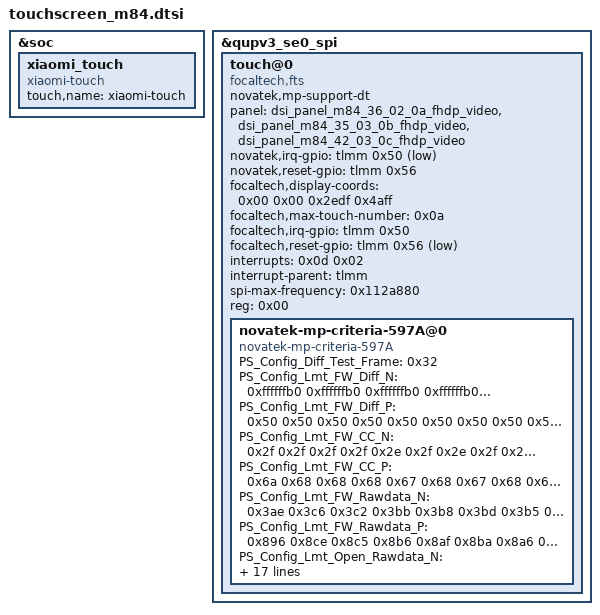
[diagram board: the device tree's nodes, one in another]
&soc {
    xiaomi_touch {
        touch,name = "xiaomi-touch";
        compatible = "xiaomi-touch";
        status = "okay";
    };
};

&qupv3_se0_spi {
    touch@0 {
        novatek,mp-support-dt;
        panel = <&dsi_panel_m84_36_02_0a_fhdp_video &dsi_panel_m84_35_03_0b_fhdp_video &dsi_panel_m84_42_03_0c_fhdp_video>;
        novatek,irq-gpio = <&tlmm 0x50 0x2001>;
        novatek,reset-gpio = <&tlmm 0x56 0x00>;
        focaltech,display-coords = <0x00 0x00 0x2edf 0x4aff>;
        focaltech,max-touch-number = <0x0a>;
        focaltech,irq-gpio = <&tlmm 0x50 0x02>;
        focaltech,reset-gpio = <&tlmm 0x56 0x01>;
        interrupts = <0x0d 0x02>;
        interrupt-parent = <&tlmm>;
        spi-max-frequency = <0x112a880>;
        status = "ok";
        reg = <0x00>;
        compatible = "focaltech,fts", "novatek,NVT-ts-spi";

        novatek-mp-criteria-597A@0 {
            PS_Config_Diff_Test_Frame = <0x32>;
            PS_Config_Lmt_FW_Diff_N = <0xffffffb0 0xffffffb0 0xffffffb0 0xffffffb0 0xffffffb0 0xffffffb0 0xffffffb0 0xffffffb0 0xffffffb0 0xffffffb0 0xffffffb0 0xffffffb0 0xffffffb0 0xffffffb0 0xffffffb0 0xffffffb0 0xffffffb0 0xffffffb0 0xffffffb0 0xffffffb0 0xffffffb0 0xffffffb0 0xffffffb0 0xffffffb0 0xffffffb0 0xffffffb0 0xffffffb0 0xffffffb0 0xffffffb0 0xffffffb0 0xffffffb0 0xffffffb0 0xffffffb0 0xffffffb0 0xffffffb0 0xffffffb0 0xffffffb0 0xffffffb0 0xffffffb0 0xffffffb0 0xffffffb0 0xffffffb0 0xffffffb0 0xffffffb0 0xffffffb0 0xffffffb0 0xffffffb0 0xffffffb0 0xffffffb0 0xffffffb0 0xffffffb0 0xffffffb0 0xffffffb0 0xffffffb0 0xffffffb0 0xffffffb0 0xffffffb0 0xffffffb0 0xffffffb0 0xffffffb0 0xffffffb0 0xffffffb0 0xffffffb0 0xffffffb0 0xffffffb0 0xffffffb0 0xffffffb0 0xffffffb0 0xffffffb0 0xffffffb0 0xffffffb0 0xffffffb0 0xffffffb0 0xffffffb0 0xffffffb0 0xffffffb0 0xffffffb0 0xffffffb0 0xffffffb0 0xffffffb0 0xffffffb0 0xffffffb0 0xffffffb0 0xffffffb0 0xffffffb0 0xffffffb0 0xffffffb0 0xffffffb0 0xffffffb0 0xffffffb0 0xffffffb0 0xffffffb0 0xffffffb0 0xffffffb0 0xffffffb0 0xffffffb0 0xffffffb0 0xffffffb0 0xffffffb0 0xffffffb0 0xffffffb0 0xffffffb0 0xffffffb0 0xffffffb0 0xffffffb0 0xffffffb0 0xffffffb0 0xffffffb0 0xffffffb0 0xffffffb0 0xffffffb0 0xffffffb0 0xffffffb0 0xffffffb0 0xffffffb0 0xffffffb0 0xffffffb0 0xffffffb0 0xffffffb0 0xffffffb0 0xffffffb0 0xffffffb0 0xffffffb0 0xffffffb0 0xffffffb0 0xffffffb0 0xffffffb0 0xffffffb0 0xffffffb0 0xffffffb0 0xffffffb0 0xffffffb0 0xffffffb0 0xffffffb0 0xffffffb0 0xffffffb0 0xffffffb0 0xffffffb0 0xffffffb0 0xffffffb0 0xffffffb0 0xffffffb0 0xffffffb0 0xffffffb0 0xffffffb0 0xffffffb0 0xffffffb0 0xffffffb0 0xffffffb0 0xffffffb0 0xffffffb0 0xffffffb0 0xffffffb0 0xffffffb0 0xffffffb0 0xffffffb0 0xffffffb0 0xffffffb0 0xffffffb0 0xffffffb0 0xffffffb0 0xffffffb0 0xffffffb0 0xffffffb0 0xffffffb0 0xffffffb0 0xffffffb0 0xffffffb0 0xffffffb0 0xffffffb0 0xffffffb0 0xffffffb0 0xffffffb0 0xffffffb0 0xffffffb0 0xffffffb0 0xffffffb0 0xffffffb0 0xffffffb0 0xffffffb0 0xffffffb0 0xffffffb0 0xffffffb0 0xffffffb0 0xffffffb0 0xffffffb0 0xffffffb0 0xffffffb0 0xffffffb0 0xffffffb0 0xffffffb0 0xffffffb0 0xffffffb0 0xffffffb0 0xffffffb0 0xffffffb0 0xffffffb0 0xffffffb0 0xffffffb0 0xffffffb0 0xffffffb0 0xffffffb0 0xffffffb0 0xffffffb0 0xffffffb0 0xffffffb0 0xffffffb0 0xffffffb0 0xffffffb0 0xffffffb0 0xffffffb0 0xffffffb0 0xffffffb0 0xffffffb0 0xffffffb0 0xffffffb0 0xffffffb0 0xffffffb0 0xffffffb0 0xffffffb0 0xffffffb0 0xffffffb0 0xffffffb0 0xffffffb0 0xffffffb0 0xffffffb0 0xffffffb0 0xffffffb0 0xffffffb0 0xffffffb0 0xffffffb0 0xffffffb0 0xffffffb0 0xffffffb0 0xffffffb0 0xffffffb0 0xffffffb0 0xffffffb0 0xffffffb0 0xffffffb0 0xffffffb0 0xffffffb0 0xffffffb0 0xffffffb0 0xffffffb0 0xffffffb0 0xffffffb0 0xffffffb0 0xffffffb0 0xffffffb0 0xffffffb0 0xffffffb0 0xffffffb0 0xffffffb0 0xffffffb0 0xffffffb0 0xffffffb0 0xffffffb0 0xffffffb0 0xffffffb0 0xffffffb0 0xffffffb0 0xffffffb0 0xffffffb0 0xffffffb0 0xffffffb0 0xffffffb0 0xffffffb0 0xffffffb0 0xffffffb0 0xffffffb0 0xffffffb0 0xffffffb0 0xffffffb0 0xffffffb0 0xffffffb0 0xffffffb0 0xffffffb0 0xffffffb0 0xffffffb0 0xffffffb0 0xffffffb0 0xffffffb0 0xffffffb0 0xffffffb0 0xffffffb0 0xffffffb0 0xffffffb0 0xffffffb0 0xffffffb0 0xffffffb0 0xffffffb0 0xffffffb0 0xffffffb0 0xffffffb0 0xffffffb0 0xffffffb0 0xffffffb0 0xffffffb0 0xffffffb0 0xffffffb0 0xffffffb0 0xffffffb0 0xffffffb0 0xffffffb0 0xffffffb0 0xffffffb0 0xffffffb0 0xffffffb0 0xffffffb0 0xffffffb0 0xffffffb0 0xffffffb0 0xffffffb0 0xffffffb0 0xffffffb0 0xffffffb0 0xffffffb0 0xffffffb0 0xffffffb0 0xffffffb0 0xffffffb0 0xffffffb0 0xffffffb0 0xffffffb0 0xffffffb0 0xffffffb0 0xffffffb0 0xffffffb0 0xffffffb0 0xffffffb0 0xffffffb0 0xffffffb0 0xffffffb0 0xffffffb0 0xffffffb0 0xffffffb0 0xffffffb0 0xffffffb0 0xffffffb0 0xffffffb0 0xffffffb0 0xffffffb0 0xffffffb0 0xffffffb0 0xffffffb0 0xffffffb0 0xffffffb0 0xffffffb0 0xffffffb0 0xffffffb0 0xffffffb0 0xffffffb0 0xffffffb0 0xffffffb0 0xffffffb0 0xffffffb0 0xffffffb0 0xffffffb0 0xffffffb0 0xffffffb0 0xffffffb0 0xffffffb0 0xffffffb0 0xffffffb0 0xffffffb0 0xffffffb0 0xffffffb0 0xffffffb0 0xffffffb0 0xffffffb0 0xffffffb0 0xffffffb0 0xffffffb0 0xffffffb0 0xffffffb0 0xffffffb0 0xffffffb0 0xffffffb0 0xffffffb0 0xffffffb0 0xffffffb0 0xffffffb0 0xffffffb0 0xffffffb0 0xffffffb0 0xffffffb0 0xffffffb0 0xffffffb0 0xffffffb0 0xffffffb0 0xffffffb0 0xffffffb0 0xffffffb0 0xffffffb0 0xffffffb0 0xffffffb0 0xffffffb0 0xffffffb0 0xffffffb0 0xffffffb0 0xffffffb0 0xffffffb0 0xffffffb0 0xffffffb0 0xffffffb0 0xffffffb0 0xffffffb0 0xffffffb0 0xffffffb0 0xffffffb0 0xffffffb0 0xffffffb0 0xffffffb0 0xffffffb0 0xffffffb0 0xffffffb0 0xffffffb0 0xffffffb0 0xffffffb0 0xffffffb0 0xffffffb0 0xffffffb0 0xffffffb0 0xffffffb0 0xffffffb0 0xffffffb0 0xffffffb0 0xffffffb0 0xffffffb0 0xffffffb0 0xffffffb0 0xffffffb0 0xffffffb0 0xffffffb0 0xffffffb0 0xffffffb0 0xffffffb0 0xffffffb0 0xffffffb0 0xffffffb0 0xffffffb0 0xffffffb0 0xffffffb0 0xffffffb0 0xffffffb0 0xffffffb0 0xffffffb0 0xffffffb0 0xffffffb0 0xffffffb0 0xffffffb0 0xffffffb0 0xffffffb0 0xffffffb0 0xffffffb0 0xffffffb0 0xffffffb0 0xffffffb0 0xffffffb0 0xffffffb0 0xffffffb0 0xffffffb0 0xffffffb0 0xffffffb0 0xffffffb0 0xffffffb0 0xffffffb0 0xffffffb0 0xffffffb0 0xffffffb0 0xffffffb0 0xffffffb0 0xffffffb0 0xffffffb0 0xffffffb0 0xffffffb0 0xffffffb0 0xffffffb0 0xffffffb0 0xffffffb0 0xffffffb0 0xffffffb0 0xffffffb0 0xffffffb0 0xffffffb0 0xffffffb0 0xffffffb0 0xffffffb0 0xffffffb0 0xffffffb0 0xffffffb0 0xffffffb0 0xffffffb0 0xffffffb0 0xffffffb0 0xffffffb0 0xffffffb0 0xffffffb0 0xffffffb0 0xffffffb0 0xffffffb0 0xffffffb0 0xffffffb0 0xffffffb0 0xffffffb0 0xffffffb0 0xffffffb0 0xffffffb0 0xffffffb0 0xffffffb0 0xffffffb0 0xffffffb0 0xffffffb0 0xffffffb0 0xffffffb0 0xffffffb0 0xffffffb0 0xffffffb0 0xffffffb0 0xffffffb0 0xffffffb0 0xffffffb0 0xffffffb0 0xffffffb0 0xffffffb0 0xffffffb0 0xffffffb0 0xffffffb0 0xffffffb0 0xffffffb0 0xffffffb0 0xffffffb0 0xffffffb0 0xffffffb0 0xffffffb0 0xffffffb0 0xffffffb0 0xffffffb0 0xffffffb0 0xffffffb0 0xffffffb0 0xffffffb0 0xffffffb0 0xffffffb0 0xffffffb0 0xffffffb0 0xffffffb0 0xffffffb0 0xffffffb0 0xffffffb0 0xffffffb0 0xffffffb0 0xffffffb0 0xffffffb0 0xffffffb0 0xffffffb0 0xffffffb0 0xffffffb0 0xffffffb0 0xffffffb0 0xffffffb0 0xffffffb0 0xffffffb0 0xffffffb0 0xffffffb0 0xffffffb0 0xffffffb0 0xffffffb0 0xffffffb0 0xffffffb0 0xffffffb0 0xffffffb0 0xffffffb0 0xffffffb0 0xffffffb0 0xffffffb0 0xffffffb0 0xffffffb0 0xffffffb0 0xffffffb0 0xffffffb0 0xffffffb0 0xffffffb0 0xffffffb0 0xffffffb0 0xffffffb0 0xffffffb0 0xffffffb0 0xffffffb0 0xffffffb0 0xffffffb0 0xffffffb0 0xffffffb0 0xffffffb0 0xffffffb0 0xffffffb0 0xffffffb0 0xffffffb0 0xffffffb0 0xffffffb0 0xffffffb0 0xffffffb0 0xffffffb0 0xffffffb0 0xffffffb0 0xffffffb0 0xffffffb0 0xffffffb0 0xffffffb0 0xffffffb0 0xffffffb0 0xffffffb0 0xffffffb0 0xffffffb0 0xffffffb0 0xffffffb0 0xffffffb0 0xffffffb0 0xffffffb0 0xffffffb0 0xffffffb0 0xffffffb0 0xffffffb0 0xffffffb0 0xffffffb0 0xffffffb0 0xffffffb0 0xffffffb0 0xffffffb0 0xffffffb0 0xffffffb0 0xffffffb0 0xffffffb0 0xffffffb0 0xffffffb0 0xffffffb0 0xffffffb0 0xffffffb0 0xffffffb0 0xffffffb0 0xffffffb0 0xffffffb0 0xffffffb0 0xffffffb0 0xffffffb0 0xffffffb0 0xffffffb0 0xffffffb0 0xffffffb0 0xffffffb0 0xffffffb0 0xffffffb0 0xffffffb0 0xffffffb0 0xffffffb0 0xffffffb0 0xffffffb0 0xffffffb0 0xffffffb0 0xffffffb0 0xffffffb0 0xffffffb0 0xffffffb0 0xffffffb0 0xffffffb0 0xffffffb0 0xffffffb0 0xffffffb0 0xffffffb0 0xffffffb0 0xffffffb0 0xffffffb0 0xffffffb0 0xffffffb0 0xffffffb0 0xffffffb0 0xffffffb0 0xffffffb0 0xffffffb0 0xffffffb0 0xffffffb0 0xffffffb0 0xffffffb0 0xffffffb0 0xffffffb0 0xffffffb0 0xffffffb0 0xffffffb0 0xffffffb0 0xffffffb0 0xffffffb0 0xffffffb0 0xffffffb0 0xffffffb0 0xffffffb0 0xffffffb0 0xffffffb0 0xffffffb0 0xffffffb0 0xffffffb0 0xffffffb0 0xffffffb0 0xffffffb0 0xffffffb0 0xffffffb0 0xffffffb0 0xffffffb0 0xffffffb0 0xffffffb0 0xffffffb0 0xffffffb0 0xffffffb0 0xffffffb0 0xffffffb0 0xffffffb0 0xffffffb0 0xffffffb0 0xffffffb0 0xffffffb0 0xffffffb0 0xffffffb0 0xffffffb0 0xffffffb0 0xffffffb0 0xffffffb0 0xffffffb0 0xffffffb0 0xffffffb0 0xffffffb0 0xffffffb0 0xffffffb0 0xffffffb0 0xffffffb0 0xffffffb0 0xffffffb0 0xffffffb0 0xffffffb0 0xffffffb0 0xffffffb0 0xffffffb0 0xffffffb0 0xffffffb0 0xffffffb0 0xffffffb0 0xffffffb0 0xffffffb0 0xffffffb0 0xffffffb0 0xffffffb0 0xffffffb0 0xffffffb0 0xffffffb0 0xffffffb0 0xffffffb0 0xffffffb0 0xffffffb0 0xffffffb0 0xffffffb0 0xffffffb0 0xffffffb0 0xffffffb0 0xffffffb0 0xffffffb0 0xffffffb0 0xffffffb0 0xffffffb0 0xffffffb0 0xffffffb0 0xffffffb0 0xffffffb0 0xffffffb0 0xffffffb0 0xffffffb0 0xffffffb0 0xffffffb0 0xffffffb0 0xffffffb0 0xffffffb0 0xffffffb0 0xffffffb0 0xffffffb0 0xffffffb0 0xffffffb0 0xffffffb0 0xffffffb0 0xffffffb0 0xffffffb0 0xffffffb0 0xffffffb0 0xffffffb0 0xffffffb0 0xffffffb0 0xffffffb0 0xffffffb0 0xffffffb0 0xffffffb0 0xffffffb0 0xffffffb0 0xffffffb0 0xffffffb0 0xffffffb0 0xffffffb0 0xffffffb0 0xffffffb0 0xffffffb0 0xffffffb0 0xffffffb0 0xffffffb0 0xffffffb0 0xffffffb0 0xffffffb0 0xffffffb0 0xffffffb0 0xffffffb0 0xffffffb0 0xffffffb0 0xffffffb0 0xffffffb0 0xffffffb0 0xffffffb0 0xffffffb0 0xffffffb0 0xffffffb0 0xffffffb0 0xffffffb0 0xffffffb0 0xffffffb0 0xffffffb0 0xffffffb0 0xffffffb0 0xffffffb0 0xffffffb0 0xffffffb0 0xffffffb0 0xffffffb0 0xffffffb0 0xffffffb0 0xffffffb0 0xffffffb0 0xffffffb0 0xffffffb0 0xffffffb0 0xffffffb0 0xffffffb0 0xffffffb0 0xffffffb0 0xffffffb0 0xffffffb0 0xffffffb0 0xffffffb0 0xffffffb0 0xffffffb0 0xffffffb0 0xffffffb0 0xffffffb0 0xffffffb0 0xffffffb0 0xffffffb0 0xffffffb0 0xffffffb0 0xffffffb0 0xffffffb0 0xffffffb0 0xffffffb0 0xffffffb0 0xffffffb0 0xffffffb0 0xffffffb0 0xffffffb0 0xffffffb0 0xffffffb0 0xffffffb0 0xffffffb0 0xffffffb0 0xffffffb0 0xffffffb0 0xffffffb0 0xffffffb0 0xffffffb0 0xffffffb0 0xffffffb0 0xffffffb0 0xffffffb0 0xffffffb0 0xffffffb0 0xffffffb0 0xffffffb0 0xffffffb0 0xffffffb0 0xffffffb0 0xffffffb0 0xffffffb0 0xffffffb0 0xffffffb0 0xffffffb0 0xffffffb0 0xffffffb0 0xffffffb0 0xffffffb0 0xffffffb0 0xffffffb0 0xffffffb0 0xffffffb0 0xffffffb0 0xffffffb0 0xffffffb0 0xffffffb0 0xffffffb0 0xffffffb0 0xffffffb0 0xffffffb0 0xffffffb0 0xffffffb0 0xffffffb0 0xffffffb0 0xffffffb0 0xffffffb0 0xffffffb0 0xffffffb0 0xffffffb0 0xffffffb0 0xffffffb0 0xffffffb0 0xffffffb0 0xffffffb0 0xffffffb0 0xffffffb0 0xffffffb0 0xffffffb0 0xffffffb0 0xffffffb0 0xffffffb0 0xffffffb0 0xffffffb0 0xffffffb0 0xffffffb0 0xffffffb0 0xffffffb0 0xffffffb0 0xffffffb0 0xffffffb0 0xffffffb0 0xffffffb0 0xffffffb0 0xffffffb0 0xffffffb0 0xffffffb0 0xffffffb0 0xffffffb0 0xffffffb0 0xffffffb0 0xffffffb0 0xffffffb0 0xffffffb0 0xffffffb0 0xffffffb0 0xffffffb0 0xffffffb0 0xffffffb0 0xffffffb0 0xffffffb0 0xffffffb0 0xffffffb0 0xffffffb0 0xffffffb0 0xffffffb0 0xffffffb0 0xffffffb0 0xffffffb0 0xffffffb0 0xffffffb0 0xffffffb0 0xffffffb0 0xffffffb0 0xffffffb0 0xffffffb0 0xffffffb0 0xffffffb0 0xffffffb0 0xffffffb0 0xffffffb0 0xffffffb0 0xffffffb0 0xffffffb0 0xffffffb0 0xffffffb0 0xffffffb0 0xffffffb0 0xffffffb0 0xffffffb0 0xffffffb0 0xffffffb0 0xffffffb0 0xffffffb0 0xffffffb0 0xffffffb0 0xffffffb0 0xffffffb0 0xffffffb0 0xffffffb0 0xffffffb0 0xffffffb0 0xffffffb0 0xffffffb0 0xffffffb0 0xffffffb0 0xffffffb0 0xffffffb0 0xffffffb0 0xffffffb0 0xffffffb0 0xffffffb0 0xffffffb0 0xffffffb0 0xffffffb0 0xffffffb0 0xffffffb0 0xffffffb0 0xffffffb0 0xffffffb0 0xffffffb0 0xffffffb0 0xffffffb0 0xffffffb0 0xffffffb0 0xffffffb0 0xffffffb0 0xffffffb0 0xffffffb0 0xffffffb0 0xffffffb0 0xffffffb0 0xffffffb0 0xffffffb0 0xffffffb0 0xffffffb0 0xffffffb0 0xffffffb0 0xffffffb0 0xffffffb0 0xffffffb0 0xffffffb0 0xffffffb0 0xffffffb0 0xffffffb0 0xffffffb0 0xffffffb0 0xffffffb0 0xffffffb0 0xffffffb0 0xffffffb0 0xffffffb0 0xffffffb0 0xffffffb0 0xffffffb0 0xffffffb0 0xffffffb0 0xffffffb0 0xffffffb0 0xffffffb0 0xffffffb0 0xffffffb0 0xffffffb0 0xffffffb0 0xffffffb0 0xffffffb0 0xffffffb0 0xffffffb0 0xffffffb0 0xffffffb0 0xffffffb0 0xffffffb0 0xffffffb0 0xffffffb0 0xffffffb0 0xffffffb0 0xffffffb0 0xffffffb0 0xffffffb0 0xffffffb0 0xffffffb0 0xffffffb0 0xffffffb0 0xffffffb0 0xffffffb0 0xffffffb0 0xffffffb0 0xffffffb0 0xffffffb0 0xffffffb0 0xffffffb0 0xffffffb0 0xffffffb0 0xffffffb0 0xffffffb0 0xffffffb0 0xffffffb0 0xffffffb0 0xffffffb0 0xffffffb0 0xffffffb0 0xffffffb0 0xffffffb0 0xffffffb0 0xffffffb0 0xffffffb0 0xffffffb0 0xffffffb0 0xffffffb0 0xffffffb0 0xffffffb0 0xffffffb0 0xffffffb0 0xffffffb0 0xffffffb0 0xffffffb0 0xffffffb0 0xffffffb0 0xffffffb0 0xffffffb0 0xffffffb0 0xffffffb0 0xffffffb0 0xffffffb0 0xffffffb0 0xffffffb0 0xffffffb0 0xffffffb0 0xffffffb0 0xffffffb0 0xffffffb0 0xffffffb0 0xffffffb0 0xffffffb0 0xffffffb0 0xffffffb0 0xffffffb0 0xffffffb0 0xffffffb0 0xffffffb0 0xffffffb0 0xffffffb0 0xffffffb0 0xffffffb0 0xffffffb0 0xffffffb0 0xffffffb0 0xffffffb0 0xffffffb0 0xffffffb0 0xffffffb0 0xffffffb0 0xffffffb0 0xffffffb0 0xffffffb0 0xffffffb0 0xffffffb0 0xffffffb0 0xffffffb0 0xffffffb0 0xffffffb0 0xffffffb0 0xffffffb0 0xffffffb0 0xffffffb0 0xffffffb0 0xffffffb0 0xffffffb0 0xffffffb0 0xffffffb0 0xffffffb0 0xffffffb0 0xffffffb0 0xffffffb0 0xffffffb0 0xffffffb0 0xffffffb0 0xffffffb0 0xffffffb0 0xffffffb0 0xffffffb0 0xffffffb0 0xffffffb0 0xffffffb0 0xffffffb0 0xffffffb0 0xffffffb0 0xffffffb0 0xffffffb0 0xffffffb0 0xffffffb0 0xffffffb0 0xffffffb0 0xffffffb0 0xffffffb0 0xffffffb0 0xffffffb0 0xffffffb0 0xffffffb0 0xffffffb0 0xffffffb0 0xffffffb0 0xffffffb0 0xffffffb0 0xffffffb0 0xffffffb0 0xffffffb0 0xffffffb0 0xffffffb0 0xffffffb0 0xffffffb0 0xffffffb0 0xffffffb0 0xffffffb0 0xffffffb0 0xffffffb0 0xffffffb0 0xffffffb0 0xffffffb0 0xffffffb0 0xffffffb0 0xffffffb0 0xffffffb0 0xffffffb0 0xffffffb0 0xffffffb0 0xffffffb0 0xffffffb0 0xffffffb0 0xffffffb0 0xffffffb0 0xffffffb0 0xffffffb0 0xffffffb0 0xffffffb0 0xffffffb0 0xffffffb0 0xffffffb0 0xffffffb0 0xffffffb0 0xffffffb0 0xffffffb0 0xffffffb0 0xffffffb0 0xffffffb0 0xffffffb0 0xffffffb0 0xffffffb0 0xffffffb0 0xffffffb0 0xffffffb0 0xffffffb0 0xffffffb0 0xffffffb0 0xffffffb0 0xffffffb0 0xffffffb0 0xffffffb0 0xffffffb0 0xffffffb0 0xffffffb0 0xffffffb0 0xffffffb0 0xffffffb0 0xffffffb0 0xffffffb0 0xffffffb0 0xffffffb0 0xffffffb0 0xffffffb0 0xffffffb0 0xffffffb0 0xffffffb0 0xffffffb0 0xffffffb0 0xffffffb0 0xffffffb0 0xffffffb0 0xffffffb0 0xffffffb0 0xffffffb0 0xffffffb0 0xffffffb0 0xffffffb0 0xffffffb0 0xffffffb0 0xffffffb0 0xffffffb0 0xffffffb0 0xffffffb0 0xffffffb0 0xffffffb0 0xffffffb0 0xffffffb0 0xffffffb0 0xffffffb0 0xffffffb0 0xffffffb0 0xffffffb0 0xffffffb0 0xffffffb0 0xffffffb0 0xffffffb0 0xffffffb0 0xffffffb0 0xffffffb0 0xffffffb0 0xffffffb0 0xffffffb0 0xffffffb0 0xffffffb0 0xffffffb0 0xffffffb0 0xffffffb0 0xffffffb0 0xffffffb0 0xffffffb0 0xffffffb0 0xffffffb0 0xffffffb0 0xffffffb0 0xffffffb0 0xffffffb0 0xffffffb0 0xffffffb0 0xffffffb0 0xffffffb0 0xffffffb0 0xffffffb0 0xffffffb0 0xffffffb0 0xffffffb0 0xffffffb0 0xffffffb0 0xffffffb0 0xffffffb0 0xffffffb0 0xffffffb0 0xffffffb0 0xffffffb0 0xffffffb0 0xffffffb0 0xffffffb0 0xffffffb0 0xffffffb0 0xffffffb0 0xffffffb0 0xffffffb0 0xffffffb0 0xffffffb0 0xffffffb0 0xffffffb0 0xffffffb0 0xffffffb0 0xffffffb0 0xffffffb0 0xffffffb0 0xffffffb0 0xffffffb0 0xffffffb0 0xffffffb0 0xffffffb0 0xffffffb0 0xffffffb0 0xffffffb0 0xffffffb0 0xffffffb0 0xffffffb0 0xffffffb0 0xffffffb0 0xffffffb0 0xffffffb0 0xffffffb0 0xffffffb0 0xffffffb0 0xffffffb0 0xffffffb0 0xffffffb0 0xffffffb0 0xffffffb0 0xffffffb0 0xffffffb0 0xffffffb0 0xffffffb0 0xffffffb0 0xffffffb0 0xffffffb0 0xffffffb0 0xffffffb0 0xffffffb0 0xffffffb0 0xffffffb0 0xffffffb0 0xffffffb0 0xffffffb0 0xffffffb0 0xffffffb0 0xffffffb0 0xffffffb0 0xffffffb0 0xffffffb0 0xffffffb0 0xffffffb0 0xffffffb0 0xffffffb0 0xffffffb0 0xffffffb0 0xffffffb0 0xffffffb0 0xffffffb0 0xffffffb0 0xffffffb0 0xffffffb0 0xffffffb0 0xffffffb0 0xffffffb0 0xffffffb0 0xffffffb0 0xffffffb0 0xffffffb0 0xffffffb0 0xffffffb0 0xffffffb0 0xffffffb0 0xffffffb0 0xffffffb0 0xffffffb0 0xffffffb0 0xffffffb0 0xffffffb0 0xffffffb0 0xffffffb0 0xffffffb0 0xffffffb0 0xffffffb0 0xffffffb0 0xffffffb0 0xffffffb0 0xffffffb0 0xffffffb0 0xffffffb0 0xffffffb0 0xffffffb0 0xffffffb0 0xffffffb0 0xffffffb0 0xffffffb0 0xffffffb0 0xffffffb0 0xffffffb0 0xffffffb0 0xffffffb0 0xffffffb0 0xffffffb0 0xffffffb0 0xffffffb0 0xffffffb0 0xffffffb0 0xffffffb0 0xffffffb0 0xffffffb0 0xffffffb0 0xffffffb0 0xffffffb0 0xffffffb0 0xffffffb0 0xffffffb0 0xffffffb0 0xffffffb0 0xffffffb0 0xffffffb0 0xffffffb0 0xffffffb0 0xffffffb0 0xffffffb0 0xffffffb0 0xffffffb0 0xffffffb0 0xffffffb0 0xffffffb0 0xffffffb0 0xffffffb0 0xffffffb0 0xffffffb0 0xffffffb0 0xffffffb0 0xffffffb0 0xffffffb0 0xffffffb0 0xffffffb0 0xffffffb0 0xffffffb0 0xffffffb0 0xffffffb0 0xffffffb0 0xffffffb0 0xffffffb0 0xffffffb0 0xffffffb0 0xffffffb0 0xffffffb0 0xffffffb0 0xffffffb0 0xffffffb0 0xffffffb0 0xffffffb0 0xffffffb0 0xffffffb0 0xffffffb0 0xffffffb0 0xffffffb0 0xffffffb0 0xffffffb0 0xffffffb0 0xffffffb0 0xffffffb0 0xffffffb0 0xffffffb0 0xffffffb0 0xffffffb0 0xffffffb0 0xffffffb0 0xffffffb0 0xffffffb0 0xffffffb0 0xffffffb0 0xffffffb0 0xffffffb0 0xffffffb0 0xffffffb0 0xffffffb0 0xffffffb0 0xffffffb0 0xffffffb0 0xffffffb0 0xffffffb0 0xffffffb0 0xffffffb0 0xffffffb0 0xffffffb0 0xffffffb0 0xffffffb0 0xffffffb0 0xffffffb0 0xffffffb0 0xffffffb0 0xffffffb0 0xffffffb0 0xffffffb0 0xffffffb0 0xffffffb0 0xffffffb0 0xffffffb0 0xffffffb0 0xffffffb0 0xffffffb0 0xffffffb0 0xffffffb0 0xffffffb0 0xffffffb0 0xffffffb0 0xffffffb0 0xffffffb0 0xffffffb0 0xffffffb0 0xffffffb0 0xffffffb0 0xffffffb0 0xffffffb0 0xffffffb0 0xffffffb0 0xffffffb0 0xffffffb0 0xffffffb0 0xffffffb0 0xffffffb0 0xffffffb0 0xffffffb0 0xffffffb0 0xffffffb0 0xffffffb0 0xffffffb0 0xffffffb0 0xffffffb0 0xffffffb0 0xffffffb0 0xffffffb0 0xffffffb0 0xffffffb0 0xffffffb0 0xffffffb0 0xffffffb0 0xffffffb0 0xffffffb0 0xffffffb0 0xffffffb0 0xffffffb0 0xffffffb0 0xffffffb0 0xffffffb5 0xffffffb5 0xffffffb5>;
            PS_Config_Lmt_FW_Diff_P = <0x50 0x50 0x50 0x50 0x50 0x50 0x50 0x50 0x50 0x50 0x50 0x50 0x50 0x50 0x50 0x50 0x50 0x50 0x50 0x50 0x50 0x50 0x50 0x50 0x50 0x50 0x50 0x50 0x50 0x50 0x50 0x50 0x50 0x50 0x50 0x50 0x50 0x50 0x50 0x50 0x50 0x50 0x50 0x50 0x50 0x50 0x50 0x50 0x50 0x50 0x50 0x50 0x50 0x50 0x50 0x50 0x50 0x50 0x50 0x50 0x50 0x50 0x50 0x50 0x50 0x50 0x50 0x50 0x50 0x50 0x50 0x50 0x50 0x50 0x50 0x50 0x50 0x50 0x50 0x50 0x50 0x50 0x50 0x50 0x50 0x50 0x50 0x50 0x50 0x50 0x50 0x50 0x50 0x50 0x50 0x50 0x50 0x50 0x50 0x50 0x50 0x50 0x50 0x50 0x50 0x50 0x50 0x50 0x50 0x50 0x50 0x50 0x50 0x50 0x50 0x50 0x50 0x50 0x50 0x50 0x50 0x50 0x50 0x50 0x50 0x50 0x50 0x50 0x50 0x50 0x50 0x50 0x50 0x50 0x50 0x50 0x50 0x50 0x50 0x50 0x50 0x50 0x50 0x50 0x50 0x50 0x50 0x50 0x50 0x50 0x50 0x50 0x50 0x50 0x50 0x50 0x50 0x50 0x50 0x50 0x50 0x50 0x50 0x50 0x50 0x50 0x50 0x50 0x50 0x50 0x50 0x50 0x50 0x50 0x50 0x50 0x50 0x50 0x50 0x50 0x50 0x50 0x50 0x50 0x50 0x50 0x50 0x50 0x50 0x50 0x50 0x50 0x50 0x50 0x50 0x50 0x50 0x50 0x50 0x50 0x50 0x50 0x50 0x50 0x50 0x50 0x50 0x50 0x50 0x50 0x50 0x50 0x50 0x50 0x50 0x50 0x50 0x50 0x50 0x50 0x50 0x50 0x50 0x50 0x50 0x50 0x50 0x50 0x50 0x50 0x50 0x50 0x50 0x50 0x50 0x50 0x50 0x50 0x50 0x50 0x50 0x50 0x50 0x50 0x50 0x50 0x50 0x50 0x50 0x50 0x50 0x50 0x50 0x50 0x50 0x50 0x50 0x50 0x50 0x50 0x50 0x50 0x50 0x50 0x50 0x50 0x50 0x50 0x50 0x50 0x50 0x50 0x50 0x50 0x50 0x50 0x50 0x50 0x50 0x50 0x50 0x50 0x50 0x50 0x50 0x50 0x50 0x50 0x50 0x50 0x50 0x50 0x50 0x50 0x50 0x50 0x50 0x50 0x50 0x50 0x50 0x50 0x50 0x50 0x50 0x50 0x50 0x50 0x50 0x50 0x50 0x50 0x50 0x50 0x50 0x50 0x50 0x50 0x50 0x50 0x50 0x50 0x50 0x50 0x50 0x50 0x50 0x50 0x50 0x50 0x50 0x50 0x50 0x50 0x50 0x50 0x50 0x50 0x50 0x50 0x50 0x50 0x50 0x50 0x50 0x50 0x50 0x50 0x50 0x50 0x50 0x50 0x50 0x50 0x50 0x50 0x50 0x50 0x50 0x50 0x50 0x50 0x50 0x50 0x50 0x50 0x50 0x50 0x50 0x50 0x50 0x50 0x50 0x50 0x50 0x50 0x50 0x50 0x50 0x50 0x50 0x50 0x50 0x50 0x50 0x50 0x50 0x50 0x50 0x50 0x50 0x50 0x50 0x50 0x50 0x50 0x50 0x50 0x50 0x50 0x50 0x50 0x50 0x50 0x50 0x50 0x50 0x50 0x50 0x50 0x50 0x50 0x50 0x50 0x50 0x50 0x50 0x50 0x50 0x50 0x50 0x50 0x50 0x50 0x50 0x50 0x50 0x50 0x50 0x50 0x50 0x50 0x50 0x50 0x50 0x50 0x50 0x50 0x50 0x50 0x50 0x50 0x50 0x50 0x50 0x50 0x50 0x50 0x50 0x50 0x50 0x50 0x50 0x50 0x50 0x50 0x50 0x50 0x50 0x50 0x50 0x50 0x50 0x50 0x50 0x50 0x50 0x50 0x50 0x50 0x50 0x50 0x50 0x50 0x50 0x50 0x50 0x50 0x50 0x50 0x50 0x50 0x50 0x50 0x50 0x50 0x50 0x50 0x50 0x50 0x50 0x50 0x50 0x50 0x50 0x50 0x50 0x50 0x50 0x50 0x50 0x50 0x50 0x50 0x50 0x50 0x50 0x50 0x50 0x50 0x50 0x50 0x50 0x50 0x50 0x50 0x50 0x50 0x50 0x50 0x50 0x50 0x50 0x50 0x50 0x50 0x50 0x50 0x50 0x50 0x50 0x50 0x50 0x50 0x50 0x50 0x50 0x50 0x50 0x50 0x50 0x50 0x50 0x50 0x50 0x50 0x50 0x50 0x50 0x50 0x50 0x50 0x50 0x50 0x50 0x50 0x50 0x50 0x50 0x50 0x50 0x50 0x50 0x50 0x50 0x50 0x50 0x50 0x50 0x50 0x50 0x50 0x50 0x50 0x50 0x50 0x50 0x50 0x50 0x50 0x50 0x50 0x50 0x50 0x50 0x50 0x50 0x50 0x50 0x50 0x50 0x50 0x50 0x50 0x50 0x50 0x50 0x50 0x50 0x50 0x50 0x50 0x50 0x50 0x50 0x50 0x50 0x50 0x50 0x50 0x50 0x50 0x50 0x50 0x50 0x50 0x50 0x50 0x50 0x50 0x50 0x50 0x50 0x50 0x50 0x50 0x50 0x50 0x50 0x50 0x50 0x50 0x50 0x50 0x50 0x50 0x50 0x50 0x50 0x50 0x50 0x50 0x50 0x50 0x50 0x50 0x50 0x50 0x50 0x50 0x50 0x50 0x50 0x50 0x50 0x50 0x50 0x50 0x50 0x50 0x50 0x50 0x50 0x50 0x50 0x50 0x50 0x50 0x50 0x50 0x50 0x50 0x50 0x50 0x50 0x50 0x50 0x50 0x50 0x50 0x50 0x50 0x50 0x50 0x50 0x50 0x50 0x50 0x50 0x50 0x50 0x50 0x50 0x50 0x50 0x50 0x50 0x50 0x50 0x50 0x50 0x50 0x50 0x50 0x50 0x50 0x50 0x50 0x50 0x50 0x50 0x50 0x50 0x50 0x50 0x50 0x50 0x50 0x50 0x50 0x50 0x50 0x50 0x50 0x50 0x50 0x50 0x50 0x50 0x50 0x50 0x50 0x50 0x50 0x50 0x50 0x50 0x50 0x50 0x50 0x50 0x50 0x50 0x50 0x50 0x50 0x50 0x50 0x50 0x50 0x50 0x50 0x50 0x50 0x50 0x50 0x50 0x50 0x50 0x50 0x50 0x50 0x50 0x50 0x50 0x50 0x50 0x50 0x50 0x50 0x50 0x50 0x50 0x50 0x50 0x50 0x50 0x50 0x50 0x50 0x50 0x50 0x50 0x50 0x50 0x50 0x50 0x50 0x50 0x50 0x50 0x50 0x50 0x50 0x50 0x50 0x50 0x50 0x50 0x50 0x50 0x50 0x50 0x50 0x50 0x50 0x50 0x50 0x50 0x50 0x50 0x50 0x50 0x50 0x50 0x50 0x50 0x50 0x50 0x50 0x50 0x50 0x50 0x50 0x50 0x50 0x50 0x50 0x50 0x50 0x50 0x50 0x50 0x50 0x50 0x50 0x50 0x50 0x50 0x50 0x50 0x50 0x50 0x50 0x50 0x50 0x50 0x50 0x50 0x50 0x50 0x50 0x50 0x50 0x50 0x50 0x50 0x50 0x50 0x50 0x50 0x50 0x50 0x50 0x50 0x50 0x50 0x50 0x50 0x50 0x50 0x50 0x50 0x50 0x50 0x50 0x50 0x50 0x50 0x50 0x50 0x50 0x50 0x50 0x50 0x50 0x50 0x50 0x50 0x50 0x50 0x50 0x50 0x50 0x50 0x50 0x50 0x50 0x50 0x50 0x50 0x50 0x50 0x50 0x50 0x50 0x50 0x50 0x50 0x50 0x50 0x50 0x50 0x50 0x50 0x50 0x50 0x50 0x50 0x50 0x50 0x50 0x50 0x50 0x50 0x50 0x50 0x50 0x50 0x50 0x50 0x50 0x50 0x50 0x50 0x50 0x50 0x50 0x50 0x50 0x50 0x50 0x50 0x50 0x50 0x50 0x50 0x50 0x50 0x50 0x50 0x50 0x50 0x50 0x50 0x50 0x50 0x50 0x50 0x50 0x50 0x50 0x50 0x50 0x50 0x50 0x50 0x50 0x50 0x50 0x50 0x50 0x50 0x50 0x50 0x50 0x50 0x50 0x50 0x50 0x50 0x50 0x50 0x50 0x50 0x50 0x50 0x50 0x50 0x50 0x50 0x50 0x50 0x50 0x50 0x50 0x50 0x50 0x50 0x50 0x50 0x50 0x50 0x50 0x50 0x50 0x50 0x50 0x50 0x50 0x50 0x50 0x50 0x50 0x50 0x50 0x50 0x50 0x50 0x50 0x50 0x50 0x50 0x50 0x50 0x50 0x50 0x50 0x50 0x50 0x50 0x50 0x50 0x50 0x50 0x50 0x50 0x50 0x50 0x50 0x50 0x50 0x50 0x50 0x50 0x50 0x50 0x50 0x50 0x50 0x50 0x50 0x50 0x50 0x50 0x50 0x50 0x50 0x50 0x50 0x50 0x50 0x50 0x50 0x50 0x50 0x50 0x50 0x50 0x50 0x50 0x50 0x50 0x50 0x50 0x50 0x50 0x50 0x50 0x50 0x50 0x50 0x50 0x50 0x50 0x50 0x50 0x50 0x50 0x50 0x50 0x50 0x50 0x50 0x50 0x50 0x50 0x50 0x50 0x50 0x50 0x50 0x50 0x50 0x50 0x50 0x50 0x50 0x50 0x50 0x50 0x50 0x50 0x50 0x50 0x50 0x50 0x50 0x50 0x50 0x50 0x50 0x50 0x50 0x50 0x50 0x50 0x50 0x50 0x50 0x50 0x50 0x50 0x50 0x50 0x50 0x50 0x50 0x50 0x50 0x50 0x50 0x50 0x50 0x50 0x50 0x50 0x50 0x50 0x50 0x50 0x50 0x50 0x50 0x50 0x50 0x50 0x50 0x50 0x50 0x50 0x50 0x50 0x50 0x50 0x50 0x50 0x50 0x50 0x50 0x50 0x50 0x50 0x50 0x50 0x50 0x50 0x50 0x50 0x50 0x50 0x50 0x50 0x50 0x50 0x50 0x50 0x50 0x50 0x50 0x50 0x50 0x50 0x50 0x50 0x50 0x50 0x50 0x50 0x50 0x50 0x50 0x50 0x50 0x50 0x50 0x50 0x50 0x50 0x50 0x50 0x50 0x50 0x50 0x50 0x50 0x50 0x50 0x50 0x50 0x50 0x50 0x50 0x50 0x50 0x50 0x50 0x50 0x50 0x50 0x50 0x50 0x50 0x50 0x50 0x50 0x50 0x50 0x50 0x50 0x50 0x50 0x50 0x50 0x50 0x50 0x50 0x50 0x50 0x50 0x50 0x50 0x50 0x50 0x50 0x50 0x50 0x50 0x50 0x50 0x50 0x50 0x50 0x50 0x50 0x50 0x50 0x50 0x50 0x50 0x50 0x50 0x50 0x50 0x50 0x50 0x50 0x50 0x50 0x50 0x50 0x50 0x50 0x50 0x50 0x50 0x50 0x50 0x50 0x50 0x50 0x50 0x50 0x50 0x50 0x50 0x50 0x50 0x50 0x50 0x50 0x50 0x50 0x50 0x50 0x50 0x50 0x50 0x50 0x50 0x50 0x50 0x50 0x50 0x50 0x50 0x50 0x50 0x50 0x50 0x50 0x50 0x50 0x50 0x50 0x50 0x50 0x50 0x50 0x50 0x50 0x50 0x50 0x50 0x50 0x50 0x50 0x50 0x50 0x50 0x50 0x50 0x50 0x50 0x50 0x50 0x50 0x50 0x50 0x50 0x50 0x50 0x50 0x50 0x50 0x50 0x50 0x50 0x50 0x50 0x50 0x50 0x50 0x50 0x50 0x50 0x50 0x50 0x50 0x50 0x50 0x50 0x50 0x50 0x50 0x50 0x50 0x50 0x50 0x50 0x50 0x50 0x50 0x50 0x50 0x50 0x50 0x50 0x50 0x50 0x50 0x50 0x50 0x50 0x50 0x50 0x50 0x50 0x50 0x50 0x50 0x50 0x50 0x50 0x50 0x50 0x50 0x50 0x50 0x50 0x50 0x50 0x50 0x50 0x50 0x50 0x50 0x50 0x50 0x50 0x50 0x50 0x50 0x50 0x50 0x50 0x50 0x50 0x50 0x50 0x50 0x50 0x50 0x50 0x50 0x50 0x50 0x50 0x50 0x50 0x50 0x50 0x50 0x50 0x50 0x50 0x50 0x50 0x50 0x50 0x50 0x50 0x50 0x50 0x50 0x50 0x50 0x50 0x50 0x50 0x50 0x50 0x50 0x50 0x50 0x50 0x50 0x50 0x50 0x50 0x50 0x50 0x50 0x50 0x50 0x50 0x50 0x50 0x50 0x50 0x50 0x50 0x50 0x50 0x50 0x50 0x50 0x50 0x50 0x50 0x50 0x50 0x50 0x50 0x50 0x50 0x50 0x50 0x50 0x50 0x50 0x50 0x50 0x50 0x50 0x50 0x50 0x50 0x50 0x50 0x50 0x50 0x50 0x50 0x50 0x50 0x50 0x50 0x50 0x50 0x50 0x50 0x50 0x50 0x50 0x50 0x50 0x50 0x50 0x50 0x50 0x50 0x50 0x50 0x50 0x50 0x50 0x50 0x50 0x50 0x50 0x50 0x50 0x50 0x50 0x50 0x50 0x50 0x50 0x50 0x50 0x50 0x50 0x50 0x50 0x50 0x50 0x50 0x50 0x50 0x50 0x50 0x50 0x50 0x50 0x50 0x50 0x50 0x50 0x50 0x50 0x50 0x50 0x50 0x50 0x50 0x50 0x50 0x50 0x50 0x50 0x50 0x50 0x50 0x50 0x50 0x50 0x50 0x50 0x50 0x50 0x50 0x50 0x50 0x50 0x50 0x50 0x50 0x50 0x50 0x4b 0x4b 0x4b>;
            PS_Config_Lmt_FW_CC_N = <0x2f 0x2f 0x2f 0x2f 0x2e 0x2f 0x2e 0x2f 0x2e 0x2f 0x2f 0x2f 0x2e 0x2f 0x2f 0x2f 0x2f 0x2f 0x2f 0x2f 0x2f 0x2f 0x2f 0x2f 0x2f 0x2f 0x2f 0x2f 0x2f 0x2f 0x2f 0x30 0x2f 0x2d 0x2d 0x2e 0x2d 0x2d 0x2d 0x2d 0x2d 0x2e 0x2e 0x2e 0x2d 0x2e 0x2e 0x2e 0x2f 0x2f 0x2e 0x2f 0x2f 0x2f 0x2e 0x2f 0x2e 0x2e 0x2d 0x2e 0x2e 0x2e 0x2e 0x2f 0x2f 0x2f 0x2f 0x2f 0x2e 0x2f 0x2e 0x2f 0x2e 0x2f 0x2f 0x2f 0x2e 0x2f 0x2f 0x2f 0x2f 0x2f 0x2f 0x2f 0x2f 0x2f 0x2f 0x2f 0x2f 0x2f 0x2f 0x2f 0x2f 0x2f 0x2f 0x2f 0x2f 0x2e 0x2d 0x2e 0x2d 0x2e 0x2d 0x2e 0x2e 0x2e 0x2e 0x2f 0x2e 0x2f 0x2f 0x2f 0x2f 0x2f 0x2f 0x2f 0x2f 0x2f 0x2f 0x2f 0x2f 0x2e 0x2e 0x2e 0x2f 0x2e 0x2e 0x2f 0x2f 0x2e 0x2d 0x2e 0x2d 0x2d 0x2d 0x2e 0x2e 0x2e 0x2e 0x2e 0x2e 0x2e 0x2e 0x2e 0x2e 0x2f 0x2e 0x2e 0x2e 0x2f 0x2e 0x2e 0x2e 0x2e 0x2e 0x2e 0x2e 0x2e 0x2e 0x2f 0x2e 0x2d 0x2d 0x2d 0x2d 0x2d 0x2d 0x2d 0x2d 0x2d 0x2d 0x2d 0x2d 0x2d 0x2d 0x2e 0x2e 0x2e 0x2e 0x2e 0x2e 0x2e 0x2e 0x2d 0x2d 0x2d 0x2d 0x2d 0x2d 0x2d 0x2d 0x2d 0x2f 0x2f 0x2f 0x2f 0x2f 0x2e 0x2e 0x2e 0x2e 0x2e 0x2e 0x2f 0x2f 0x2e 0x2e 0x2e 0x2f 0x2f 0x2f 0x2f 0x2f 0x2f 0x2f 0x2f 0x2f 0x2f 0x2f 0x2f 0x2f 0x2f 0x2f 0x30 0x2f 0x2d 0x2d 0x2e 0x2e 0x2e 0x2d 0x2d 0x2e 0x2e 0x2e 0x2e 0x2e 0x2e 0x2e 0x2e 0x2f 0x2f 0x2f 0x2f 0x2f 0x2f 0x2e 0x2f 0x2e 0x2f 0x2e 0x2f 0x2e 0x2f 0x2e 0x2f 0x2f 0x2f 0x2f 0x2f 0x2e 0x2e 0x2e 0x2f 0x2e 0x2f 0x2f 0x2f 0x2f 0x2f 0x2f 0x2f 0x2f 0x2f 0x2f 0x2f 0x2f 0x2f 0x2f 0x2f 0x2f 0x2f 0x2f 0x2f 0x2f 0x2f 0x2f 0x2f 0x2f 0x2e 0x2d 0x2e 0x2d 0x2e 0x2d 0x2e 0x2e 0x2e 0x2e 0x2f 0x2f 0x2f 0x2f 0x2f 0x2f 0x2f 0x2f 0x2f 0x2f 0x2f 0x2f 0x2f 0x2f 0x2f 0x2e 0x2e 0x2e 0x2f 0x2e 0x2f 0x2f 0x2e 0x2d 0x2d 0x2e 0x2e 0x2d 0x2d 0x2e 0x2e 0x2e 0x2d 0x2e 0x2e 0x2e 0x2d 0x2e 0x2e 0x2e 0x2f 0x2e 0x2e 0x2e 0x2e 0x2e 0x2e 0x2e 0x2f 0x2e 0x2e 0x2e 0x2f 0x2e 0x2d 0x2d 0x2d 0x2d 0x2d 0x2d 0x2d 0x2d 0x2d 0x2d 0x2d 0x2d 0x2e 0x2d 0x2d 0x2e 0x2e 0x2e 0x2f 0x2e 0x2e 0x2e 0x2e 0x2d 0x2d 0x2d 0x2e 0x2d 0x2d 0x2d 0x2e 0x2f 0x2f 0x2e 0x2e 0x2e 0x2e 0x2d 0x2e 0x2e 0x2e 0x2e 0x2e 0x2e 0x2e 0x2e 0x2e 0x2f 0x2f 0x2f 0x2f 0x2f 0x2f 0x2f 0x2e 0x2f 0x2f 0x2f 0x2f 0x2f 0x2f 0x2f 0x2f 0x2f 0x2d 0x2d 0x2d 0x2d 0x2d 0x2d 0x2d 0x2d 0x2e 0x2d 0x2e 0x2e 0x2e 0x2e 0x2e 0x2f 0x2f 0x2e 0x2f 0x2f 0x2f 0x2e 0x2e 0x2e 0x2e 0x2e 0x2e 0x2e 0x2e 0x2e 0x2e 0x2f 0x2f 0x2f 0x2f 0x2e 0x2f 0x2e 0x2f 0x2e 0x2f 0x2f 0x2f 0x2e 0x2e 0x2f 0x2f 0x2f 0x2f 0x2f 0x2f 0x2f 0x2f 0x2f 0x2f 0x2f 0x2f 0x2f 0x2f 0x2f 0x2f 0x2f 0x2f 0x2e 0x2e 0x2d 0x2e 0x2d 0x2d 0x2d 0x2e 0x2e 0x2e 0x2e 0x2f 0x2e 0x2e 0x2f 0x2f 0x2f 0x2f 0x2f 0x2f 0x2f 0x2f 0x2f 0x2f 0x2e 0x2e 0x2e 0x2e 0x2e 0x2f 0x2e 0x2f 0x2e 0x2e 0x2d 0x2e 0x2d 0x2d 0x2d 0x2e 0x2d 0x2d 0x2e 0x2e 0x2d 0x2d 0x2e 0x2d 0x2d 0x2e 0x2e 0x2f 0x2e 0x2e 0x2e 0x2e 0x2e 0x2e 0x2e 0x2e 0x2e 0x2e 0x2e 0x2f 0x2e 0x2d 0x2d 0x2d 0x2d 0x2d 0x2d 0x2d 0x2d 0x2d 0x2d 0x2d 0x2d 0x2d 0x2d 0x2d 0x2d 0x2e 0x2e 0x2e 0x2d 0x2e 0x2d 0x2e 0x2d 0x2d 0x2d 0x2d 0x2d 0x2d 0x2d 0x2e 0x2e 0x2e 0x2e 0x2e 0x2d 0x2e 0x2d 0x2e 0x2e 0x2e 0x2e 0x2e 0x2e 0x2e 0x2e 0x2e 0x2f 0x2e 0x2f 0x2e 0x2f 0x2e 0x2f 0x2e 0x2f 0x2e 0x2f 0x2e 0x2f 0x2e 0x2f 0x2f 0x2e 0x2d 0x2d 0x2d 0x2d 0x2d 0x2d 0x2d 0x2d 0x2d 0x2d 0x2e 0x2d 0x2d 0x2d 0x2e 0x2f 0x2e 0x2f 0x2e 0x2e 0x2e 0x2e 0x2d 0x2e 0x2d 0x2e 0x2d 0x2e 0x2d 0x2e 0x2e 0x2f 0x2f 0x2f 0x2f 0x2e 0x2f 0x2e 0x2e 0x2e 0x2f 0x2e 0x2e 0x2e 0x2f 0x2e 0x2e 0x2e 0x2f 0x2f 0x2e 0x2e 0x2f 0x2f 0x2e 0x2e 0x2e 0x2f 0x2f 0x2f 0x2f 0x2f 0x2f 0x2f 0x2e 0x2d 0x2d 0x2d 0x2e 0x2d 0x2d 0x2d 0x2e 0x2e 0x2e 0x2e 0x2e 0x2e 0x2e 0x2e 0x2e 0x2f 0x2e 0x2e 0x2e 0x2e 0x2d 0x2e 0x2d 0x2e 0x2e 0x2e 0x2e 0x2f 0x2f 0x2f 0x2f 0x2f 0x2f 0x2f 0x2f 0x2f 0x2f 0x2e 0x2f 0x2f 0x2f 0x2e 0x2f 0x2f 0x2e 0x2f 0x2f 0x2f 0x2f 0x2f 0x2f 0x2f 0x2f 0x2f 0x2f 0x2f 0x2f 0x2f 0x2f 0x2f 0x2f 0x2e 0x2e 0x2e 0x2e 0x2d 0x2e 0x2e 0x2e 0x2e 0x2e 0x2f 0x2e 0x2e 0x2f 0x2f 0x2e 0x2f 0x2f 0x2e 0x2f 0x2f 0x2f 0x2e 0x2f 0x2e 0x2e 0x2e 0x2e 0x2e 0x2e 0x2e 0x2f 0x2e 0x2d 0x2e 0x2e 0x2d 0x2d 0x2e 0x2e 0x2d 0x2d 0x2e 0x2e 0x2d 0x2d 0x2e 0x2d 0x2e 0x2e 0x2e 0x2e 0x2e 0x2e 0x2e 0x2e 0x2e 0x2d 0x2e 0x2e 0x2e 0x2e 0x2f 0x2f 0x2e 0x2d 0x2d 0x2d 0x2d 0x2d 0x2d 0x2d 0x2d 0x2d 0x2d 0x2d 0x2d 0x2d 0x2d 0x2d 0x2d 0x2d 0x2e 0x2d 0x2d 0x2d 0x2e 0x2d 0x2d 0x2d 0x2d 0x2d 0x2d 0x2d 0x2d 0x2e 0x2f 0x2e 0x2e 0x2e 0x2e 0x2e 0x2e 0x2e 0x2e 0x2e 0x2e 0x2e 0x2e 0x2e 0x2e 0x2e 0x2e 0x2f 0x2e 0x2e 0x2e 0x2f 0x2f 0x2e 0x2e 0x2e 0x2e 0x2e 0x2e 0x2f 0x2f 0x2f 0x2e 0x2d 0x2d 0x2d 0x2d 0x2d 0x2d 0x2d 0x2d 0x2d 0x2e 0x2e 0x2e 0x2d 0x2e 0x2e 0x2e 0x2e 0x2e 0x2e 0x2e 0x2e 0x2e 0x2d 0x2d 0x2d 0x2d 0x2d 0x2d 0x2d 0x2e 0x2f 0x2f 0x2f 0x2f 0x2f 0x2f 0x2e 0x2e 0x2e 0x2e 0x2e 0x2e 0x2e 0x2e 0x2e 0x2e 0x2e 0x2f 0x2e 0x2e 0x2e 0x2f 0x2e 0x2e 0x2e 0x2f 0x2e 0x2e 0x2f 0x2f 0x2f 0x2f 0x2f 0x2f 0x2d 0x2e 0x2e 0x2d 0x2d 0x2d 0x2d 0x2e 0x2d 0x2e 0x2e 0x2e 0x2d 0x2e 0x2e 0x2e 0x2e 0x2e 0x2e 0x2e 0x2e 0x2d 0x2d 0x2e 0x2d 0x2d 0x2d 0x2e 0x2e 0x2e 0x2f 0x2f 0x2f 0x2f 0x2f 0x2e 0x2f 0x2e 0x2e 0x2f 0x2e 0x2f 0x2e 0x2e 0x2e 0x2e 0x2e 0x2e 0x2e 0x2f 0x2f 0x2f 0x2e 0x2f 0x2f 0x2e 0x2e 0x2f 0x2f 0x2f 0x2f 0x2f 0x2f 0x2f 0x2e 0x2d 0x2d 0x2d 0x2e 0x2d 0x2e 0x2e 0x2e 0x2e 0x2e 0x2e 0x2e 0x2e 0x2e 0x2e 0x2e 0x2f 0x2e 0x2e 0x2e 0x2f 0x2e 0x2e 0x2d 0x2e 0x2e 0x2e 0x2e 0x2e 0x2f 0x2e 0x2d 0x2d 0x2e 0x2d 0x2d 0x2d 0x2d 0x2d 0x2d 0x2d 0x2e 0x2d 0x2d 0x2d 0x2d 0x2d 0x2d 0x2e 0x2d 0x2d 0x2d 0x2e 0x2d 0x2d 0x2d 0x2e 0x2e 0x2d 0x2e 0x2f 0x2f 0x2d 0x2d 0x2c 0x2d 0x2d 0x2d 0x2d 0x2d 0x2d 0x2d 0x2d 0x2d 0x2d 0x2d 0x2d 0x2d 0x2d 0x2d 0x2e 0x2d 0x2d 0x2d 0x2d 0x2d 0x2d 0x2d 0x2d 0x2d 0x2d 0x2d 0x2d 0x2f 0x2f 0x2d 0x2e 0x2e 0x2e 0x2d 0x2e 0x2e 0x2e 0x2d 0x2e 0x2e 0x2e 0x2d 0x2d 0x2e 0x2e 0x2f 0x2e 0x2e 0x2f 0x2f 0x2e 0x2e 0x2e 0x2f 0x2e 0x2e 0x2f 0x2f 0x2e 0x2f 0x2e 0x2d 0x2d 0x2d 0x2d 0x2d 0x2d 0x2d 0x2d 0x2d 0x2d 0x2e 0x2d 0x2d 0x2d 0x2e 0x2e 0x2e 0x2d 0x2e 0x2e 0x2e 0x2d 0x2d 0x2d 0x2e 0x2d 0x2d 0x2d 0x2e 0x2d 0x2f 0x2f 0x2e 0x2f 0x2e 0x2f 0x2d 0x2e 0x2e 0x2e 0x2d 0x2e 0x2e 0x2e 0x2d 0x2d 0x2d 0x2e 0x2e 0x2e 0x2e 0x2f 0x2e 0x2e 0x2e 0x2f 0x2e 0x2e 0x2e 0x2f 0x2f 0x2f 0x2f 0x2e 0x2d 0x2d 0x2d 0x2d 0x2d 0x2d 0x2d 0x2d 0x2d 0x2d 0x2d 0x2d 0x2d 0x2d 0x2d 0x2e 0x2e 0x2d 0x2d 0x2e 0x2e 0x2d 0x2d 0x2e 0x2d 0x2d 0x2d 0x2e 0x2e 0x2e 0x2f 0x2f 0x2f 0x2f 0x2f 0x2e 0x2e 0x2e 0x2e 0x2e 0x2e 0x2e 0x2e 0x2e 0x2e 0x2e 0x2e 0x2f 0x2e 0x2f 0x2f 0x2f 0x2f 0x2f 0x2f 0x2f 0x2e 0x2f 0x2f 0x2f 0x2f 0x2f 0x2f 0x2e 0x2d 0x2d 0x2d 0x2d 0x2d 0x2d 0x2d 0x2d 0x2d 0x2e 0x2e 0x2d 0x2d 0x2e 0x2e 0x2e 0x2e 0x2e 0x2e 0x2e 0x2e 0x2e 0x2e 0x2e 0x2d 0x2e 0x2d 0x2e 0x2e 0x2e 0x2f 0x2e 0x2e 0x2d 0x2d 0x2d 0x2d 0x2d 0x2d 0x2d 0x2d 0x2d 0x2d 0x2d 0x2d 0x2d 0x2d 0x2d 0x2d 0x2d 0x2d 0x2d 0x2d 0x2d 0x2d 0x2d 0x2d 0x2d 0x2e 0x2d 0x2d 0x2e 0x2f 0x2d 0x2d 0x2d 0x2c 0x2d 0x2d 0x2d 0x2c 0x2d 0x2d 0x2d 0x2d 0x2d 0x2d 0x2d 0x2d 0x2d 0x2d 0x2d 0x2d 0x2d 0x2d 0x2d 0x2d 0x2d 0x2d 0x2d 0x2d 0x2d 0x2d 0x2d 0x2f 0x2e 0x2e 0x2e 0x2d 0x2d 0x2e 0x2d 0x2d 0x2d 0x2d 0x2d 0x2d 0x2d 0x2d 0x2d 0x2d 0x2e 0x2e 0x2e 0x2d 0x2e 0x2e 0x2e 0x2d 0x2e 0x2e 0x2e 0x2d 0x2e 0x2f 0x2f 0x2f 0x2d 0x2d 0x2d 0x2c 0x2c 0x2d 0x2d 0x2d 0x2d 0x2d 0x2d 0x2d 0x2d 0x2d 0x2d 0x2d 0x2d 0x2d 0x2e 0x2d 0x2d 0x2d 0x2d 0x2d 0x2d 0x2d 0x2d 0x2d 0x2d 0x2d 0x2d 0x2f 0x2f 0x2f 0x2f 0x2e 0x2e 0x2e 0x2e 0x2d 0x2d 0x2d 0x2e 0x2d 0x2d 0x2d 0x2e 0x2d 0x2e 0x2e 0x2e 0x2e 0x2e 0x2e 0x2e 0x2e 0x2e 0x2d 0x2f 0x2f 0x2f 0x2f 0x2f 0x2f 0x2d 0x2d 0x2d 0x2d 0x2d 0x2d 0x2d 0x2d 0x2d 0x2d 0x2d 0x2d 0x2d 0x2d 0x2d 0x2d 0x2d 0x2d 0x2e 0x2d 0x2d 0x2d 0x2d 0x2d 0x2d 0x2d 0x2d 0x2d 0x2d 0x2d 0x2e 0x2f 0x2f 0x2f 0x2f 0x2e 0x2e 0x2e 0x2e 0x2e 0x2e 0x2e 0x2e 0x2e 0x2e 0x2e 0x2e 0x2e 0x2f 0x2e 0x2f 0x2e 0x2f 0x2e 0x2f 0x2e 0x2f 0x2e 0x2f 0x2e 0x2f 0x2f 0x2f 0x2f 0x2d 0x2d 0x2d 0x2d 0x2d 0x2d 0x2d 0x2d 0x2d 0x2d 0x2d 0x2d 0x2d 0x2d 0x2e 0x2d 0x2e 0x2d 0x2e 0x2d 0x2e 0x2d 0x2e 0x2d 0x2d 0x2d 0x2d 0x2d 0x2e 0x2d 0x2e 0x2f 0x2e 0x2d 0x2d 0x2d 0x2d 0x2d 0x2d 0x2d 0x2d 0x2d 0x2d 0x2d 0x2d 0x2d 0x2d 0x2d 0x2d 0x2d 0x2d 0x2d 0x2e 0x2d 0x2d 0x2d 0x2d 0x2d 0x2d 0x2d 0x2e 0x2e 0x2e 0x2f 0x2d 0x2c 0x2c 0x2d 0x2d 0x2c 0x2d 0x2d 0x2d 0x2d 0x2d 0x2d 0x2d 0x2d 0x2d 0x2d 0x2d 0x2d 0x2d 0x2d 0x2d 0x2d 0x2d 0x2d 0x2d 0x2d 0x2d 0x2c 0x2d 0x2d 0x2d 0x2f 0x00 0x00 0x00>;
            PS_Config_Lmt_FW_CC_P = <0x6a 0x68 0x68 0x68 0x67 0x68 0x67 0x68 0x67 0x68 0x68 0x68 0x67 0x68 0x68 0x68 0x6a 0x6a 0x68 0x6a 0x6a 0x6a 0x68 0x6a 0x68 0x68 0x68 0x6a 0x6a 0x6a 0x68 0x6b 0x68 0x66 0x66 0x67 0x64 0x66 0x66 0x66 0x66 0x67 0x67 0x67 0x66 0x67 0x67 0x67 0x6a 0x68 0x67 0x68 0x68 0x68 0x67 0x68 0x67 0x67 0x66 0x67 0x67 0x67 0x67 0x68 0x68 0x68 0x68 0x68 0x67 0x68 0x67 0x68 0x67 0x68 0x68 0x68 0x67 0x68 0x68 0x68 0x6a 0x6a 0x68 0x6a 0x6a 0x6a 0x68 0x68 0x6a 0x68 0x68 0x68 0x6a 0x6a 0x68 0x6a 0x68 0x67 0x66 0x67 0x66 0x67 0x66 0x67 0x67 0x67 0x67 0x68 0x67 0x68 0x68 0x68 0x6a 0x6a 0x68 0x6a 0x6a 0x68 0x68 0x68 0x68 0x67 0x67 0x67 0x68 0x67 0x67 0x68 0x68 0x67 0x66 0x67 0x66 0x66 0x66 0x67 0x67 0x67 0x67 0x67 0x67 0x67 0x67 0x67 0x67 0x68 0x67 0x67 0x67 0x68 0x67 0x67 0x67 0x67 0x67 0x67 0x67 0x67 0x67 0x68 0x67 0x64 0x64 0x64 0x64 0x64 0x64 0x66 0x66 0x66 0x66 0x66 0x66 0x66 0x66 0x67 0x67 0x67 0x67 0x67 0x67 0x67 0x67 0x66 0x66 0x66 0x66 0x66 0x66 0x66 0x66 0x66 0x6a 0x68 0x68 0x68 0x68 0x67 0x67 0x67 0x67 0x67 0x67 0x68 0x68 0x67 0x67 0x67 0x68 0x6a 0x68 0x6a 0x68 0x6a 0x68 0x6a 0x68 0x6a 0x68 0x6a 0x68 0x6a 0x6a 0x6b 0x6a 0x66 0x66 0x67 0x67 0x67 0x66 0x66 0x67 0x67 0x67 0x67 0x67 0x67 0x67 0x67 0x68 0x6a 0x68 0x68 0x68 0x6a 0x67 0x68 0x67 0x68 0x67 0x68 0x67 0x68 0x67 0x68 0x68 0x68 0x68 0x68 0x67 0x67 0x67 0x68 0x67 0x68 0x68 0x68 0x68 0x68 0x68 0x68 0x6a 0x6a 0x68 0x68 0x6a 0x6a 0x68 0x68 0x68 0x68 0x68 0x68 0x68 0x6a 0x6a 0x6a 0x68 0x67 0x66 0x67 0x66 0x67 0x66 0x67 0x67 0x67 0x67 0x68 0x68 0x68 0x68 0x68 0x68 0x6a 0x68 0x68 0x68 0x68 0x68 0x68 0x68 0x68 0x67 0x67 0x67 0x68 0x67 0x68 0x68 0x67 0x66 0x66 0x67 0x67 0x66 0x66 0x67 0x67 0x67 0x66 0x67 0x67 0x67 0x66 0x67 0x67 0x67 0x68 0x67 0x67 0x67 0x67 0x67 0x67 0x67 0x68 0x67 0x67 0x67 0x68 0x67 0x64 0x64 0x64 0x64 0x66 0x64 0x64 0x66 0x66 0x66 0x66 0x66 0x67 0x66 0x66 0x67 0x67 0x67 0x68 0x67 0x67 0x67 0x67 0x66 0x66 0x66 0x67 0x66 0x64 0x66 0x67 0x68 0x68 0x67 0x67 0x67 0x67 0x66 0x67 0x67 0x67 0x67 0x67 0x67 0x67 0x67 0x67 0x68 0x68 0x68 0x68 0x68 0x68 0x68 0x67 0x68 0x68 0x68 0x68 0x6a 0x68 0x6a 0x6a 0x68 0x66 0x66 0x66 0x66 0x66 0x64 0x66 0x66 0x67 0x66 0x67 0x67 0x67 0x67 0x67 0x68 0x68 0x67 0x68 0x68 0x68 0x67 0x67 0x67 0x67 0x67 0x67 0x67 0x67 0x67 0x67 0x68 0x68 0x68 0x68 0x67 0x68 0x67 0x68 0x67 0x68 0x68 0x68 0x67 0x67 0x68 0x68 0x68 0x68 0x68 0x6a 0x68 0x6a 0x68 0x68 0x68 0x68 0x68 0x68 0x68 0x6a 0x6a 0x6a 0x67 0x67 0x66 0x67 0x66 0x66 0x66 0x67 0x67 0x67 0x67 0x68 0x67 0x67 0x68 0x68 0x68 0x68 0x68 0x68 0x68 0x68 0x68 0x68 0x67 0x67 0x67 0x67 0x67 0x68 0x67 0x68 0x67 0x67 0x66 0x67 0x66 0x66 0x66 0x67 0x66 0x66 0x67 0x67 0x66 0x66 0x67 0x66 0x66 0x67 0x67 0x68 0x67 0x67 0x67 0x67 0x67 0x67 0x67 0x67 0x67 0x67 0x67 0x68 0x67 0x64 0x64 0x64 0x64 0x64 0x64 0x66 0x64 0x66 0x66 0x66 0x66 0x66 0x66 0x66 0x66 0x67 0x67 0x67 0x66 0x67 0x66 0x67 0x66 0x66 0x64 0x66 0x64 0x66 0x66 0x67 0x67 0x67 0x67 0x67 0x66 0x67 0x66 0x67 0x67 0x67 0x67 0x67 0x67 0x67 0x67 0x67 0x68 0x67 0x68 0x67 0x68 0x67 0x68 0x67 0x68 0x67 0x68 0x67 0x68 0x67 0x68 0x68 0x67 0x66 0x64 0x66 0x64 0x66 0x66 0x66 0x66 0x66 0x66 0x67 0x66 0x66 0x66 0x67 0x68 0x67 0x68 0x67 0x67 0x67 0x67 0x66 0x67 0x66 0x67 0x66 0x67 0x66 0x67 0x67 0x68 0x6a 0x68 0x68 0x67 0x68 0x67 0x67 0x67 0x68 0x67 0x67 0x67 0x68 0x67 0x67 0x67 0x68 0x68 0x67 0x67 0x68 0x68 0x67 0x67 0x67 0x68 0x68 0x68 0x68 0x6a 0x6a 0x68 0x67 0x66 0x66 0x66 0x67 0x66 0x66 0x66 0x67 0x67 0x67 0x67 0x67 0x67 0x67 0x67 0x67 0x68 0x67 0x67 0x67 0x67 0x66 0x67 0x66 0x67 0x67 0x67 0x67 0x68 0x68 0x68 0x6a 0x68 0x68 0x68 0x68 0x68 0x68 0x67 0x68 0x68 0x68 0x67 0x68 0x68 0x67 0x68 0x68 0x68 0x6a 0x68 0x68 0x68 0x68 0x68 0x68 0x68 0x68 0x68 0x6a 0x68 0x6a 0x67 0x67 0x67 0x67 0x66 0x67 0x67 0x67 0x67 0x67 0x68 0x67 0x67 0x68 0x68 0x67 0x68 0x68 0x67 0x68 0x68 0x68 0x67 0x68 0x67 0x67 0x67 0x67 0x67 0x67 0x67 0x68 0x67 0x66 0x67 0x67 0x66 0x66 0x67 0x67 0x66 0x66 0x67 0x67 0x66 0x66 0x67 0x66 0x67 0x67 0x67 0x67 0x67 0x67 0x67 0x67 0x67 0x66 0x67 0x67 0x67 0x67 0x68 0x68 0x67 0x64 0x64 0x64 0x64 0x64 0x66 0x66 0x66 0x64 0x66 0x66 0x66 0x64 0x66 0x66 0x66 0x66 0x67 0x66 0x66 0x66 0x67 0x66 0x66 0x64 0x66 0x66 0x64 0x64 0x66 0x67 0x68 0x67 0x67 0x67 0x67 0x67 0x67 0x67 0x67 0x67 0x67 0x67 0x67 0x67 0x67 0x67 0x67 0x68 0x67 0x67 0x67 0x68 0x68 0x67 0x67 0x67 0x67 0x67 0x67 0x68 0x68 0x68 0x67 0x66 0x66 0x66 0x64 0x66 0x66 0x66 0x66 0x66 0x67 0x67 0x67 0x66 0x67 0x67 0x67 0x67 0x67 0x67 0x67 0x67 0x67 0x66 0x66 0x66 0x66 0x64 0x66 0x66 0x67 0x68 0x6a 0x68 0x68 0x68 0x68 0x67 0x67 0x67 0x67 0x67 0x67 0x67 0x67 0x67 0x67 0x67 0x68 0x67 0x67 0x67 0x68 0x67 0x67 0x67 0x68 0x67 0x67 0x68 0x68 0x68 0x68 0x6a 0x68 0x66 0x67 0x67 0x66 0x66 0x66 0x66 0x67 0x66 0x67 0x67 0x67 0x66 0x67 0x67 0x67 0x67 0x67 0x67 0x67 0x67 0x66 0x66 0x67 0x66 0x66 0x66 0x67 0x67 0x67 0x6a 0x6a 0x68 0x68 0x68 0x67 0x68 0x67 0x67 0x68 0x67 0x68 0x67 0x67 0x67 0x67 0x67 0x67 0x67 0x68 0x68 0x68 0x67 0x68 0x68 0x67 0x67 0x68 0x68 0x68 0x68 0x6a 0x6a 0x68 0x67 0x66 0x66 0x66 0x67 0x66 0x67 0x67 0x67 0x67 0x67 0x67 0x67 0x67 0x67 0x67 0x67 0x68 0x67 0x67 0x67 0x68 0x67 0x67 0x66 0x67 0x67 0x67 0x67 0x67 0x68 0x67 0x66 0x66 0x67 0x66 0x66 0x66 0x66 0x66 0x66 0x66 0x67 0x66 0x66 0x66 0x66 0x66 0x66 0x67 0x66 0x66 0x66 0x67 0x66 0x66 0x66 0x67 0x67 0x66 0x67 0x68 0x68 0x66 0x64 0x63 0x64 0x64 0x64 0x64 0x66 0x64 0x64 0x64 0x66 0x66 0x64 0x64 0x66 0x66 0x66 0x67 0x66 0x66 0x66 0x66 0x66 0x64 0x64 0x66 0x64 0x64 0x64 0x66 0x68 0x68 0x66 0x67 0x67 0x67 0x66 0x67 0x67 0x67 0x66 0x67 0x67 0x67 0x66 0x66 0x67 0x67 0x68 0x67 0x67 0x68 0x68 0x67 0x67 0x67 0x68 0x67 0x67 0x68 0x68 0x67 0x68 0x67 0x64 0x66 0x66 0x64 0x64 0x64 0x66 0x66 0x64 0x66 0x67 0x66 0x64 0x66 0x67 0x67 0x67 0x66 0x67 0x67 0x67 0x66 0x66 0x66 0x67 0x64 0x64 0x66 0x67 0x66 0x68 0x68 0x67 0x68 0x67 0x68 0x66 0x67 0x67 0x67 0x66 0x67 0x67 0x67 0x66 0x66 0x66 0x67 0x67 0x67 0x67 0x68 0x67 0x67 0x67 0x68 0x67 0x67 0x67 0x68 0x68 0x68 0x6a 0x67 0x64 0x66 0x66 0x66 0x64 0x66 0x66 0x66 0x64 0x66 0x66 0x66 0x64 0x66 0x66 0x67 0x67 0x66 0x66 0x67 0x67 0x66 0x66 0x67 0x66 0x66 0x66 0x67 0x67 0x67 0x6a 0x68 0x68 0x68 0x68 0x67 0x67 0x67 0x67 0x67 0x67 0x67 0x67 0x67 0x67 0x67 0x67 0x68 0x67 0x68 0x68 0x68 0x68 0x68 0x68 0x68 0x67 0x68 0x68 0x68 0x68 0x6a 0x6a 0x67 0x66 0x66 0x66 0x66 0x66 0x66 0x66 0x66 0x66 0x67 0x67 0x66 0x66 0x67 0x67 0x67 0x67 0x67 0x67 0x67 0x67 0x67 0x67 0x67 0x66 0x67 0x66 0x67 0x67 0x67 0x6a 0x67 0x67 0x66 0x66 0x66 0x66 0x66 0x64 0x66 0x66 0x66 0x64 0x66 0x66 0x66 0x64 0x66 0x66 0x66 0x66 0x66 0x66 0x66 0x66 0x66 0x66 0x66 0x67 0x66 0x66 0x67 0x68 0x64 0x64 0x64 0x63 0x64 0x64 0x64 0x63 0x64 0x64 0x64 0x64 0x64 0x64 0x64 0x64 0x66 0x64 0x64 0x66 0x66 0x64 0x64 0x64 0x64 0x64 0x64 0x64 0x64 0x64 0x64 0x68 0x67 0x67 0x67 0x66 0x66 0x67 0x66 0x66 0x66 0x66 0x66 0x66 0x66 0x66 0x66 0x66 0x67 0x67 0x67 0x66 0x67 0x67 0x67 0x66 0x67 0x67 0x67 0x66 0x67 0x68 0x68 0x6a 0x64 0x64 0x64 0x63 0x63 0x64 0x64 0x64 0x64 0x64 0x66 0x64 0x64 0x64 0x66 0x64 0x66 0x66 0x67 0x66 0x66 0x66 0x66 0x64 0x66 0x66 0x66 0x64 0x66 0x66 0x66 0x68 0x68 0x68 0x68 0x67 0x67 0x67 0x67 0x66 0x66 0x66 0x67 0x66 0x66 0x66 0x67 0x66 0x67 0x67 0x67 0x67 0x67 0x67 0x67 0x67 0x67 0x66 0x68 0x68 0x68 0x68 0x6a 0x6a 0x66 0x66 0x66 0x64 0x64 0x64 0x64 0x64 0x64 0x66 0x66 0x66 0x66 0x66 0x66 0x66 0x66 0x66 0x67 0x66 0x66 0x66 0x66 0x66 0x66 0x64 0x66 0x66 0x66 0x66 0x67 0x6a 0x68 0x68 0x68 0x67 0x67 0x67 0x67 0x67 0x67 0x67 0x67 0x67 0x67 0x67 0x67 0x67 0x68 0x67 0x68 0x67 0x68 0x67 0x68 0x67 0x68 0x67 0x68 0x67 0x68 0x68 0x6a 0x6a 0x66 0x66 0x66 0x64 0x64 0x66 0x66 0x64 0x64 0x66 0x66 0x66 0x66 0x66 0x67 0x66 0x67 0x66 0x67 0x66 0x67 0x66 0x67 0x66 0x66 0x66 0x66 0x66 0x67 0x66 0x67 0x68 0x67 0x66 0x66 0x66 0x66 0x66 0x66 0x66 0x66 0x66 0x66 0x66 0x66 0x64 0x66 0x66 0x66 0x66 0x66 0x66 0x67 0x66 0x66 0x66 0x66 0x66 0x66 0x66 0x67 0x67 0x67 0x6a 0x64 0x63 0x63 0x64 0x64 0x63 0x64 0x64 0x64 0x64 0x64 0x66 0x66 0x64 0x64 0x66 0x66 0x66 0x64 0x64 0x66 0x64 0x64 0x64 0x64 0x64 0x64 0x63 0x64 0x64 0x64 0x68 0x13a 0x13a 0x13a>;
            PS_Config_Lmt_FW_Rawdata_N = <0x3ae 0x3c6 0x3c2 0x3bb 0x3b8 0x3bd 0x3b5 0x3bf 0x3be 0x3bc 0x3bc 0x3be 0x3b7 0x3c3 0x3b6 0x3b3 0x3c3 0x3bc 0x3c2 0x3b3 0x3c7 0x3c0 0x3bd 0x3c1 0x3b7 0x3c1 0x3b4 0x3ba 0x3c0 0x3bb 0x3b8 0x3b5 0x3c9 0x3cb 0x3c0 0x3c1 0x3c5 0x3c2 0x3c1 0x3cc 0x3c3 0x3b1 0x3bd 0x3c1 0x3c0 0x3ca 0x3c7 0x3cd 0x3ab 0x3ce 0x3d5 0x3be 0x3ba 0x3bf 0x3ba 0x3bf 0x3b7 0x3c1 0x3d8 0x3c4 0x3ad 0x3bd 0x3a2 0x3b9 0x3bd 0x3b5 0x3b7 0x3c9 0x3c4 0x3c2 0x3bd 0x3a7 0x3c9 0x3ba 0x3b2 0x3b8 0x3b9 0x3bb 0x3b0 0x3af 0x3c5 0x3c7 0x3cf 0x3af 0x3cc 0x3c6 0x3c2 0x3b6 0x3a8 0x3b8 0x3bb 0x3c1 0x3a5 0x3d0 0x3cd 0x3b3 0x3bd 0x3c0 0x3c1 0x3b1 0x3c0 0x3bb 0x3b5 0x3b8 0x3ae 0x3c4 0x3c5 0x3a9 0x3b2 0x3b8 0x3ac 0x3b7 0x3c4 0x3c7 0x3cc 0x3ab 0x3c3 0x3b9 0x3a9 0x3be 0x3c3 0x3c3 0x3c3 0x3c7 0x3af 0x3c8 0x3af 0x3c1 0x3c2 0x3ae 0x3c5 0x3b4 0x3b5 0x3cd 0x3c4 0x3b7 0x3b8 0x3b8 0x3c4 0x3c7 0x3a8 0x3a3 0x3c2 0x3c4 0x3bb 0x3b8 0x3ba 0x3bc 0x3bd 0x3b4 0x3bb 0x3ac 0x3b8 0x3b7 0x3c9 0x3b2 0x3ab 0x3c2 0x3ba 0x3b4 0x3c4 0x3c1 0x3b7 0x3b8 0x3c0 0x3c9 0x3c6 0x3c6 0x3b1 0x3b5 0x3b9 0x3bb 0x3cc 0x3cb 0x3c0 0x3b7 0x3bd 0x3b8 0x3c3 0x3b3 0x3be 0x3c9 0x3bb 0x3c6 0x3be 0x3b1 0x3c7 0x3b2 0x3c2 0x3b4 0x3b0 0x3b9 0x3bb 0x3ae 0x3c1 0x3b8 0x3b2 0x3c2 0x3bd 0x3cf 0x3c9 0x3c7 0x3c9 0x3b2 0x3bd 0x3cc 0x3cb 0x3c7 0x3b3 0x3c3 0x3be 0x3b5 0x3b5 0x3c4 0x3cc 0x3b4 0x3be 0x3b5 0x3be 0x3b7 0x3bd 0x3c2 0x3bd 0x3d0 0x3bd 0x3cd 0x3b1 0x3b8 0x3b8 0x3bc 0x3b8 0x3bd 0x3b8 0x3b2 0x3b1 0x3d7 0x3bb 0x3c0 0x3c5 0x3c0 0x3b2 0x3c5 0x3b7 0x3b8 0x3b7 0x3c4 0x3b1 0x3be 0x3b4 0x3b9 0x3be 0x3bd 0x3b4 0x3ba 0x3b5 0x3bb 0x3b1 0x3c1 0x3ba 0x3b4 0x3c1 0x3d0 0x3c9 0x3b8 0x3cb 0x3c0 0x3b8 0x3c3 0x3cc 0x3bd 0x3bb 0x3b2 0x3cf 0x3be 0x3b1 0x3b8 0x3ca 0x3b7 0x3bb 0x3c3 0x3c0 0x3cd 0x3ba 0x3c4 0x3bb 0x3ad 0x3b6 0x3c0 0x3c4 0x3ab 0x3c6 0x3b5 0x3b9 0x3bf 0x3c4 0x3bf 0x3d0 0x3c2 0x3bd 0x3b7 0x3be 0x3b8 0x3c4 0x3b5 0x3d0 0x3c3 0x3b3 0x3ae 0x3ca 0x3c9 0x3c8 0x3bb 0x3c7 0x3bd 0x3bc 0x3c0 0x3b2 0x3be 0x3b8 0x3b0 0x3be 0x3b3 0x3c6 0x3c0 0x3af 0x3b2 0x3c0 0x3b7 0x3b5 0x3ba 0x3bc 0x3c9 0x3b1 0x3b7 0x3c9 0x3c6 0x3bb 0x3c9 0x3b8 0x3b7 0x3ba 0x3b4 0x3bf 0x3c6 0x3bc 0x3b8 0x3c4 0x3c6 0x3c4 0x3ac 0x3c2 0x3c0 0x3be 0x3c0 0x3b7 0x3b4 0x3b8 0x3b7 0x3c5 0x3cd 0x3c0 0x3cd 0x3bd 0x3bd 0x3ba 0x3b1 0x3d0 0x3c4 0x3b6 0x3c1 0x3b2 0x3c5 0x3b1 0x3bb 0x3bc 0x3be 0x3b5 0x3ad 0x3bf 0x3b8 0x3bb 0x3cd 0x3b7 0x3ba 0x3bd 0x3c1 0x3ba 0x3c6 0x3ca 0x3ba 0x3c6 0x3bc 0x3c1 0x3b9 0x3ad 0x3c7 0x3c0 0x3c4 0x3ad 0x3b2 0x3b3 0x3b9 0x3c2 0x3c4 0x3b8 0x3b5 0x3be 0x3ca 0x3c1 0x3ca 0x3b4 0x3ae 0x3b4 0x3bf 0x3ba 0x3b7 0x3b7 0x3c0 0x3ba 0x3ba 0x3c6 0x3be 0x3c7 0x3c1 0x3c5 0x3bb 0x3d0 0x3af 0x3c3 0x3c1 0x3a9 0x3b1 0x3b0 0x3ba 0x3ba 0x3cc 0x3af 0x3c9 0x3c1 0x3b7 0x3c0 0x3a6 0x3bd 0x3ac 0x3ba 0x3bb 0x3ba 0x3c0 0x3c1 0x3be 0x3ca 0x3cd 0x3bc 0x3b7 0x3be 0x3bd 0x3c7 0x3c0 0x3ac 0x3ba 0x3c5 0x3be 0x3b1 0x3ba 0x3be 0x3c4 0x3be 0x3bf 0x3be 0x3c5 0x3c0 0x3c1 0x3b2 0x3b8 0x3bd 0x3c4 0x3c6 0x3c3 0x3b8 0x3b4 0x3c7 0x3ba 0x3b5 0x3c3 0x3b2 0x3b8 0x3b7 0x3c6 0x3af 0x3c3 0x3c9 0x3c1 0x3c1 0x3c1 0x3ab 0x3b9 0x3b8 0x3be 0x3b7 0x3c2 0x3b6 0x3ba 0x3b4 0x3c8 0x3c4 0x3c3 0x3c7 0x3b8 0x3b7 0x3c9 0x3c3 0x3c1 0x3c6 0x3b8 0x3b3 0x3b5 0x3c1 0x3ca 0x3be 0x3c1 0x3cd 0x3c4 0x3c0 0x3c7 0x3ca 0x3c4 0x3b4 0x3b9 0x3ba 0x3d3 0x3bc 0x3ab 0x3b3 0x3c9 0x3c1 0x3cd 0x3c0 0x3bd 0x3ba 0x3c4 0x3c4 0x3c3 0x3c1 0x3c7 0x3b0 0x3c6 0x3c7 0x3c7 0x3c1 0x3cc 0x3be 0x3ca 0x3aa 0x3ba 0x3c4 0x3b6 0x3c3 0x3c6 0x3bc 0x3b7 0x3bb 0x3d0 0x3b4 0x3bd 0x3c6 0x3be 0x3bb 0x3b7 0x3b8 0x3c5 0x3bd 0x3c0 0x3c0 0x3a7 0x3b2 0x3c3 0x3c6 0x3c1 0x3a9 0x3c4 0x3bd 0x3c3 0x3cd 0x3b4 0x3c4 0x3c3 0x3c0 0x3c0 0x3c4 0x3ba 0x3bb 0x3ad 0x3bc 0x3b6 0x3be 0x3c6 0x3b8 0x3b4 0x3b8 0x3b3 0x3ce 0x3cf 0x3be 0x3c6 0x3b2 0x3bd 0x3be 0x3ba 0x3b3 0x3c0 0x3d8 0x3ad 0x3b2 0x3c3 0x3be 0x3c3 0x3be 0x3b7 0x3bb 0x3ac 0x3be 0x3b8 0x3c0 0x3b3 0x3bd 0x3c1 0x3c0 0x3b8 0x3bf 0x3ca 0x3c3 0x3b9 0x3b7 0x3ba 0x3b7 0x3bb 0x3be 0x3c6 0x3b6 0x3c3 0x3c6 0x3c4 0x3bf 0x3c6 0x3cb 0x3be 0x3bf 0x3b8 0x3c8 0x3bc 0x3ba 0x3c1 0x3cd 0x3b6 0x3cf 0x3b5 0x3c3 0x3ca 0x3b7 0x3c4 0x3c2 0x3c4 0x3c4 0x3bc 0x3c5 0x3b0 0x3c3 0x3c3 0x3c6 0x3c1 0x3c6 0x3bd 0x3b7 0x3bb 0x3cf 0x3bc 0x3c7 0x3c3 0x3be 0x3bd 0x3b9 0x3be 0x3c0 0x3ae 0x3c7 0x3bf 0x3c3 0x3b0 0x3b8 0x3c6 0x3bf 0x3be 0x3c5 0x3aa 0x3ba 0x3d5 0x3b7 0x3b8 0x3bc 0x3cd 0x3c1 0x3b8 0x3bc 0x3bb 0x3b5 0x3bf 0x3ab 0x3c0 0x3b7 0x3b2 0x3ca 0x3bb 0x3ba 0x3ba 0x3b8 0x3be 0x3c0 0x3c2 0x3d1 0x3bc 0x3c1 0x3c9 0x3bf 0x3b8 0x3cc 0x3ca 0x3b9 0x3bc 0x3b8 0x3bd 0x3b5 0x3c9 0x3c9 0x3b4 0x3c1 0x3b6 0x3c6 0x3b9 0x3d3 0x3b5 0x3c9 0x3ba 0x3cf 0x3c5 0x3b8 0x3c3 0x3bf 0x3b7 0x3be 0x3ba 0x3c4 0x3ba 0x3b5 0x3d0 0x3ba 0x3bb 0x3b3 0x3bd 0x3c1 0x3c6 0x3c3 0x3c6 0x3b5 0x3c2 0x3ba 0x3bd 0x3b7 0x3bd 0x3ca 0x3bf 0x3bb 0x3b4 0x3c4 0x3be 0x3bd 0x3ae 0x3b9 0x3ba 0x3b9 0x3b2 0x3b9 0x3cc 0x3bc 0x3ca 0x3b3 0x3b4 0x3c8 0x3c6 0x3c1 0x3b5 0x3c0 0x3be 0x3be 0x3b1 0x3cc 0x3b5 0x3af 0x3c2 0x3b3 0x3b5 0x3bd 0x3ba 0x3c4 0x3c8 0x3cc 0x3bd 0x3b3 0x3ac 0x3c0 0x3b7 0x3bf 0x3c1 0x3b9 0x3b7 0x3b9 0x3c9 0x3a5 0x3be 0x3b8 0x3c3 0x3b5 0x3c7 0x3af 0x3af 0x3bd 0x3b5 0x3c8 0x3bf 0x3b0 0x3bc 0x3cf 0x3be 0x3be 0x3d2 0x3cb 0x3ba 0x3c0 0x3b4 0x3bd 0x3ac 0x3c0 0x3c6 0x3c1 0x3ad 0x3b7 0x3bf 0x3af 0x3b2 0x3c1 0x3bf 0x3ac 0x3bc 0x3ca 0x3c3 0x3b2 0x3c4 0x3d0 0x3b8 0x3c9 0x3bd 0x3c7 0x3bd 0x3be 0x3b5 0x3bd 0x3b4 0x3b7 0x3ac 0x3c9 0x3b0 0x3c4 0x3b8 0x3c3 0x3b3 0x3b2 0x3d3 0x3c0 0x3bb 0x3b4 0x3c4 0x3bf 0x3ba 0x3cf 0x3b2 0x3ba 0x3b8 0x3bd 0x3b7 0x3c7 0x3ba 0x3cd 0x3bb 0x3c2 0x3bd 0x3c3 0x3c6 0x3b4 0x3ba 0x3c0 0x3bd 0x3b5 0x3c3 0x3c9 0x3be 0x3b9 0x3bd 0x3c9 0x3b7 0x3bd 0x3b1 0x3c3 0x3be 0x3b4 0x3c3 0x3b5 0x3b6 0x3b9 0x3cd 0x3c0 0x3b7 0x3b5 0x3bb 0x3c4 0x3cc 0x3c3 0x3c9 0x3bd 0x3bb 0x3bb 0x3c3 0x3b4 0x3b3 0x3b9 0x3c1 0x3ce 0x3bb 0x3bc 0x3cb 0x3b4 0x3c6 0x3ba 0x3c7 0x3b3 0x3c4 0x3ca 0x3b8 0x3b7 0x3a6 0x3c3 0x3b1 0x3c1 0x3c9 0x3c3 0x3be 0x3cb 0x3c5 0x3bd 0x3a9 0x3ba 0x3bf 0x3b5 0x3c0 0x3ae 0x3b1 0x3b7 0x3c3 0x3cd 0x3c5 0x3b6 0x3b6 0x3bd 0x3c7 0x3ab 0x3a7 0x3be 0x3be 0x3ca 0x3c8 0x3c0 0x3b2 0x3c4 0x3cc 0x3c3 0x3b2 0x3cc 0x3c7 0x3c7 0x3bf 0x3b8 0x3b8 0x3af 0x3ae 0x3b7 0x3c1 0x3d0 0x3c4 0x3b1 0x3bd 0x3d1 0x3c6 0x3c2 0x3cd 0x3bf 0x3b9 0x3cc 0x3c9 0x3b9 0x3b7 0x3be 0x3c6 0x3b8 0x3c8 0x3c3 0x3bd 0x3bb 0x3c1 0x3c7 0x3c9 0x3c3 0x3af 0x3cf 0x3b6 0x3d5 0x3d1 0x3ba 0x3ce 0x3ba 0x3c6 0x3b2 0x3c1 0x3bb 0x3c4 0x3a9 0x3b8 0x3ba 0x3bb 0x3b6 0x3b1 0x3ae 0x3bf 0x3b8 0x3bc 0x3c0 0x3c7 0x3c8 0x3c9 0x3bd 0x3c5 0x3c4 0x3be 0x3be 0x3b7 0x3c9 0x3c0 0x3b5 0x3c2 0x3be 0x3ae 0x3c4 0x3bf 0x3b3 0x3b7 0x3b9 0x3be 0x3bc 0x3cc 0x3ca 0x3ba 0x3ca 0x3d1 0x3c4 0x3be 0x3b6 0x3bc 0x3b2 0x3bb 0x3b2 0x3bd 0x3ca 0x3b4 0x3c8 0x3bd 0x3ba 0x3b6 0x3c1 0x3c0 0x3b5 0x3c4 0x3b4 0x3c1 0x3b8 0x3b8 0x3c5 0x3ba 0x3ba 0x3c7 0x3b9 0x3bd 0x3a8 0x3c4 0x3b6 0x3b8 0x3c6 0x3c1 0x3c8 0x3b8 0x3be 0x3b5 0x3b1 0x3c8 0x3c6 0x3bd 0x3c0 0x3be 0x3c0 0x3bb 0x3be 0x3b4 0x3b7 0x3c0 0x3b2 0x3b9 0x3ca 0x3d2 0x3c2 0x3b4 0x3c1 0x3b4 0x3bd 0x3ba 0x3c0 0x3b5 0x3c4 0x3b7 0x3ba 0x3a9 0x3c3 0x3b1 0x3b4 0x3b1 0x3c7 0x3bf 0x3bd 0x3c6 0x3bb 0x3b7 0x3b5 0x3bb 0x3b5 0x3c3 0x3c9 0x3c6 0x3ca 0x3bc 0x3b4 0x3c6 0x3af 0x3c3 0x3b1 0x3c9 0x3c5 0x3ac 0x3be 0x3c3 0x3c3 0x3b5 0x3b5 0x3c9 0x3ae 0x3b8 0x3c0 0x3b3 0x3c0 0x3bb 0x3ad 0x3b1 0x3b7 0x3ba 0x3c1 0x3b5 0x3c3 0x3c3 0x3c5 0x3c7 0x3bd 0x3bc 0x3cf 0x3b0 0x3c9 0x3bf 0x3b8 0x3c6 0x3c3 0x3bb 0x3bd 0x3b8 0x3b1 0x3c4 0x3be 0x3b4 0x3cf 0x3c3 0x3c9 0x3c5 0x3c3 0x3b7 0x3b8 0x3bb 0x3ba 0x3c1 0x3b5 0x3ca 0x3be 0x3bb 0x3c5 0x3b3 0x3bd 0x3b6 0x3bd 0x3be 0x3b5 0x3be 0x3b0 0x3b2 0x3b7 0x3c3 0x3ab 0x3b5 0x3c8 0x3b2 0x3cf 0x3c0 0x3ab 0x3c3 0x3c1 0x3b5 0x3c1 0x3c2 0x3c3 0x3b6 0x3be 0x3bb 0x3cb 0x3c0 0x3b4 0x3bf 0x3b5 0x3c3 0x3c3 0x3c9 0x3b1 0x3b9 0x3b0 0x3c4 0x3bd 0x3bb 0x3ab 0x3c3 0x3bb 0x3be 0x3bb 0x3c6 0x3b4 0x3bb 0x3ce 0x3bc 0x3c0 0x3c4 0x3c1 0x3b8 0x3c1 0x3c0 0x3bd 0x3bb 0x3ba 0x3c0 0x3c2 0x3c3 0x3c2 0x3be 0x3be 0x3b8 0x3c6 0x3c1 0x3c9 0x3bf 0x3c9 0x3c6 0x3cd 0x3c3 0x3cd 0x3c0 0x3c6 0x3c8 0x3af 0x3c1 0x3b5 0x3bb 0x3ba 0x3b1 0x3c3 0x3c2 0x3bb 0x3b4 0x3c2 0x3b5 0x3b8 0x3ca 0x3c1 0x3c5 0x3b5 0x3bb 0x3bd 0x3cb 0x3c0 0x3c0 0x3c1 0x3bd 0x3be 0x3c3 0x3cc 0x3bc 0x3b2 0x3b4 0x3b3 0x3b4 0x3b6 0x3c1 0x3c1 0x3bb 0x3bd 0x3c4 0x3b5 0x3c3 0x3be 0x3b8 0x3c6 0x3a8 0x3c4 0x3b5 0x3c0 0x3b2 0x3c4 0x3c2 0x3d0 0x3be 0x3c3 0x3ae 0x3c1 0x3b5 0x3c4 0x3b2 0x3cd 0x3c8 0x3bd 0x3b1 0x3c7 0x3c1 0x3af 0x3ba 0x3c5 0x3c4 0x3d0 0x3b3 0x3c4 0x3c5 0x3ca 0x3b4 0x3c3 0x3bf 0x3b6 0x3bb 0x3bd 0x3be 0x3b7 0x3af 0x3bd 0x3be 0x3bb 0x3d0 0x3ba 0x3c6 0x3b8 0x3b6 0x3cd 0x3c6 0x3c0 0x3c0 0x3b5 0x3c0 0x3c6 0x3c0 0x3b3 0x3b7 0x3b1 0x3c0 0x3b1 0x3ca 0x3cd 0x3b1 0x3cb 0x3b7 0x3c6 0x3be 0x3c7 0x3ba 0x3c0 0x3c9 0x3b2 0x3b4 0x3ba 0x3c4 0x3c3 0x3b8 0x3c0 0x3ae 0x3bd 0x3b1 0x3bb 0x3b9 0x3b5 0x3bc 0x3bd 0x3ac 0x3a6 0x3c7 0x3b4 0x3bd 0x3bc 0x3d1 0x3b3 0x3be 0x3b5 0x3c3 0x3ca 0x3c6 0x3a8 0x3cc 0x3c0 0x3bd 0x3ae 0x3be 0x3c6 0x3b5 0x3c3 0x3b2 0x3c4 0x3b5 0x3c0 0x3b2 0x3bd 0x3c6 0x3c0 0x3bb 0x3c2 0x3d2 0x3d0 0x3af 0x3c5 0x3b2 0x3d6 0x3c0 0x3b6 0x3bf 0x3a8 0x3ae 0x3ba 0x3ae 0x3c5 0x3b4 0x3c0 0x3ae 0x3bb 0x3b9 0x3b0 0x3be 0x3a7 0x3c2 0x3d8 0x3be 0x3b1 0x3c7 0x3ba 0x3c5 0x3b2 0x3c6 0x3cd 0x3c5 0x3b1 0x3b9 0x3bb 0x3b2 0x3b0 0x3bb 0x3b5 0x3ca 0x3ae 0x3b1 0x3b4 0x3b4 0x3d0 0x3b6 0x3b8 0x3b2 0x3b3 0x3c6 0x3b9 0x3be 0x3c5 0x3b9 0x3bd 0x3c4 0x3bd 0x3d0 0x3ba 0x3c5 0x3b9 0x3ca 0x3af 0x3c5 0x3b1 0x3ca 0x3cb 0x3b7 0x3b5 0x3ba 0x3ba 0x3c9 0x3ce 0x3c8 0x3c3 0x3c0 0x3bb 0x3b9 0x3b5 0x3c6 0x3be 0x3b7 0x3bd 0x3b7 0x3c8 0x3c3 0x3bd 0x3c0 0x3ca 0x3c2 0x3bd 0x3c7 0x3c9 0x3bd 0x3c3 0x3c4 0x3c0 0x3be 0x3c4 0x3bd 0x3bf 0x3ba 0x3c1 0x3b4 0x3bf 0x3cf 0x3c2 0x3c4 0x3b4 0x3c4 0x3bd 0x3b2 0x3c3 0x3c2 0x3c7 0x3bb 0x3b8 0x3bd 0x3be 0x3c1 0x3c3 0x3cc 0x3c3 0x3b8 0x3ae 0x3c6 0x3bc 0x3bd 0x3b7 0x3bd 0x3b5 0x3c7 0x3c0 0x3ae 0x3c9 0x3b1 0x3c6 0x3c3 0x3b3 0x3bd 0x3bd 0x3c9 0x3c1 0x3c1 0xf0 0xf0 0xf0>;
            PS_Config_Lmt_FW_Rawdata_P = <0x896 0x8ce 0x8c5 0x8b6 0x8af 0x8ba 0x8a6 0x8be 0x8bd 0x8b7 0x8b7 0x8bb 0x8ac 0x8c7 0x8a9 0x8a2 0x8c7 0x8b7 0x8c5 0x8a2 0x8d2 0x8c1 0x8b9 0x8c4 0x8ab 0x8c2 0x8a5 0x8b3 0x8c1 0x8b6 0x8af 0x8a8 0x8d6 0x8da 0x8c0 0x8c2 0x8cc 0x8c5 0x8c2 0x8dc 0x8c8 0x89e 0x8ba 0x8c2 0x8c0 0x8d7 0x8d2 0x8de 0x88f 0x8e1 0x8f1 0x8bd 0x8b2 0x8be 0x8b3 0x8be 0x8ab 0x8c2 0x8f9 0x8cb 0x894 0x8ba 0x87b 0x8b0 0x8ba 0x8a6 0x8ab 0x8d5 0x8cb 0x8c5 0x8ba 0x886 0x8d6 0x8b2 0x8a1 0x8af 0x8b0 0x8b4 0x89b 0x89a 0x8cc 0x8d2 0x8e4 0x89a 0x8dc 0x8ce 0x8c5 0x8a9 0x888 0x8af 0x8b4 0x8c2 0x881 0x8e5 0x8de 0x8a2 0x8ba 0x8c1 0x8c2 0x89d 0x8c1 0x8b4 0x8a6 0x8ad 0x896 0x8c9 0x8cc 0x88c 0x89f 0x8af 0x891 0x8ac 0x8cb 0x8d0 0x8dc 0x890 0x8c8 0x8b0 0x88a 0x8bd 0x8c7 0x8c7 0x8c8 0x8d2 0x898 0x8d3 0x89a 0x8c2 0x8c5 0x896 0x8cc 0x8a4 0x8a6 0x8e0 0x8c9 0x8ab 0x8ad 0x8ad 0x8c9 0x8d0 0x888 0x87e 0x8c5 0x8cb 0x8b6 0x8ad 0x8b3 0x8b7 0x8b9 0x8a4 0x8b6 0x893 0x8af 0x8ac 0x8d6 0x8a1 0x88f 0x8c5 0x8b2 0x8a4 0x8cb 0x8c2 0x8ac 0x8ad 0x8c1 0x8d6 0x8cf 0x8ce 0x89e 0x8a6 0x8b0 0x8b6 0x8dd 0x8da 0x8c0 0x8ac 0x8ba 0x8ad 0x8c7 0x8a2 0x8bd 0x8d5 0x8b4 0x8cf 0x8bb 0x89d 0x8d2 0x8a1 0x8c5 0x8a5 0x89b 0x8b0 0x8b4 0x896 0x8c2 0x8af 0x8a1 0x8c5 0x8ba 0x8e3 0x8d5 0x8d2 0x8d6 0x89f 0x8ba 0x8dc 0x8da 0x8d0 0x8a2 0x8c8 0x8bb 0x8a6 0x8a8 0x8cb 0x8dc 0x8a4 0x8bd 0x8a6 0x8bb 0x8ac 0x8b9 0x8c5 0x8ba 0x8e7 0x8ba 0x8de 0x89d 0x8af 0x8af 0x8b7 0x8af 0x8ba 0x8af 0x8a1 0x89e 0x8f6 0x8b4 0x8c1 0x8cc 0x8c1 0x8a1 0x8cc 0x8ab 0x8ad 0x8ac 0x8cb 0x89d 0x8bd 0x8a5 0x8b0 0x8bd 0x8ba 0x8a4 0x8b3 0x8a6 0x8b4 0x89d 0x8c2 0x8b2 0x8a4 0x8c2 0x8e7 0x8d5 0x8af 0x8da 0x8c1 0x8ad 0x8c8 0x8dc 0x8b9 0x8b6 0x8a1 0x8e3 0x8bb 0x89e 0x8af 0x8d9 0x8ac 0x8b6 0x8c8 0x8c0 0x8de 0x8b2 0x8cb 0x8b6 0x894 0x8a9 0x8c1 0x8c9 0x890 0x8cf 0x8a8 0x8b0 0x8be 0x8cb 0x8be 0x8e7 0x8c5 0x8b9 0x8ac 0x8bd 0x8ad 0x8cb 0x8a6 0x8e5 0x8c8 0x8a2 0x897 0x8d7 0x8d5 0x8d3 0x8b4 0x8d2 0x8b9 0x8b7 0x8c1 0x8a1 0x8bd 0x8ad 0x89b 0x8bb 0x8a2 0x8cf 0x8c0 0x89a 0x8a1 0x8c1 0x8ab 0x8a6 0x8b2 0x8b7 0x8d5 0x89e 0x8ac 0x8d6 0x8cf 0x8b4 0x8d5 0x8af 0x8ab 0x8b3 0x8a5 0x8be 0x8ce 0x8b7 0x8af 0x8cb 0x8ce 0x8c9 0x891 0x8c5 0x8c1 0x8bb 0x8c0 0x8ab 0x8a4 0x8ad 0x8ac 0x8cc 0x8e0 0x8c0 0x8e0 0x8ba 0x8ba 0x8b2 0x89e 0x8e5 0x8c9 0x8a9 0x8c2 0x89f 0x8cc 0x89e 0x8b4 0x8b7 0x8bd 0x8a8 0x894 0x8be 0x8af 0x8b6 0x8e0 0x8ac 0x8b3 0x8b9 0x8c4 0x8b3 0x8ce 0x8d7 0x8b3 0x8ce 0x8b7 0x8c2 0x8b0 0x894 0x8d0 0x8c1 0x8cb 0x894 0x89f 0x8a2 0x8b0 0x8c5 0x8c9 0x8ad 0x8a8 0x8bb 0x8d9 0x8c2 0x8d7 0x8a4 0x896 0x8a4 0x8be 0x8b2 0x8ac 0x8ac 0x8c1 0x8b3 0x8b2 0x8ce 0x8bd 0x8d0 0x8c4 0x8cc 0x8b6 0x8e5 0x898 0x8c8 0x8c4 0x88a 0x89d 0x89b 0x8b2 0x8b3 0x8dc 0x898 0x8d6 0x8c4 0x8ac 0x8c1 0x885 0x8b9 0x893 0x8b2 0x8b6 0x8b3 0x8c1 0x8c2 0x8bb 0x8d7 0x8e0 0x8b7 0x8ab 0x8bb 0x8b9 0x8d2 0x8c1 0x891 0x8b2 0x8cc 0x8bb 0x89e 0x8b3 0x8bb 0x8c9 0x8bd 0x8be 0x8bb 0x8cc 0x8c0 0x8c2 0x8a1 0x8ad 0x8ba 0x8cb 0x8ce 0x8c7 0x8ad 0x8a5 0x8d0 0x8b2 0x8a8 0x8c8 0x89f 0x8af 0x8ab 0x8ce 0x89a 0x8c7 0x8d6 0x8c2 0x8c2 0x8c2 0x890 0x8b0 0x8af 0x8bb 0x8ac 0x8c5 0x8a9 0x8b2 0x8a4 0x8d3 0x8c9 0x8c7 0x8d0 0x8af 0x8ab 0x8d5 0x8c8 0x8c2 0x8ce 0x8ad 0x8a2 0x8a8 0x8c4 0x8d9 0x8bd 0x8c4 0x8de 0x8cb 0x8c1 0x8d0 0x8d7 0x8c9 0x8a4 0x8b0 0x8b3 0x8ee 0x8b7 0x890 0x8a2 0x8d6 0x8c2 0x8e0 0x8c0 0x8ba 0x8b3 0x8c9 0x8cb 0x8c7 0x8c2 0x8d0 0x89b 0x8cf 0x8d0 0x8d2 0x8c4 0x8dc 0x8bd 0x8d9 0x88d 0x8b2 0x8c9 0x8a9 0x8c7 0x8cf 0x8b7 0x8ab 0x8b4 0x8e7 0x8a5 0x8ba 0x8ce 0x8bd 0x8b4 0x8ac 0x8af 0x8cc 0x8ba 0x8c1 0x8c1 0x886 0x89f 0x8c8 0x8cf 0x8c2 0x88c 0x8c9 0x8b9 0x8c8 0x8de 0x8a5 0x8cb 0x8c7 0x8c0 0x8c0 0x8cb 0x8b3 0x8b6 0x894 0x8b7 0x8a9 0x8bb 0x8ce 0x8af 0x8a5 0x8ad 0x8a2 0x8e1 0x8e4 0x8bd 0x8cf 0x8a1 0x8b9 0x8bd 0x8b3 0x8a2 0x8c1 0x8f8 0x894 0x8a1 0x8c7 0x8bb 0x8c7 0x8bd 0x8ab 0x8b4 0x893 0x8bd 0x8af 0x8c0 0x8a2 0x8b9 0x8c2 0x8c0 0x8af 0x8be 0x8d7 0x8c8 0x8b0 0x8ab 0x8b3 0x8ab 0x8b6 0x8bd 0x8ce 0x8a9 0x8c7 0x8cf 0x8cb 0x8be 0x8cf 0x8da 0x8bb 0x8be 0x8ad 0x8d3 0x8b7 0x8b3 0x8c2 0x8de 0x8a9 0x8e4 0x8a6 0x8c8 0x8d9 0x8ab 0x8c9 0x8c5 0x8c9 0x8c9 0x8b7 0x8cc 0x89b 0x8c7 0x8c8 0x8cf 0x8c2 0x8ce 0x8ba 0x8ac 0x8b6 0x8e3 0x8b7 0x8d0 0x8c7 0x8bd 0x8ba 0x8b0 0x8bd 0x8c1 0x896 0x8d2 0x8be 0x8c7 0x89b 0x8ad 0x8ce 0x8be 0x8bd 0x8cc 0x88d 0x8b3 0x8f2 0x8ac 0x8af 0x8b7 0x8e0 0x8c4 0x8af 0x8b7 0x8b4 0x8a6 0x8be 0x88f 0x8c1 0x8ab 0x89f 0x8d7 0x8b6 0x8b2 0x8b3 0x8af 0x8bd 0x8c0 0x8c5 0x8e8 0x8b7 0x8c4 0x8d6 0x8be 0x8ad 0x8dd 0x8d7 0x8b0 0x8b7 0x8ad 0x8ba 0x8a6 0x8d5 0x8d5 0x8a5 0x8c4 0x8a9 0x8cf 0x8b0 0x8ec 0x8a6 0x8d6 0x8b2 0x8e3 0x8cc 0x8af 0x8c8 0x8be 0x8ab 0x8bd 0x8b2 0x8c9 0x8b3 0x8a8 0x8e7 0x8b3 0x8b4 0x8a2 0x8b9 0x8c2 0x8ce 0x8c7 0x8cf 0x8a8 0x8c5 0x8b3 0x8b9 0x8ab 0x8ba 0x8d7 0x8be 0x8b4 0x8a4 0x8cb 0x8bb 0x8ba 0x896 0x8b0 0x8b2 0x8b0 0x89f 0x8b0 0x8dc 0x8b7 0x8d7 0x8a2 0x8a5 0x8d3 0x8cf 0x8c4 0x8a6 0x8c0 0x8bb 0x8bb 0x89d 0x8dc 0x8a6 0x89a 0x8c5 0x8a2 0x8a8 0x8b9 0x8b3 0x8c9 0x8d3 0x8dc 0x8ba 0x8a2 0x891 0x8c0 0x8ac 0x8be 0x8c4 0x8b0 0x8ab 0x8b0 0x8d6 0x882 0x8bb 0x8ad 0x8c7 0x8a6 0x8d2 0x89a 0x898 0x8ba 0x8a6 0x8d3 0x8be 0x89b 0x8b7 0x8e4 0x8bb 0x8bd 0x8ea 0x8da 0x8b3 0x8c1 0x8a4 0x8ba 0x893 0x8c0 0x8cf 0x8c2 0x894 0x8ab 0x8be 0x89a 0x8a1 0x8c4 0x8be 0x891 0x8b7 0x8d7 0x8c7 0x8a1 0x8c9 0x8e5 0x8af 0x8d6 0x8b9 0x8d2 0x8b9 0x8bd 0x8a6 0x8ba 0x8a5 0x8ac 0x891 0x8d5 0x89b 0x8c9 0x8af 0x8c7 0x8a2 0x8a1 0x8ec 0x8c1 0x8b6 0x8a4 0x8cb 0x8be 0x8b3 0x8e3 0x8a1 0x8b2 0x8ad 0x8ba 0x8ac 0x8d2 0x8b3 0x8de 0x8b6 0x8c5 0x8ba 0x8c7 0x8ce 0x8a5 0x8b3 0x8c1 0x8ba 0x8a6 0x8c7 0x8d5 0x8bd 0x8b0 0x8b9 0x8d6 0x8ab 0x8b9 0x89d 0x8c8 0x8bb 0x8a5 0x8c8 0x8a8 0x8a9 0x8b0 0x8e0 0x8c1 0x8ac 0x8a8 0x8b6 0x8cb 0x8dc 0x8c8 0x8d6 0x8b9 0x8b4 0x8b6 0x8c8 0x8a4 0x8a2 0x8b0 0x8c2 0x8e1 0x8b4 0x8b7 0x8da 0x8a5 0x8ce 0x8b3 0x8d0 0x8a2 0x8c9 0x8d9 0x8af 0x8ac 0x883 0x8c7 0x89e 0x8c2 0x8d6 0x8c8 0x8bd 0x8da 0x8cc 0x8ba 0x88c 0x8b2 0x8be 0x8a8 0x8c0 0x896 0x89d 0x8ab 0x8c8 0x8e0 0x8cc 0x8a9 0x8a9 0x8ba 0x8d0 0x890 0x886 0x8bd 0x8bd 0x8d7 0x8d3 0x8c0 0x8a1 0x8c9 0x8dc 0x8c8 0x89f 0x8dd 0x8d0 0x8d2 0x8be 0x8ad 0x8af 0x89a 0x896 0x8ac 0x8c4 0x8e7 0x8cb 0x89e 0x8b9 0x8e8 0x8ce 0x8c5 0x8e0 0x8be 0x8b0 0x8dd 0x8d5 0x8b0 0x8ab 0x8bd 0x8cf 0x8af 0x8d3 0x8c8 0x8b9 0x8b4 0x8c4 0x8d0 0x8d6 0x8c8 0x898 0x8e4 0x8a9 0x8f1 0x8e8 0x8b2 0x8e1 0x8b3 0x8ce 0x8a1 0x8c4 0x8b4 0x8cb 0x88a 0x8af 0x8b2 0x8b4 0x8a9 0x89d 0x897 0x8be 0x8ad 0x8b7 0x8c0 0x8d0 0x8d3 0x8d5 0x8ba 0x8cc 0x8c9 0x8bb 0x8bd 0x8ac 0x8d5 0x8c1 0x8a8 0x8c5 0x8bd 0x897 0x8c9 0x8be 0x8a2 0x8ac 0x8b0 0x8bd 0x8b7 0x8dd 0x8d7 0x8b2 0x8d7 0x8e8 0x8cb 0x8bb 0x8a9 0x8b7 0x8a1 0x8b4 0x89f 0x8b9 0x8d9 0x8a5 0x8d3 0x8ba 0x8b3 0x8a9 0x8c4 0x8c0 0x8a6 0x8c9 0x8a4 0x8c2 0x8ad 0x8ad 0x8cc 0x8b3 0x8b3 0x8d2 0x8b0 0x8ba 0x889 0x8c9 0x8a9 0x8ad 0x8cf 0x8c2 0x8d3 0x8af 0x8bb 0x8a8 0x89e 0x8d3 0x8ce 0x8ba 0x8c0 0x8bd 0x8c0 0x8b6 0x8bb 0x8a4 0x8ab 0x8c0 0x89f 0x8b0 0x8d7 0x8eb 0x8c5 0x8a5 0x8c4 0x8a4 0x8ba 0x8b2 0x8c0 0x8a8 0x8cb 0x8ac 0x8b3 0x88c 0x8c8 0x89e 0x8a4 0x89e 0x8d0 0x8be 0x8b9 0x8cf 0x8b6 0x8ab 0x8a8 0x8b6 0x8a6 0x8c8 0x8d5 0x8cf 0x8d9 0x8b7 0x8a5 0x8ce 0x898 0x8c7 0x89e 0x8d5 0x8cc 0x891 0x8bd 0x8c8 0x8c8 0x8a6 0x8a8 0x8d6 0x897 0x8ad 0x8c0 0x8a2 0x8c1 0x8b6 0x894 0x89d 0x8ac 0x8b3 0x8c2 0x8a8 0x8c7 0x8c7 0x8cc 0x8d0 0x8ba 0x8b7 0x8e4 0x89b 0x8d5 0x8be 0x8ad 0x8cf 0x8c8 0x8b4 0x8ba 0x8ad 0x89e 0x8c9 0x8bb 0x8a4 0x8e3 0x8c8 0x8d6 0x8cc 0x8c8 0x8ac 0x8ad 0x8b6 0x8b2 0x8c4 0x8a8 0x8d7 0x8bd 0x8b4 0x8cc 0x8a2 0x8b9 0x8a9 0x8b9 0x8bd 0x8a8 0x8bd 0x89b 0x89f 0x8ac 0x8c8 0x890 0x8a8 0x8d3 0x89f 0x8e4 0x8c1 0x890 0x8c7 0x8c4 0x8a6 0x8c2 0x8c5 0x8c7 0x8a9 0x8bd 0x8b6 0x8da 0x8c0 0x8a5 0x8be 0x8a6 0x8c8 0x8c8 0x8d6 0x89d 0x8b0 0x89b 0x8c9 0x8ba 0x8b4 0x88f 0x8c7 0x8b4 0x8bb 0x8b6 0x8ce 0x8a4 0x8b6 0x8e1 0x8b7 0x8c1 0x8cb 0x8c2 0x8af 0x8c2 0x8c0 0x8b9 0x8b6 0x8b3 0x8c0 0x8c5 0x8c7 0x8c5 0x8bb 0x8bd 0x8af 0x8ce 0x8c2 0x8d5 0x8be 0x8d5 0x8cf 0x8e0 0x8c7 0x8de 0x8c0 0x8cf 0x8d3 0x89a 0x8c2 0x8a8 0x8b6 0x8b3 0x89e 0x8c7 0x8c5 0x8b4 0x8a4 0x8c5 0x8a6 0x8ad 0x8d7 0x8c4 0x8cc 0x8a6 0x8b6 0x8b9 0x8da 0x8c0 0x8c0 0x8c2 0x8ba 0x8bd 0x8c7 0x8dd 0x8b7 0x8a1 0x8a4 0x8a2 0x8a5 0x8a9 0x8c2 0x8c4 0x8b4 0x8b9 0x8cb 0x8a8 0x8c8 0x8bb 0x8af 0x8ce 0x889 0x8cb 0x8a6 0x8c1 0x8a1 0x8cb 0x8c5 0x8e7 0x8bd 0x8c8 0x896 0x8c4 0x8a6 0x8c9 0x89f 0x8e0 0x8d3 0x8b9 0x89d 0x8d2 0x8c2 0x89a 0x8b2 0x8cc 0x8cb 0x8e5 0x8a2 0x8cb 0x8cc 0x8d9 0x8a5 0x8c8 0x8be 0x8a9 0x8b4 0x8b9 0x8bd 0x8ac 0x898 0x8ba 0x8bb 0x8b4 0x8e5 0x8b3 0x8ce 0x8ad 0x8a9 0x8e0 0x8cf 0x8c0 0x8c0 0x8a6 0x8c0 0x8ce 0x8c1 0x8a2 0x8ac 0x89d 0x8c0 0x89d 0x8d9 0x8de 0x89d 0x8da 0x8ab 0x8ce 0x8bb 0x8d2 0x8b2 0x8c0 0x8d5 0x89f 0x8a4 0x8b3 0x8cb 0x8c7 0x8ad 0x8c0 0x897 0x8b9 0x89d 0x8b4 0x8b0 0x8a8 0x8b7 0x8b9 0x893 0x883 0x8d2 0x8a4 0x8b9 0x8b7 0x8e8 0x8a2 0x8bb 0x8a6 0x8c8 0x8d7 0x8ce 0x889 0x8dd 0x8c1 0x8b9 0x896 0x8bb 0x8cf 0x8a8 0x8c7 0x89f 0x8cb 0x8a8 0x8c1 0x8a1 0x8b9 0x8ce 0x8c1 0x8b6 0x8c5 0x8ea 0x8e7 0x89a 0x8cc 0x89f 0x8f5 0x8c1 0x8a9 0x8be 0x888 0x896 0x8b3 0x897 0x8cc 0x8a4 0x8c1 0x897 0x8b4 0x8b0 0x89b 0x8bb 0x886 0x8c5 0x8f8 0x8bb 0x89d 0x8d2 0x8b3 0x8cc 0x8a1 0x8cf 0x8de 0x8cc 0x89d 0x8b0 0x8b4 0x89f 0x89b 0x8b4 0x8a8 0x8d9 0x896 0x89d 0x8a5 0x8a5 0x8e7 0x8a9 0x8af 0x8a1 0x8a2 0x8ce 0x8b0 0x8bd 0x8cc 0x8b0 0x8b9 0x8cb 0x8b9 0x8e7 0x8b3 0x8cc 0x8b0 0x8d7 0x898 0x8cc 0x89d 0x8d9 0x8da 0x8ac 0x8a8 0x8b3 0x8b2 0x8d6 0x8e1 0x8d3 0x8c8 0x8c1 0x8b4 0x8b0 0x8a8 0x8ce 0x8bb 0x8ac 0x8b9 0x8ac 0x8d3 0x8c8 0x8ba 0x8c1 0x8d7 0x8c5 0x8b9 0x8d2 0x8d6 0x8ba 0x8c8 0x8cb 0x8c1 0x8bb 0x8cb 0x8ba 0x8be 0x8b3 0x8c4 0x8a5 0x8be 0x8e3 0x8c5 0x8c9 0x8a4 0x8cb 0x8b9 0x89f 0x8c8 0x8c5 0x8d2 0x8b6 0x8af 0x8ba 0x8bd 0x8c2 0x8c8 0x8dc 0x8c8 0x8ad 0x896 0x8cf 0x8b7 0x8ba 0x8ab 0x8ba 0x8a8 0x8d0 0x8c0 0x896 0x8d5 0x89d 0x8ce 0x8c8 0x8a2 0x8ba 0x8ba 0x8d5 0x8c2 0x8c2 0xf00 0xf00 0xf00>;
            PS_Config_Lmt_Open_Rawdata_N = <0x471 0x54d 0x558 0x55d 0x54d 0x54a 0x548 0x547 0x554 0x549 0x53b 0x538 0x529 0x51c 0x518 0x514 0x523 0x526 0x514 0x522 0x540 0x54d 0x537 0x550 0x54b 0x55e 0x546 0x55c 0x558 0x56a 0x553 0x57a 0x471 0x54f 0x55a 0x560 0x54c 0x54b 0x547 0x547 0x54d 0x544 0x536 0x533 0x528 0x51a 0x514 0x513 0x522 0x526 0x514 0x524 0x53e 0x54a 0x535 0x54d 0x548 0x55b 0x541 0x559 0x557 0x56b 0x553 0x579 0x475 0x54d 0x557 0x55f 0x557 0x54a 0x547 0x545 0x55f 0x54b 0x53b 0x532 0x532 0x51e 0x519 0x513 0x526 0x519 0x514 0x51e 0x53e 0x53a 0x538 0x549 0x54c 0x54a 0x547 0x556 0x556 0x556 0x555 0x576 0x474 0x54b 0x553 0x55b 0x550 0x544 0x541 0x53d 0x551 0x53e 0x52e 0x525 0x528 0x513 0x50e 0x507 0x51d 0x510 0x50d 0x516 0x534 0x530 0x52f 0x540 0x540 0x53d 0x53e 0x54c 0x550 0x54f 0x550 0x56e 0x457 0x531 0x546 0x546 0x534 0x528 0x52f 0x528 0x536 0x525 0x51a 0x511 0x505 0x4f4 0x4f4 0x4eb 0x504 0x4f2 0x4e4 0x4ea 0x51f 0x51d 0x50b 0x51c 0x534 0x532 0x521 0x52e 0x544 0x544 0x535 0x552 0x46e 0x549 0x55e 0x561 0x54d 0x542 0x549 0x542 0x54b 0x53a 0x530 0x526 0x522 0x512 0x514 0x50b 0x526 0x514 0x505 0x50a 0x53d 0x538 0x528 0x537 0x54a 0x549 0x535 0x543 0x55c 0x55c 0x54c 0x565 0x465 0x547 0x551 0x54b 0x544 0x53d 0x538 0x52b 0x543 0x534 0x524 0x516 0x510 0x503 0x4ff 0x4f3 0x50a 0x502 0x4f7 0x501 0x526 0x529 0x523 0x532 0x53b 0x542 0x539 0x541 0x54f 0x552 0x54e 0x55f 0x463 0x546 0x54d 0x548 0x53c 0x537 0x531 0x524 0x537 0x527 0x518 0x50a 0x506 0x4f9 0x4f5 0x4e9 0x502 0x4fa 0x4ef 0x4f9 0x51d 0x520 0x519 0x529 0x531 0x538 0x52f 0x538 0x549 0x54f 0x549 0x55b 0x466 0x54c 0x554 0x541 0x541 0x540 0x53d 0x524 0x541 0x538 0x529 0x510 0x50b 0x507 0x4fc 0x4ea 0x4fc 0x4f9 0x4f3 0x4ec 0x518 0x520 0x51b 0x51f 0x52e 0x53a 0x52f 0x530 0x53f 0x547 0x541 0x53e 0x464 0x549 0x552 0x53f 0x53c 0x53c 0x536 0x51e 0x535 0x52e 0x51e 0x504 0x504 0x4ff 0x4f8 0x4e3 0x4f3 0x4f0 0x4ea 0x4e6 0x50e 0x517 0x512 0x517 0x525 0x531 0x528 0x529 0x53e 0x547 0x540 0x53b 0x46e 0x555 0x54e 0x547 0x544 0x549 0x537 0x529 0x546 0x540 0x525 0x513 0x513 0x50d 0x4fe 0x4ec 0x4fe 0x4f5 0x4f5 0x4ff 0x51c 0x51f 0x520 0x532 0x534 0x538 0x535 0x543 0x547 0x549 0x54a 0x548 0x46c 0x552 0x54c 0x544 0x53e 0x543 0x532 0x521 0x53b 0x534 0x519 0x506 0x509 0x502 0x4f5 0x4e3 0x4f5 0x4ed 0x4ee 0x4f8 0x513 0x516 0x517 0x52b 0x52b 0x52e 0x52c 0x53e 0x544 0x544 0x546 0x543 0x47b 0x54b 0x549 0x548 0x544 0x540 0x52f 0x526 0x544 0x534 0x51a 0x50f 0x50f 0x504 0x4f5 0x4e7 0x501 0x4f7 0x4fd 0x4f3 0x520 0x51f 0x526 0x526 0x537 0x537 0x53b 0x537 0x54c 0x54c 0x555 0x52f 0x479 0x54a 0x548 0x546 0x540 0x53a 0x529 0x520 0x53a 0x529 0x50f 0x504 0x504 0x4f9 0x4ea 0x4de 0x4f9 0x4f0 0x4f6 0x4ed 0x517 0x517 0x51e 0x51f 0x52e 0x52f 0x534 0x532 0x547 0x548 0x550 0x52b 0x485 0x556 0x555 0x553 0x541 0x546 0x53a 0x534 0x53f 0x53a 0x527 0x51d 0x509 0x508 0x500 0x4f6 0x4fd 0x4f8 0x507 0x4f9 0x51b 0x521 0x532 0x52b 0x531 0x53d 0x544 0x53b 0x549 0x552 0x559 0x528 0x481 0x555 0x553 0x551 0x53b 0x541 0x535 0x52e 0x535 0x52f 0x51c 0x512 0x4fd 0x4fb 0x4f3 0x4ea 0x4f5 0x4f2 0x4ff 0x4f2 0x512 0x51a 0x529 0x524 0x52a 0x535 0x53d 0x537 0x541 0x549 0x552 0x520 0x48f 0x551 0x54f 0x54f 0x53f 0x541 0x532 0x52d 0x53d 0x532 0x51c 0x514 0x505 0x501 0x4f5 0x4ee 0x4ff 0x4fc 0x4eb 0x4fd 0x520 0x525 0x517 0x532 0x537 0x53d 0x52a 0x544 0x54e 0x552 0x543 0x525 0x48d 0x550 0x54d 0x54c 0x53b 0x53d 0x52c 0x526 0x532 0x528 0x513 0x50a 0x4fd 0x4f7 0x4ec 0x4e4 0x4f8 0x4f5 0x4e4 0x4f6 0x516 0x51d 0x510 0x52b 0x52f 0x535 0x526 0x53f 0x54a 0x54f 0x53e 0x51f 0x49c 0x552 0x559 0x54f 0x542 0x543 0x53d 0x52f 0x53e 0x534 0x526 0x515 0x506 0x504 0x4fe 0x4f2 0x4fb 0x509 0x4fe 0x4fa 0x51c 0x535 0x52c 0x531 0x536 0x54f 0x540 0x544 0x550 0x565 0x55c 0x51a 0x49c 0x550 0x559 0x54c 0x53e 0x53d 0x538 0x529 0x536 0x52a 0x51d 0x50b 0x4fd 0x4fb 0x4f5 0x4e8 0x4f3 0x503 0x4f8 0x4f4 0x513 0x52e 0x524 0x52a 0x52f 0x549 0x53a 0x53e 0x54c 0x561 0x558 0x514 0x4b2 0x561 0x55e 0x54f 0x547 0x54f 0x53e 0x529 0x542 0x53d 0x526 0x50f 0x509 0x50e 0x4fe 0x4eb 0x4f5 0x4ff 0x4ff 0x4ff 0x519 0x52a 0x52f 0x536 0x532 0x544 0x545 0x548 0x549 0x55e 0x561 0x511 0x4b1 0x561 0x55e 0x54e 0x543 0x54a 0x539 0x525 0x539 0x535 0x51d 0x507 0x501 0x504 0x4f6 0x4e3 0x4ef 0x4f8 0x4f9 0x4fb 0x510 0x523 0x527 0x52e 0x52c 0x53e 0x540 0x544 0x545 0x55b 0x55e 0x50e 0x4bc 0x55a 0x55e 0x552 0x54a 0x54a 0x53e 0x52e 0x547 0x53a 0x528 0x511 0x50e 0x50b 0x4fe 0x4ec 0x4f3 0x4f6 0x4f6 0x4ff 0x517 0x522 0x526 0x53a 0x52f 0x53b 0x53c 0x54d 0x549 0x553 0x555 0x507 0x4ba 0x55a 0x55c 0x551 0x546 0x546 0x539 0x528 0x540 0x531 0x51f 0x508 0x508 0x502 0x4f5 0x4e3 0x4ed 0x4f0 0x4f1 0x4fb 0x50f 0x519 0x51f 0x533 0x529 0x536 0x535 0x549 0x545 0x550 0x551 0x501 0x4c5 0x559 0x561 0x55c 0x541 0x546 0x542 0x538 0x53b 0x532 0x528 0x51a 0x502 0x504 0x501 0x4f7 0x4ed 0x4f4 0x509 0x4ff 0x514 0x520 0x53b 0x53a 0x52c 0x53a 0x551 0x54c 0x548 0x556 0x56d 0x4fc 0x4c5 0x55a 0x562 0x55b 0x53e 0x541 0x53d 0x532 0x535 0x52c 0x522 0x513 0x4f9 0x4fc 0x4f8 0x4ef 0x4e7 0x4ef 0x504 0x4fa 0x50b 0x519 0x534 0x534 0x529 0x536 0x54c 0x54a 0x546 0x554 0x56b 0x4f8 0x4e4 0x558 0x562 0x555 0x556 0x543 0x541 0x531 0x54d 0x532 0x529 0x513 0x510 0x501 0x4fc 0x4ef 0x4ef 0x4f9 0x50a 0x4f8 0x519 0x528 0x53e 0x531 0x535 0x544 0x553 0x546 0x54f 0x55f 0x570 0x4e9 0x4e4 0x557 0x562 0x554 0x552 0x53f 0x53d 0x52c 0x545 0x529 0x51f 0x50b 0x507 0x4f9 0x4f3 0x4e6 0x4e9 0x4f3 0x502 0x4f2 0x510 0x520 0x537 0x529 0x52e 0x53e 0x54f 0x540 0x54c 0x55b 0x56e 0x4e5 0x4f2 0x556 0x55f 0x564 0x558 0x542 0x53d 0x53e 0x54f 0x52c 0x51f 0x520 0x514 0x4fa 0x4f5 0x4fb 0x4f8 0x500 0x4f8 0x4f7 0x523 0x52f 0x52f 0x531 0x540 0x54a 0x545 0x545 0x55c 0x565 0x564 0x4dc 0x4f3 0x558 0x55f 0x565 0x554 0x53f 0x538 0x539 0x547 0x525 0x518 0x519 0x50d 0x4f3 0x4ed 0x4f5 0x4f3 0x4fb 0x4f4 0x4f3 0x51c 0x528 0x529 0x52b 0x53a 0x544 0x541 0x541 0x559 0x562 0x561 0x4db 0x4ef 0x557 0x565 0x553 0x547 0x542 0x541 0x52f 0x540 0x52d 0x526 0x510 0x505 0x4fa 0x4fb 0x4ee 0x4f2 0x4f2 0x4ff 0x502 0x51e 0x522 0x536 0x53b 0x538 0x53d 0x54e 0x54e 0x555 0x55a 0x56d 0x4d9 0x4ef 0x557 0x564 0x554 0x544 0x53f 0x53e 0x52b 0x537 0x524 0x51e 0x508 0x4fd 0x4f3 0x4f3 0x4e7 0x4ec 0x4ef 0x4fb 0x4fe 0x516 0x51c 0x52f 0x535 0x52f 0x537 0x546 0x549 0x550 0x557 0x56b 0x4d6 0x4f6 0x556 0x54c 0x559 0x53e 0x540 0x528 0x530 0x535 0x528 0x50c 0x50e 0x4f9 0x4f4 0x4de 0x4ea 0x4e2 0x4ee 0x4fa 0x4f8 0x511 0x51d 0x533 0x534 0x52c 0x538 0x54a 0x549 0x54b 0x553 0x56b 0x4c9 0x4f9 0x558 0x54c 0x558 0x53d 0x53c 0x525 0x52c 0x52f 0x522 0x505 0x507 0x4f2 0x4ed 0x4d7 0x4e3 0x4de 0x4e9 0x4f6 0x4f4 0x50a 0x517 0x52e 0x52e 0x529 0x534 0x547 0x546 0x549 0x553 0x569 0x4c6 0x51a 0x55b 0x564 0x55c 0x557 0x542 0x540 0x534 0x54a 0x52b 0x521 0x515 0x50a 0x4f5 0x4f0 0x4ef 0x4f0 0x503 0x4ec 0x4f3 0x520 0x534 0x526 0x530 0x540 0x552 0x53e 0x544 0x55f 0x571 0x561 0x4b7 0x51c 0x55b 0x565 0x55b 0x555 0x540 0x53c 0x530 0x543 0x525 0x51b 0x50e 0x506 0x4f2 0x4eb 0x4eb 0x4ec 0x4fe 0x4e7 0x4f0 0x51a 0x52e 0x521 0x52b 0x53e 0x54f 0x53b 0x542 0x560 0x571 0x560 0x4b7 0x520 0x54f 0x568 0x55c 0x54f 0x535 0x540 0x531 0x53e 0x51c 0x523 0x510 0x4ff 0x4e7 0x4f6 0x4ed 0x4fa 0x4f5 0x4f8 0x4f4 0x52c 0x526 0x52f 0x532 0x54a 0x543 0x545 0x547 0x56a 0x563 0x565 0x4b1 0x521 0x551 0x568 0x55c 0x54b 0x532 0x53d 0x52e 0x539 0x516 0x51e 0x50a 0x4f8 0x4e1 0x4ef 0x4e6 0x4f5 0x4f0 0x4f3 0x4f1 0x525 0x521 0x529 0x52e 0x546 0x540 0x543 0x547 0x568 0x562 0x564 0x4b0 0x53d 0x55b 0x557 0x550 0x55a 0x540 0x52f 0x524 0x54a 0x526 0x510 0x501 0x50a 0x4f2 0x4e0 0x4de 0x4db 0x4e4 0x4f9 0x4ee 0x50c 0x516 0x532 0x52b 0x52c 0x537 0x549 0x542 0x54c 0x55b 0x568 0x49e 0x53e 0x55d 0x558 0x550 0x558 0x53e 0x52b 0x522 0x544 0x520 0x50a 0x4fb 0x503 0x4ec 0x4d8 0x4d8 0x4d7 0x4e0 0x4f5 0x4ea 0x507 0x511 0x52e 0x526 0x529 0x535 0x546 0x540 0x549 0x55a 0x567 0x49b 0x531 0x55d 0x565 0x550 0x541 0x53e 0x53b 0x523 0x533 0x523 0x51c 0x500 0x4f3 0x4ee 0x4ea 0x4e0 0x4d9 0x4e4 0x4e6 0x4ef 0x50c 0x517 0x520 0x52b 0x52c 0x535 0x53a 0x542 0x54d 0x555 0x560 0x49b 0x533 0x55e 0x568 0x550 0x540 0x53c 0x53a 0x520 0x52e 0x51f 0x517 0x4fb 0x4ed 0x4e6 0x4e0 0x4d8 0x4d5 0x4e1 0x4e1 0x4ea 0x505 0x510 0x51d 0x526 0x529 0x532 0x53a 0x541 0x54a 0x551 0x55e 0x498 0x542 0x55d 0x562 0x555 0x544 0x540 0x538 0x52a 0x534 0x524 0x518 0x507 0x4f5 0x4f0 0x4e8 0x4e7 0x4de 0x4e1 0x4ed 0x4dd 0x511 0x514 0x52a 0x519 0x535 0x533 0x546 0x52f 0x55b 0x554 0x56e 0x489 0x544 0x55f 0x564 0x556 0x543 0x53d 0x535 0x527 0x52f 0x51f 0x513 0x502 0x4ef 0x4ea 0x4e1 0x4e1 0x4da 0x4dd 0x4e8 0x4d8 0x50b 0x50d 0x526 0x515 0x532 0x52f 0x544 0x52f 0x558 0x552 0x56e 0x486 0x57c 0x577 0x588 0x56f 0x577 0x55c 0x55e 0x544 0x569 0x544 0x53e 0x523 0x52a 0x513 0x510 0x505 0x50e 0x513 0x51c 0x511 0x541 0x543 0x55b 0x54c 0x562 0x560 0x575 0x561 0x583 0x580 0x597 0x4b5 0x55d 0x557 0x565 0x54b 0x54f 0x534 0x534 0x519 0x53a 0x514 0x50f 0x4f3 0x4f7 0x4e0 0x4dc 0x4d4 0x4dc 0x4e2 0x4ed 0x4e2 0x50e 0x514 0x52c 0x51f 0x537 0x537 0x54d 0x53c 0x55f 0x55c 0x574 0x491 0x56f 0x57e 0x57b 0x564 0x565 0x563 0x553 0x53b 0x556 0x549 0x537 0x51a 0x519 0x519 0x508 0x4ff 0x502 0x502 0x510 0x508 0x534 0x534 0x54a 0x541 0x555 0x552 0x561 0x553 0x577 0x572 0x585 0x4a9 0x570 0x581 0x57d 0x567 0x564 0x561 0x550 0x538 0x552 0x546 0x532 0x517 0x513 0x513 0x502 0x4f8 0x4fd 0x4fe 0x50e 0x506 0x52e 0x52f 0x547 0x53d 0x551 0x550 0x560 0x553 0x576 0x571 0x584 0x4a7 0x569 0x579 0x579 0x570 0x563 0x55c 0x54f 0x543 0x555 0x540 0x530 0x51f 0x518 0x510 0x501 0x505 0x4f8 0x50b 0x506 0x50b 0x529 0x53d 0x542 0x548 0x549 0x55b 0x55a 0x55f 0x56b 0x57d 0x57e 0x4b4 0x56b 0x57a 0x57a 0x56f 0x561 0x559 0x54c 0x53f 0x54f 0x53b 0x52b 0x51a 0x510 0x508 0x4f8 0x4fb 0x4f0 0x505 0x501 0x505 0x523 0x537 0x53d 0x544 0x548 0x559 0x55b 0x55f 0x56b 0x57c 0x57d 0x4b3 0xfffffe01 0xfffffe01 0xfffffe01>;
            PS_Config_Lmt_Open_Rawdata_P = <0xa5e 0xc60 0xc79 0xc84 0xc5e 0xc57 0xc53 0xc52 0xc6f 0xc56 0xc36 0xc2d 0xc0c 0xbed 0xbe3 0xbdb 0xbfe 0xc05 0xbdb 0xbfa 0xc41 0xc5e 0xc2c 0xc65 0xc5a 0xc87 0xc4e 0xc83 0xc78 0xca3 0xc6c 0xcc9 0xa5e 0xc64 0xc7d 0xc8b 0xc5c 0xc5a 0xc50 0xc52 0xc60 0xc49 0xc29 0xc22 0xc08 0xbe7 0xbdb 0xbd8 0xbfb 0xc05 0xbdb 0xbff 0xc3d 0xc59 0xc26 0xc5e 0xc53 0xc80 0xc44 0xc7a 0xc76 0xca6 0xc6c 0xcc6 0xa68 0xc60 0xc76 0xc88 0xc76 0xc59 0xc52 0xc4c 0xc88 0xc5a 0xc36 0xc1f 0xc1f 0xbf1 0xbe6 0xbd7 0xc03 0xbe6 0xbdb 0xbf1 0xc3b 0xc32 0xc2d 0xc55 0xc5c 0xc57 0xc52 0xc75 0xc73 0xc73 0xc71 0xcbe 0xa64 0xc5a 0xc6e 0xc80 0xc67 0xc4b 0xc44 0xc3a 0xc68 0xc3b 0xc16 0xc01 0xc08 0xbd8 0xbcd 0xbbc 0xbee 0xbd0 0xbc9 0xbdf 0xc24 0xc1b 0xc18 0xc40 0xc41 0xc3a 0xc3d 0xc5c 0xc65 0xc64 0xc67 0xcad 0xa20 0xc1e 0xc4e 0xc4e 0xc25 0xc09 0xc1a 0xc08 0xc29 0xc01 0xbe9 0xbd2 0xbb6 0xb8f 0xb8f 0xb7a 0xbb5 0xb8a 0xb6b 0xb79 0xbf3 0xbee 0xbc6 0xbec 0xc25 0xc21 0xbf8 0xc16 0xc49 0xc4b 0xc28 0xc6a 0xa57 0xc56 0xc87 0xc8e 0xc5e 0xc45 0xc56 0xc45 0xc5a 0xc33 0xc1b 0xc03 0xbfa 0xbd5 0xbd9 0xbc4 0xc05 0xbd9 0xbb6 0xbc3 0xc3a 0xc2f 0xc08 0xc2b 0xc59 0xc55 0xc26 0xc47 0xc83 0xc83 0xc5d 0xc98 0xa42 0xc52 0xc68 0xc5a 0xc49 0xc3a 0xc2f 0xc0f 0xc47 0xc24 0xbff 0xbde 0xbd0 0xbb2 0xba8 0xb8e 0xbc2 0xbb1 0xb96 0xbae 0xc03 0xc0c 0xbfc 0xc21 0xc36 0xc45 0xc30 0xc44 0xc64 0xc6a 0xc61 0xc8a 0xa3c 0xc4e 0xc5e 0xc53 0xc37 0xc2c 0xc1e 0xbff 0xc2b 0xc06 0xbe3 0xbc2 0xbb9 0xb9a 0xb91 0xb76 0xbaf 0xb9d 0xb84 0xb9c 0xbf0 0xbf7 0xbe6 0xc0a 0xc1d 0xc2f 0xc1a 0xc2f 0xc56 0xc63 0xc56 0xc80 0xa43 0xc5d 0xc6f 0xc44 0xc42 0xc41 0xc39 0xbff 0xc42 0xc2f 0xc0c 0xbd0 0xbc6 0xbbb 0xba3 0xb77 0xba1 0xb9a 0xb8c 0xb7d 0xbe3 0xbf7 0xbea 0xbf4 0xc17 0xc32 0xc1a 0xc1b 0xc3e 0xc52 0xc44 0xc3d 0xa3f 0xc56 0xc6a 0xc3e 0xc37 0xc37 0xc29 0xbf1 0xc28 0xc17 0xbf1 0xbb5 0xbb5 0xbaa 0xb98 0xb67 0xb8e 0xb85 0xb79 0xb6e 0xbcd 0xbe2 0xbd5 0xbe2 0xc02 0xc1d 0xc09 0xc0a 0xc3d 0xc52 0xc40 0xc36 0xa57 0xc71 0xc61 0xc50 0xc49 0xc56 0xc2c 0xc0a 0xc4e 0xc41 0xc02 0xbd7 0xbd8 0xbc9 0xba7 0xb7c 0xba6 0xb91 0xb92 0xbaa 0xbed 0xbf3 0xbf5 0xc21 0xc24 0xc2d 0xc26 0xc48 0xc50 0xc55 0xc59 0xc53 0xa51 0xc6b 0xc5c 0xc4b 0xc3b 0xc47 0xc21 0xbf8 0xc36 0xc24 0xbe6 0xbb9 0xbc0 0xbaf 0xb91 0xb67 0xb92 0xb7e 0xb81 0xb99 0xbd7 0xbdf 0xbe0 0xc10 0xc10 0xc16 0xc13 0xc3b 0xc49 0xc4b 0xc4f 0xc48 0xa76 0xc5a 0xc56 0xc53 0xc4b 0xc41 0xc18 0xc05 0xc49 0xc25 0xbe7 0xbce 0xbce 0xbb4 0xb91 0xb72 0xbad 0xb96 0xba4 0xb8c 0xbf7 0xbf3 0xc03 0xc05 0xc2b 0xc2c 0xc36 0xc2c 0xc5c 0xc5d 0xc71 0xc1a 0xa70 0xc59 0xc53 0xc4e 0xc40 0xc33 0xc0c 0xbf7 0xc32 0xc0a 0xbce 0xbb4 0xbb5 0xb9c 0xb79 0xb5d 0xb9c 0xb85 0xb95 0xb7e 0xbe0 0xbe0 0xbf1 0xbf4 0xc16 0xc1a 0xc24 0xc1f 0xc52 0xc53 0xc67 0xc0f 0xa8c 0xc75 0xc71 0xc6c 0xc42 0xc4f 0xc33 0xc24 0xc3e 0xc32 0xc06 0xbee 0xbc0 0xbbd 0xbab 0xb95 0xba4 0xb99 0xbbb 0xb9a 0xbea 0xbf8 0xc21 0xc10 0xc1e 0xc39 0xc4b 0xc34 0xc55 0xc6b 0xc7a 0xc08 0xa84 0xc72 0xc6c 0xc68 0xc36 0xc44 0xc28 0xc17 0xc26 0xc1a 0xbed 0xbd5 0xba4 0xba0 0xb8c 0xb77 0xb92 0xb8b 0xbaa 0xb8a 0xbd5 0xbe7 0xc0c 0xbff 0xc0d 0xc26 0xc3a 0xc2c 0xc42 0xc56 0xc6b 0xbf5 0xaa4 0xc68 0xc63 0xc63 0xc3e 0xc44 0xc1f 0xc14 0xc39 0xc21 0xbed 0xbd9 0xbb8 0xbad 0xb92 0xb81 0xbaa 0xba3 0xb7a 0xba4 0xbf5 0xc02 0xbe2 0xc21 0xc2b 0xc3a 0xc0d 0xc49 0xc61 0xc6b 0xc47 0xc01 0xaa0 0xc65 0xc5e 0xc5d 0xc36 0xc39 0xc13 0xc05 0xc21 0xc09 0xbd8 0xbc3 0xba4 0xb96 0xb7c 0xb69 0xb98 0xb91 0xb6b 0xb93 0xbde 0xbee 0xbd0 0xc0f 0xc18 0xc28 0xc05 0xc3e 0xc57 0xc64 0xc3d 0xbf4 0xac3 0xc6a 0xc7c 0xc64 0xc45 0xc47 0xc39 0xc18 0xc3d 0xc24 0xc05 0xbdc 0xbb9 0xbb5 0xba7 0xb8a 0xb9f 0xbc0 0xba7 0xb9d 0xbed 0xc28 0xc11 0xc1e 0xc29 0xc64 0xc40 0xc4b 0xc65 0xc98 0xc83 0xbe7 0xac1 0xc65 0xc7a 0xc5d 0xc3b 0xc39 0xc2d 0xc0a 0xc29 0xc0d 0xbf0 0xbc4 0xba4 0xb9f 0xb92 0xb73 0xb8c 0xbb2 0xb99 0xb8f 0xbd8 0xc16 0xbff 0xc0d 0xc1a 0xc56 0xc32 0xc3d 0xc5d 0xc8e 0xc79 0xbdb 0xaf5 0xc8e 0xc87 0xc63 0xc52 0xc63 0xc3b 0xc0c 0xc45 0xc39 0xc03 0xbce 0xbc0 0xbcb 0xba7 0xb7a 0xb92 0xba8 0xba8 0xba8 0xbe5 0xc0d 0xc18 0xc29 0xc21 0xc4b 0xc4c 0xc53 0xc55 0xc86 0xc8e 0xbd4 0xaf2 0xc8d 0xc86 0xc61 0xc47 0xc59 0xc30 0xc01 0xc30 0xc26 0xbee 0xbbc 0xbad 0xbb5 0xb95 0xb67 0xb84 0xb99 0xb9c 0xb9f 0xbd0 0xbfc 0xc06 0xc16 0xc13 0xc3d 0xc40 0xc4b 0xc4c 0xc7f 0xc87 0xbcd 0xb0d 0xc7d 0xc87 0xc6b 0xc57 0xc57 0xc3d 0xc16 0xc52 0xc32 0xc08 0xbd2 0xbcd 0xbc6 0xba7 0xb7d 0xb8c 0xb95 0xb95 0xbaa 0xbe0 0xbfa 0xc05 0xc32 0xc18 0xc36 0xc37 0xc60 0xc55 0xc6c 0xc72 0xbbb 0xb09 0xc7d 0xc83 0xc68 0xc4f 0xc4f 0xc30 0xc08 0xc40 0xc1e 0xbf4 0xbbf 0xbbd 0xbb1 0xb92 0xb68 0xb7e 0xb85 0xb88 0xb9f 0xbce 0xbe6 0xbf4 0xc22 0xc0a 0xc29 0xc28 0xc55 0xc4c 0xc65 0xc68 0xbae 0xb21 0xc7a 0xc8d 0xc81 0xc44 0xc4e 0xc45 0xc2d 0xc34 0xc21 0xc09 0xbe7 0xbb1 0xbb5 0xbad 0xb96 0xb80 0xb8f 0xbc0 0xba8 0xbdb 0xbf5 0xc36 0xc33 0xc13 0xc32 0xc68 0xc5d 0xc53 0xc75 0xcaa 0xba3 0xb21 0xc7d 0xc8f 0xc80 0xc3d 0xc42 0xc3a 0xc21 0xc28 0xc11 0xbfb 0xbd8 0xb9c 0xba3 0xb99 0xb84 0xb72 0xb83 0xbb4 0xb9d 0xbc6 0xbe5 0xc25 0xc24 0xc0a 0xc29 0xc5d 0xc57 0xc4e 0xc6f 0xca4 0xb99 0xb69 0xc78 0xc8f 0xc71 0xc75 0xc48 0xc42 0xc1d 0xc5e 0xc1f 0xc0a 0xbd7 0xbd0 0xbae 0xba1 0xb84 0xb84 0xb9c 0xbc2 0xb99 0xbe5 0xc08 0xc3d 0xc1d 0xc26 0xc49 0xc6c 0xc4e 0xc64 0xc8a 0xcb1 0xb76 0xb6b 0xc76 0xc91 0xc6f 0xc6a 0xc3e 0xc3a 0xc13 0xc4c 0xc0c 0xbf4 0xbc4 0xbbc 0xb9c 0xb8c 0xb6f 0xb75 0xb8e 0xbb1 0xb8b 0xbd1 0xbf7 0xc2b 0xc0c 0xc16 0xc3b 0xc63 0xc40 0xc5c 0xc7f 0xcab 0xb6c 0xb8a 0xc75 0xc8a 0xc95 0xc78 0xc45 0xc39 0xc3d 0xc63 0xc13 0xbf3 0xbf5 0xbd9 0xb9d 0xb91 0xba0 0xb98 0xbab 0xb99 0xb96 0xbfe 0xc18 0xc1a 0xc1e 0xc40 0xc57 0xc4c 0xc4c 0xc81 0xc96 0xc95 0xb57 0xb8c 0xc78 0xc8a 0xc96 0xc6f 0xc3e 0xc2d 0xc30 0xc52 0xc02 0xbe3 0xbe6 0xbca 0xb8e 0xb7e 0xb91 0xb8e 0xba0 0xb8f 0xb8c 0xbed 0xc09 0xc0c 0xc0f 0xc32 0xc4b 0xc42 0xc42 0xc7a 0xc91 0xc8e 0xb54 0xb84 0xc76 0xc96 0xc6e 0xc52 0xc45 0xc44 0xc18 0xc40 0xc14 0xc05 0xbd1 0xbb6 0xb9d 0xb9f 0xb81 0xb8a 0xb8a 0xbaa 0xbb1 0xbf1 0xbfb 0xc29 0xc34 0xc2f 0xc3a 0xc61 0xc61 0xc71 0xc7d 0xca9 0xb50 0xb83 0xc76 0xc95 0xc6f 0xc49 0xc3e 0xc3b 0xc0f 0xc2c 0xbff 0xbf1 0xbbd 0xba4 0xb8e 0xb8c 0xb70 0xb7c 0xb83 0xba0 0xba7 0xbdf 0xbec 0xc1a 0xc26 0xc1a 0xc2c 0xc4f 0xc55 0xc67 0xc76 0xca4 0xb49 0xb95 0xc75 0xc5c 0xc7c 0xc3d 0xc40 0xc09 0xc1b 0xc28 0xc08 0xbc7 0xbcb 0xb9c 0xb8f 0xb5b 0xb79 0xb65 0xb81 0xb9d 0xb99 0xbd4 0xbee 0xc22 0xc24 0xc13 0xc2f 0xc59 0xc55 0xc5a 0xc6e 0xca4 0xb2a 0xb9a 0xc79 0xc5d 0xc79 0xc39 0xc37 0xc01 0xc11 0xc1a 0xbfa 0xbb6 0xbbc 0xb8b 0xb7e 0xb4c 0xb68 0xb5b 0xb76 0xb95 0xb8f 0xbc3 0xbe0 0xc16 0xc17 0xc0c 0xc25 0xc52 0xc4e 0xc55 0xc6c 0xca0 0xb23 0xbe9 0xc7f 0xc95 0xc83 0xc76 0xc45 0xc40 0xc25 0xc59 0xc0f 0xbf8 0xbdc 0xbc3 0xb92 0xb87 0xb83 0xb85 0xbb2 0xb7c 0xb8c 0xbf5 0xc24 0xc03 0xc1b 0xc41 0xc6a 0xc3d 0xc4b 0xc8a 0xcb4 0xc8d 0xb00 0xbed 0xc80 0xc96 0xc80 0xc71 0xc40 0xc37 0xc1b 0xc48 0xc02 0xbea 0xbcd 0xbb9 0xb8a 0xb7a 0xb7a 0xb7c 0xba6 0xb72 0xb87 0xbe7 0xc16 0xbf8 0xc0f 0xc3b 0xc63 0xc36 0xc45 0xc8b 0xcb2 0xc8b 0xb00 0xbf7 0xc63 0xc9d 0xc81 0xc64 0xc26 0xc41 0xc1e 0xc3d 0xbec 0xbfe 0xbd0 0xba8 0xb72 0xb93 0xb80 0xb9d 0xb92 0xb98 0xb8f 0xc11 0xc03 0xc1a 0xc21 0xc59 0xc48 0xc4c 0xc50 0xca2 0xc92 0xc96 0xaf2 0xbf8 0xc68 0xc9f 0xc83 0xc5a 0xc1f 0xc3a 0xc17 0xc30 0xbde 0xbf1 0xbc2 0xb99 0xb64 0xb84 0xb6f 0xb92 0xb87 0xb8c 0xb88 0xc02 0xbf8 0xc0c 0xc16 0xc4f 0xc41 0xc47 0xc50 0xc9d 0xc91 0xc95 0xaf0 0xc3a 0xc80 0xc76 0xc67 0xc7d 0xc40 0xc1a 0xbff 0xc57 0xc05 0xbd0 0xbae 0xbc2 0xb8a 0xb60 0xb5d 0xb54 0xb6b 0xb9a 0xb81 0xbc7 0xbdf 0xc21 0xc0f 0xc13 0xc2c 0xc55 0xc45 0xc5c 0xc80 0xc9d 0xac6 0xc3d 0xc84 0xc78 0xc65 0xc78 0xc3b 0xc10 0xbfa 0xc4b 0xbf7 0xbc2 0xba0 0xbb2 0xb7c 0xb4f 0xb4f 0xb4b 0xb60 0xb92 0xb77 0xbbc 0xbd2 0xc16 0xc05 0xc0a 0xc26 0xc4e 0xc41 0xc55 0xc7d 0xc9c 0xac0 0xc1e 0xc84 0xc98 0xc65 0xc42 0xc3d 0xc36 0xbfe 0xc22 0xbfc 0xbed 0xbab 0xb8c 0xb81 0xb77 0xb60 0xb50 0xb6b 0xb6e 0xb83 0xbc7 0xbe0 0xbf7 0xc0f 0xc13 0xc26 0xc32 0xc45 0xc5e 0xc71 0xc8b 0xabf 0xc22 0xc86 0xc9d 0xc67 0xc41 0xc37 0xc32 0xbf7 0xc16 0xbf4 0xbe2 0xba0 0xb7e 0xb6f 0xb61 0xb4d 0xb46 0xb62 0xb64 0xb79 0xbb8 0xbd1 0xbee 0xc05 0xc0c 0xc21 0xc32 0xc44 0xc57 0xc68 0xc86 0xab8 0xc45 0xc84 0xc91 0xc72 0xc4b 0xc41 0xc2f 0xc0d 0xc25 0xbff 0xbe3 0xbbc 0xb92 0xb87 0xb73 0xb72 0xb5d 0xb62 0xb7e 0xb59 0xbd2 0xbd9 0xc0d 0xbe6 0xc28 0xc22 0xc4e 0xc1a 0xc7f 0xc6f 0xcad 0xa96 0xc49 0xc88 0xc95 0xc73 0xc47 0xc3a 0xc28 0xc06 0xc1a 0xbf4 0xbd7 0xbaf 0xb84 0xb79 0xb64 0xb64 0xb52 0xb59 0xb73 0xb4d 0xbc4 0xbca 0xc03 0xbdc 0xc21 0xc1a 0xc49 0xc18 0xc79 0xc6b 0xcab 0xa8f 0xccd 0xcc2 0xce8 0xcae 0xcc2 0xc83 0xc87 0xc49 0xca0 0xc49 0xc3d 0xbfe 0xc0d 0xbd7 0xbd0 0xbb8 0xbcb 0xbd7 0xbed 0xbd2 0xc42 0xc47 0xc80 0xc5c 0xc8f 0xc8b 0xcbc 0xc8d 0xcdc 0xcd5 0xd0b 0xafc 0xc84 0xc76 0xc96 0xc5a 0xc64 0xc24 0xc24 0xbe6 0xc32 0xbdb 0xbce 0xb8e 0xb96 0xb61 0xb57 0xb44 0xb57 0xb65 0xb7e 0xb65 0xbcd 0xbd9 0xc11 0xbf4 0xc2b 0xc2c 0xc5e 0xc37 0xc8a 0xc83 0xcb9 0xaa8 0xcae 0xcd1 0xcca 0xc95 0xc96 0xc92 0xc6c 0xc34 0xc73 0xc55 0xc2b 0xbe9 0xbe6 0xbe6 0xbbd 0xba8 0xbaf 0xbaf 0xbd1 0xbbd 0xc24 0xc25 0xc59 0xc42 0xc71 0xc6a 0xc8e 0xc6e 0xcc2 0xcb5 0xce1 0xae0 0xcb0 0xcd8 0xcce 0xc9b 0xc95 0xc8e 0xc67 0xc2f 0xc6a 0xc4e 0xc21 0xbe0 0xbd7 0xbd8 0xbaf 0xb98 0xba4 0xba6 0xbcb 0xbb9 0xc16 0xc18 0xc50 0xc39 0xc68 0xc65 0xc8b 0xc6c 0xcbe 0xcb2 0xcdf 0xadc 0xca0 0xcc6 0xcc5 0xcb0 0xc92 0xc83 0xc64 0xc47 0xc71 0xc41 0xc1b 0xbf3 0xbe3 0xbd0 0xbae 0xbb6 0xb99 0xbc6 0xbb9 0xbc4 0xc0c 0xc39 0xc45 0xc53 0xc56 0xc80 0xc7d 0xc8a 0xca4 0xcd0 0xcd1 0xafb 0xca6 0xcc9 0xcc9 0xcae 0xc8e 0xc7a 0xc5d 0xc3e 0xc64 0xc36 0xc0f 0xbe9 0xbd1 0xbbd 0xb98 0xba0 0xb87 0xbb6 0xbae 0xbb8 0xbfc 0xc2b 0xc3a 0xc49 0xc53 0xc7c 0xc7f 0xc88 0xca4 0xccd 0xcd0 0xaf7 0x1400 0x1400 0x1400>;
            PS_Config_Lmt_Short_Rawdata_N = <0x2774 0x2774 0x2774 0x2774 0x2774 0x2774 0x2774 0x2774 0x2774 0x2774 0x2774 0x2774 0x2774 0x2774 0x2774 0x2774 0x2774 0x2774 0x2774 0x2774 0x2774 0x2774 0x2774 0x2774 0x2774 0x2774 0x2774 0x2774 0x2774 0x2774 0x2774 0x2774 0x2774 0x2774 0x2774 0x2774 0x2774 0x2774 0x2774 0x2774 0x2774 0x2774 0x2774 0x2774 0x2774 0x2774 0x2774 0x2774 0x2774 0x2774 0x2774 0x2774 0x2774 0x2774 0x2774 0x2774 0x2774 0x2774 0x2774 0x2774 0x2774 0x2774 0x2774 0x2774 0x2774 0x2774 0x2774 0x2774 0x2774 0x2774 0x2774 0x2774 0x2774 0x2774 0x2774 0x2774 0x2774 0x2774 0x2774 0x2774 0x2774 0x2774 0x2774 0x2774 0x2774 0x2774 0x2774 0x2774 0x2774 0x2774 0x2774 0x2774 0x2774 0x2774 0x2774 0x2774 0x2774 0x2774 0x2774 0x2774 0x2774 0x2774 0x2774 0x2774 0x2774 0x2774 0x2774 0x2774 0x2774 0x2774 0x2774 0x2774 0x2774 0x2774 0x2774 0x2774 0x2774 0x2774 0x2774 0x2774 0x2774 0x2774 0x2774 0x2774 0x2774 0x2774 0x2774 0x2774 0x2774 0x2774 0x2774 0x2774 0x2774 0x2774 0x2774 0x2774 0x2774 0x2774 0x2774 0x2774 0x2774 0x2774 0x2774 0x2774 0x2774 0x2774 0x2774 0x2774 0x2774 0x2774 0x2774 0x2774 0x2774 0x2774 0x2774 0x2774 0x2774 0x2774 0x2774 0x2774 0x2774 0x2774 0x2774 0x2774 0x2774 0x2774 0x2774 0x2774 0x2774 0x2774 0x2774 0x2774 0x2774 0x2774 0x2774 0x2774 0x2774 0x2774 0x2774 0x2774 0x2774 0x2774 0x2774 0x2774 0x2774 0x2774 0x2774 0x2774 0x2774 0x2774 0x2774 0x2774 0x2774 0x2774 0x2774 0x2774 0x2774 0x2774 0x2774 0x2774 0x2774 0x2774 0x2774 0x2774 0x2774 0x2774 0x2774 0x2774 0x2774 0x2774 0x2774 0x2774 0x2774 0x2774 0x2774 0x2774 0x2774 0x2774 0x2774 0x2774 0x2774 0x2774 0x2774 0x2774 0x2774 0x2774 0x2774 0x2774 0x2774 0x2774 0x2774 0x2774 0x2774 0x2774 0x2774 0x2774 0x2774 0x2774 0x2774 0x2774 0x2774 0x2774 0x2774 0x2774 0x2774 0x2774 0x2774 0x2774 0x2774 0x2774 0x2774 0x2774 0x2774 0x2774 0x2774 0x2774 0x2774 0x2774 0x2774 0x2774 0x2774 0x2774 0x2774 0x2774 0x2774 0x2774 0x2774 0x2774 0x2774 0x2774 0x2774 0x2774 0x2774 0x2774 0x2774 0x2774 0x2774 0x2774 0x2774 0x2774 0x2774 0x2774 0x2774 0x2774 0x2774 0x2774 0x2774 0x2774 0x2774 0x2774 0x2774 0x2774 0x2774 0x2774 0x2774 0x2774 0x2774 0x2774 0x2774 0x2774 0x2774 0x2774 0x2774 0x2774 0x2774 0x2774 0x2774 0x2774 0x2774 0x2774 0x2774 0x2774 0x2774 0x2774 0x2774 0x2774 0x2774 0x2774 0x2774 0x2774 0x2774 0x2774 0x2774 0x2774 0x2774 0x2774 0x2774 0x2774 0x2774 0x2774 0x2774 0x2774 0x2774 0x2774 0x2774 0x2774 0x2774 0x2774 0x2774 0x2774 0x2774 0x2774 0x2774 0x2774 0x2774 0x2774 0x2774 0x2774 0x2774 0x2774 0x2774 0x2774 0x2774 0x2774 0x2774 0x2774 0x2774 0x2774 0x2774 0x2774 0x2774 0x2774 0x2774 0x2774 0x2774 0x2774 0x2774 0x2774 0x2774 0x2774 0x2774 0x2774 0x2774 0x2774 0x2774 0x2774 0x2774 0x2774 0x2774 0x2774 0x2774 0x2774 0x2774 0x2774 0x2774 0x2774 0x2774 0x2774 0x2774 0x2774 0x2774 0x2774 0x2774 0x2774 0x2774 0x2774 0x2774 0x2774 0x2774 0x2774 0x2774 0x2774 0x2774 0x2774 0x2774 0x2774 0x2774 0x2774 0x2774 0x2774 0x2774 0x2774 0x2774 0x2774 0x2774 0x2774 0x2774 0x2774 0x2774 0x2774 0x2774 0x2774 0x2774 0x2774 0x2774 0x2774 0x2774 0x2774 0x2774 0x2774 0x2774 0x2774 0x2774 0x2774 0x2774 0x2774 0x2774 0x2774 0x2774 0x2774 0x2774 0x2774 0x2774 0x2774 0x2774 0x2774 0x2774 0x2774 0x2774 0x2774 0x2774 0x2774 0x2774 0x2774 0x2774 0x2774 0x2774 0x2774 0x2774 0x2774 0x2774 0x2774 0x2774 0x2774 0x2774 0x2774 0x2774 0x2774 0x2774 0x2774 0x2774 0x2774 0x2774 0x2774 0x2774 0x2774 0x2774 0x2774 0x2774 0x2774 0x2774 0x2774 0x2774 0x2774 0x2774 0x2774 0x2774 0x2774 0x2774 0x2774 0x2774 0x2774 0x2774 0x2774 0x2774 0x2774 0x2774 0x2774 0x2774 0x2774 0x2774 0x2774 0x2774 0x2774 0x2774 0x2774 0x2774 0x2774 0x2774 0x2774 0x2774 0x2774 0x2774 0x2774 0x2774 0x2774 0x2774 0x2774 0x2774 0x2774 0x2774 0x2774 0x2774 0x2774 0x2774 0x2774 0x2774 0x2774 0x2774 0x2774 0x2774 0x2774 0x2774 0x2774 0x2774 0x2774 0x2774 0x2774 0x2774 0x2774 0x2774 0x2774 0x2774 0x2774 0x2774 0x2774 0x2774 0x2774 0x2774 0x2774 0x2774 0x2774 0x2774 0x2774 0x2774 0x2774 0x2774 0x2774 0x2774 0x2774 0x2774 0x2774 0x2774 0x2774 0x2774 0x2774 0x2774 0x2774 0x2774 0x2774 0x2774 0x2774 0x2774 0x2774 0x2774 0x2774 0x2774 0x2774 0x2774 0x2774 0x2774 0x2774 0x2774 0x2774 0x2774 0x2774 0x2774 0x2774 0x2774 0x2774 0x2774 0x2774 0x2774 0x2774 0x2774 0x2774 0x2774 0x2774 0x2774 0x2774 0x2774 0x2774 0x2774 0x2774 0x2774 0x2774 0x2774 0x2774 0x2774 0x2774 0x2774 0x2774 0x2774 0x2774 0x2774 0x2774 0x2774 0x2774 0x2774 0x2774 0x2774 0x2774 0x2774 0x2774 0x2774 0x2774 0x2774 0x2774 0x2774 0x2774 0x2774 0x2774 0x2774 0x2774 0x2774 0x2774 0x2774 0x2774 0x2774 0x2774 0x2774 0x2774 0x2774 0x2774 0x2774 0x2774 0x2774 0x2774 0x2774 0x2774 0x2774 0x2774 0x2774 0x2774 0x2774 0x2774 0x2774 0x2774 0x2774 0x2774 0x2774 0x2774 0x2774 0x2774 0x2774 0x2774 0x2774 0x2774 0x2774 0x2774 0x2774 0x2774 0x2774 0x2774 0x2774 0x2774 0x2774 0x2774 0x2774 0x2774 0x2774 0x2774 0x2774 0x2774 0x2774 0x2774 0x2774 0x2774 0x2774 0x2774 0x2774 0x2774 0x2774 0x2774 0x2774 0x2774 0x2774 0x2774 0x2774 0x2774 0x2774 0x2774 0x2774 0x2774 0x2774 0x2774 0x2774 0x2774 0x2774 0x2774 0x2774 0x2774 0x2774 0x2774 0x2774 0x2774 0x2774 0x2774 0x2774 0x2774 0x2774 0x2774 0x2774 0x2774 0x2774 0x2774 0x2774 0x2774 0x2774 0x2774 0x2774 0x2774 0x2774 0x2774 0x2774 0x2774 0x2774 0x2774 0x2774 0x2774 0x2774 0x2774 0x2774 0x2774 0x2774 0x2774 0x2774 0x2774 0x2774 0x2774 0x2774 0x2774 0x2774 0x2774 0x2774 0x2774 0x2774 0x2774 0x2774 0x2774 0x2774 0x2774 0x2774 0x2774 0x2774 0x2774 0x2774 0x2774 0x2774 0x2774 0x2774 0x2774 0x2774 0x2774 0x2774 0x2774 0x2774 0x2774 0x2774 0x2774 0x2774 0x2774 0x2774 0x2774 0x2774 0x2774 0x2774 0x2774 0x2774 0x2774 0x2774 0x2774 0x2774 0x2774 0x2774 0x2774 0x2774 0x2774 0x2774 0x2774 0x2774 0x2774 0x2774 0x2774 0x2774 0x2774 0x2774 0x2774 0x2774 0x2774 0x2774 0x2774 0x2774 0x2774 0x2774 0x2774 0x2774 0x2774 0x2774 0x2774 0x2774 0x2774 0x2774 0x2774 0x2774 0x2774 0x2774 0x2774 0x2774 0x2774 0x2774 0x2774 0x2774 0x2774 0x2774 0x2774 0x2774 0x2774 0x2774 0x2774 0x2774 0x2774 0x2774 0x2774 0x2774 0x2774 0x2774 0x2774 0x2774 0x2774 0x2774 0x2774 0x2774 0x2774 0x2774 0x2774 0x2774 0x2774 0x2774 0x2774 0x2774 0x2774 0x2774 0x2774 0x2774 0x2774 0x2774 0x2774 0x2774 0x2774 0x2774 0x2774 0x2774 0x2774 0x2774 0x2774 0x2774 0x2774 0x2774 0x2774 0x2774 0x2774 0x2774 0x2774 0x2774 0x2774 0x2774 0x2774 0x2774 0x2774 0x2774 0x2774 0x2774 0x2774 0x2774 0x2774 0x2774 0x2774 0x2774 0x2774 0x2774 0x2774 0x2774 0x2774 0x2774 0x2774 0x2774 0x2774 0x2774 0x2774 0x2774 0x2774 0x2774 0x2774 0x2774 0x2774 0x2774 0x2774 0x2774 0x2774 0x2774 0x2774 0x2774 0x2774 0x2774 0x2774 0x2774 0x2774 0x2774 0x2774 0x2774 0x2774 0x2774 0x2774 0x2774 0x2774 0x2774 0x2774 0x2774 0x2774 0x2774 0x2774 0x2774 0x2774 0x2774 0x2774 0x2774 0x2774 0x2774 0x2774 0x2774 0x2774 0x2774 0x2774 0x2774 0x2774 0x2774 0x2774 0x2774 0x2774 0x2774 0x2774 0x2774 0x2774 0x2774 0x2774 0x2774 0x2774 0x2774 0x2774 0x2774 0x2774 0x2774 0x2774 0x2774 0x2774 0x2774 0x2774 0x2774 0x2774 0x2774 0x2774 0x2774 0x2774 0x2774 0x2774 0x2774 0x2774 0x2774 0x2774 0x2774 0x2774 0x2774 0x2774 0x2774 0x2774 0x2774 0x2774 0x2774 0x2774 0x2774 0x2774 0x2774 0x2774 0x2774 0x2774 0x2774 0x2774 0x2774 0x2774 0x2774 0x2774 0x2774 0x2774 0x2774 0x2774 0x2774 0x2774 0x2774 0x2774 0x2774 0x2774 0x2774 0x2774 0x2774 0x2774 0x2774 0x2774 0x2774 0x2774 0x2774 0x2774 0x2774 0x2774 0x2774 0x2774 0x2774 0x2774 0x2774 0x2774 0x2774 0x2774 0x2774 0x2774 0x2774 0x2774 0x2774 0x2774 0x2774 0x2774 0x2774 0x2774 0x2774 0x2774 0x2774 0x2774 0x2774 0x2774 0x2774 0x2774 0x2774 0x2774 0x2774 0x2774 0x2774 0x2774 0x2774 0x2774 0x2774 0x2774 0x2774 0x2774 0x2774 0x2774 0x2774 0x2774 0x2774 0x2774 0x2774 0x2774 0x2774 0x2774 0x2774 0x2774 0x2774 0x2774 0x2774 0x2774 0x2774 0x2774 0x2774 0x2774 0x2774 0x2774 0x2774 0x2774 0x2774 0x2774 0x2774 0x2774 0x2774 0x2774 0x2774 0x2774 0x2774 0x2774 0x2774 0x2774 0x2774 0x2774 0x2774 0x2774 0x2774 0x2774 0x2774 0x2774 0x2774 0x2774 0x2774 0x2774 0x2774 0x2774 0x2774 0x2774 0x2774 0x2774 0x2774 0x2774 0x2774 0x2774 0x2774 0x2774 0x2774 0x2774 0x2774 0x2774 0x2774 0x2774 0x2774 0x2774 0x2774 0x2774 0x2774 0x2774 0x2774 0x2774 0x2774 0x2774 0x2774 0x2774 0x2774 0x2774 0x2774 0x2774 0x2774 0x2774 0x2774 0x2774 0x2774 0x2774 0x2774 0x2774 0x2774 0x2774 0x2774 0x2774 0x2774 0x2774 0x2774 0x2774 0x2774 0x2774 0x2774 0x2774 0x2774 0x2774 0x2774 0x2774 0x2774 0x2774 0x2774 0x2774 0x2774 0x2774 0x2774 0x2774 0x2774 0x2774 0x2774 0x2774 0x2774 0x2774 0x2774 0x2774 0x2774 0x2774 0x2774 0x2774 0x2774 0x2774 0x2774 0x2774 0x2774 0x2774 0x2774 0x2774 0x2774 0x2774 0x2774 0x2774 0x2774 0x2774 0x2774 0x2774 0x2774 0x2774 0x2774 0x2774 0x2774 0x2774 0x2774 0x2774 0x2774 0x2774 0x2774 0x2774 0x2774 0x2774 0x2774 0x2774 0x2774 0x2774 0x2774 0x2774 0x2774 0x2774 0x2774 0x2774 0x2774 0x2774 0x2774 0x2774 0x2774 0x2774 0x2774 0x2774 0x2774 0x2774 0x2774 0x2774 0x2774 0x2774 0x2774 0x2774 0x2774 0x2774 0x2774 0x2774 0x2774 0x2774 0x2774 0x2774 0x2774 0x2774 0x2774 0x2774 0x2774 0x2774 0x2774 0x2774 0x2774 0x2774 0x2774 0x2774 0x2774 0x2774 0x2774 0x2774 0x2774 0x2774 0x2774 0x2774 0x2774 0x2774 0x2774 0x2774 0x2774 0x2774 0x2774 0x2774 0x2774 0x2774 0x2774 0x2774 0x2774 0x2774 0x2774 0x2774 0x2774 0x2774 0x2774 0x2774 0x2774 0x2774 0x2774 0x2774 0x2774 0x2774 0x2774 0x2774 0x2774 0x2774 0x2774 0x2774 0x2774 0x2774 0x2774 0x2774 0x2774 0x2774 0x2774 0x2774 0x2774 0x2774 0x2774 0x2774 0x2774 0x2774 0x2774 0x2774 0x2774 0x2774 0x2774 0x2774 0x2774 0x2774 0x2774 0x2774 0x2774 0x2774 0x2774 0x2774 0x2774 0x2774 0x2774 0x2774 0x2774 0x2774 0x2774 0x2774 0x2774 0x2774 0x2774 0x2774 0x2774 0x2774 0x2774 0x2774 0x2774 0x2774 0x2774 0x2774 0x2774 0x2774 0x2774 0x2774 0x2774 0x2774 0x2774 0x2774 0x2774 0x2774 0x2774 0x2774 0x2774 0x2774 0x2774 0x2774 0x2774 0x2774 0x2774 0x2774 0x2774 0x2774 0x2774 0x2774 0x2774 0x2774 0x2774 0x2774 0x2774 0x2774 0x2774 0x2774 0x2774 0x2774 0x2774 0x2774 0x2774 0x2774 0x2774 0x2774 0x2774 0x2774 0x2774 0x2774 0x2774 0x2774 0x2774 0x2774 0x2774 0x2774 0x2774 0x2774 0x2774 0x2774 0x2774 0x2774 0x2774 0x2774 0x2774 0x2774 0x2774 0x2774 0x2774 0x2774 0x2774 0x2774 0x2774 0x2774 0x2774 0x2774 0x2774 0x2774 0x2774 0x2774 0x2774 0x2774 0x2774 0x2774 0x2774 0x2774 0x2774 0x2774 0x2774 0x2774 0x2774 0x2774 0x2774 0x2774 0x2774 0x2774 0x2774 0x2774 0x2774 0x2774 0x2774 0x2774 0x2774 0x2774 0x2774 0x2774 0x2774 0x2774 0x2774 0x2774 0x2774 0x2774 0x2774 0x2774 0x2774 0x2774 0x2774 0x2774 0x2774 0x2774 0x2774 0x2774 0x2774 0x2774 0x2774 0x2774 0x2774 0x2774 0x2774 0x2774 0x2774 0x2774 0x2774 0x2774 0x2774 0x2774 0x2774 0x2774 0x2774 0x2774 0x2774 0x2774 0x2774 0x2774 0x2774 0x2774 0x2774 0x2774 0x2774 0x2774 0x2774 0x2774 0x2774 0x2774 0x2774 0x2774 0x2774 0x2774 0x2774 0x2774 0x2774 0x2774 0x2774 0x2774 0x2774 0x2774 0x2774 0x2774 0x2774 0x2774 0x2774 0x2774 0x2774 0x2774 0x2774 0x2774 0x2774 0x2774 0x2774 0x2774 0x2774 0x2774 0x2774 0x2774 0x2774 0x2774 0x2774 0x2774 0x2774 0x2774 0x2774 0x2774 0x2774 0x2774 0x2774 0x2774 0x2774 0x2774 0x2774 0x2774 0x2774 0x2774 0x2774 0x2774 0x2774 0x2774 0x2774 0x2774 0x2774 0x2774 0x2774 0x2774 0x2774 0x2774 0x2774 0x2774 0x2774 0x2774 0x2774 0x2774 0x2774 0x2774 0x2774 0x2774 0x2774 0x2774 0x2774 0x2774 0x2774 0x2774 0x2774 0x2774 0x2774 0x2774 0x2774 0x2774 0x2774 0x2774 0x2774 0x2774 0x2774 0x2774 0x2774 0x2774 0x2710 0x2710 0x2710>;
            PS_Config_Lmt_Short_Rawdata_P = <0x36b8 0x36b8 0x36b8 0x36b8 0x36b8 0x36b8 0x36b8 0x36b8 0x36b8 0x36b8 0x36b8 0x36b8 0x36b8 0x36b8 0x36b8 0x36b8 0x36b8 0x36b8 0x36b8 0x36b8 0x36b8 0x36b8 0x36b8 0x36b8 0x36b8 0x36b8 0x36b8 0x36b8 0x36b8 0x36b8 0x36b8 0x36b8 0x36b8 0x36b8 0x36b8 0x36b8 0x36b8 0x36b8 0x36b8 0x36b8 0x36b8 0x36b8 0x36b8 0x36b8 0x36b8 0x36b8 0x36b8 0x36b8 0x36b8 0x36b8 0x36b8 0x36b8 0x36b8 0x36b8 0x36b8 0x36b8 0x36b8 0x36b8 0x36b8 0x36b8 0x36b8 0x36b8 0x36b8 0x36b8 0x36b8 0x36b8 0x36b8 0x36b8 0x36b8 0x36b8 0x36b8 0x36b8 0x36b8 0x36b8 0x36b8 0x36b8 0x36b8 0x36b8 0x36b8 0x36b8 0x36b8 0x36b8 0x36b8 0x36b8 0x36b8 0x36b8 0x36b8 0x36b8 0x36b8 0x36b8 0x36b8 0x36b8 0x36b8 0x36b8 0x36b8 0x36b8 0x36b8 0x36b8 0x36b8 0x36b8 0x36b8 0x36b8 0x36b8 0x36b8 0x36b8 0x36b8 0x36b8 0x36b8 0x36b8 0x36b8 0x36b8 0x36b8 0x36b8 0x36b8 0x36b8 0x36b8 0x36b8 0x36b8 0x36b8 0x36b8 0x36b8 0x36b8 0x36b8 0x36b8 0x36b8 0x36b8 0x36b8 0x36b8 0x36b8 0x36b8 0x36b8 0x36b8 0x36b8 0x36b8 0x36b8 0x36b8 0x36b8 0x36b8 0x36b8 0x36b8 0x36b8 0x36b8 0x36b8 0x36b8 0x36b8 0x36b8 0x36b8 0x36b8 0x36b8 0x36b8 0x36b8 0x36b8 0x36b8 0x36b8 0x36b8 0x36b8 0x36b8 0x36b8 0x36b8 0x36b8 0x36b8 0x36b8 0x36b8 0x36b8 0x36b8 0x36b8 0x36b8 0x36b8 0x36b8 0x36b8 0x36b8 0x36b8 0x36b8 0x36b8 0x36b8 0x36b8 0x36b8 0x36b8 0x36b8 0x36b8 0x36b8 0x36b8 0x36b8 0x36b8 0x36b8 0x36b8 0x36b8 0x36b8 0x36b8 0x36b8 0x36b8 0x36b8 0x36b8 0x36b8 0x36b8 0x36b8 0x36b8 0x36b8 0x36b8 0x36b8 0x36b8 0x36b8 0x36b8 0x36b8 0x36b8 0x36b8 0x36b8 0x36b8 0x36b8 0x36b8 0x36b8 0x36b8 0x36b8 0x36b8 0x36b8 0x36b8 0x36b8 0x36b8 0x36b8 0x36b8 0x36b8 0x36b8 0x36b8 0x36b8 0x36b8 0x36b8 0x36b8 0x36b8 0x36b8 0x36b8 0x36b8 0x36b8 0x36b8 0x36b8 0x36b8 0x36b8 0x36b8 0x36b8 0x36b8 0x36b8 0x36b8 0x36b8 0x36b8 0x36b8 0x36b8 0x36b8 0x36b8 0x36b8 0x36b8 0x36b8 0x36b8 0x36b8 0x36b8 0x36b8 0x36b8 0x36b8 0x36b8 0x36b8 0x36b8 0x36b8 0x36b8 0x36b8 0x36b8 0x36b8 0x36b8 0x36b8 0x36b8 0x36b8 0x36b8 0x36b8 0x36b8 0x36b8 0x36b8 0x36b8 0x36b8 0x36b8 0x36b8 0x36b8 0x36b8 0x36b8 0x36b8 0x36b8 0x36b8 0x36b8 0x36b8 0x36b8 0x36b8 0x36b8 0x36b8 0x36b8 0x36b8 0x36b8 0x36b8 0x36b8 0x36b8 0x36b8 0x36b8 0x36b8 0x36b8 0x36b8 0x36b8 0x36b8 0x36b8 0x36b8 0x36b8 0x36b8 0x36b8 0x36b8 0x36b8 0x36b8 0x36b8 0x36b8 0x36b8 0x36b8 0x36b8 0x36b8 0x36b8 0x36b8 0x36b8 0x36b8 0x36b8 0x36b8 0x36b8 0x36b8 0x36b8 0x36b8 0x36b8 0x36b8 0x36b8 0x36b8 0x36b8 0x36b8 0x36b8 0x36b8 0x36b8 0x36b8 0x36b8 0x36b8 0x36b8 0x36b8 0x36b8 0x36b8 0x36b8 0x36b8 0x36b8 0x36b8 0x36b8 0x36b8 0x36b8 0x36b8 0x36b8 0x36b8 0x36b8 0x36b8 0x36b8 0x36b8 0x36b8 0x36b8 0x36b8 0x36b8 0x36b8 0x36b8 0x36b8 0x36b8 0x36b8 0x36b8 0x36b8 0x36b8 0x36b8 0x36b8 0x36b8 0x36b8 0x36b8 0x36b8 0x36b8 0x36b8 0x36b8 0x36b8 0x36b8 0x36b8 0x36b8 0x36b8 0x36b8 0x36b8 0x36b8 0x36b8 0x36b8 0x36b8 0x36b8 0x36b8 0x36b8 0x36b8 0x36b8 0x36b8 0x36b8 0x36b8 0x36b8 0x36b8 0x36b8 0x36b8 0x36b8 0x36b8 0x36b8 0x36b8 0x36b8 0x36b8 0x36b8 0x36b8 0x36b8 0x36b8 0x36b8 0x36b8 0x36b8 0x36b8 0x36b8 0x36b8 0x36b8 0x36b8 0x36b8 0x36b8 0x36b8 0x36b8 0x36b8 0x36b8 0x36b8 0x36b8 0x36b8 0x36b8 0x36b8 0x36b8 0x36b8 0x36b8 0x36b8 0x36b8 0x36b8 0x36b8 0x36b8 0x36b8 0x36b8 0x36b8 0x36b8 0x36b8 0x36b8 0x36b8 0x36b8 0x36b8 0x36b8 0x36b8 0x36b8 0x36b8 0x36b8 0x36b8 0x36b8 0x36b8 0x36b8 0x36b8 0x36b8 0x36b8 0x36b8 0x36b8 0x36b8 0x36b8 0x36b8 0x36b8 0x36b8 0x36b8 0x36b8 0x36b8 0x36b8 0x36b8 0x36b8 0x36b8 0x36b8 0x36b8 0x36b8 0x36b8 0x36b8 0x36b8 0x36b8 0x36b8 0x36b8 0x36b8 0x36b8 0x36b8 0x36b8 0x36b8 0x36b8 0x36b8 0x36b8 0x36b8 0x36b8 0x36b8 0x36b8 0x36b8 0x36b8 0x36b8 0x36b8 0x36b8 0x36b8 0x36b8 0x36b8 0x36b8 0x36b8 0x36b8 0x36b8 0x36b8 0x36b8 0x36b8 0x36b8 0x36b8 0x36b8 0x36b8 0x36b8 0x36b8 0x36b8 0x36b8 0x36b8 0x36b8 0x36b8 0x36b8 0x36b8 0x36b8 0x36b8 0x36b8 0x36b8 0x36b8 0x36b8 0x36b8 0x36b8 0x36b8 0x36b8 0x36b8 0x36b8 0x36b8 0x36b8 0x36b8 0x36b8 0x36b8 0x36b8 0x36b8 0x36b8 0x36b8 0x36b8 0x36b8 0x36b8 0x36b8 0x36b8 0x36b8 0x36b8 0x36b8 0x36b8 0x36b8 0x36b8 0x36b8 0x36b8 0x36b8 0x36b8 0x36b8 0x36b8 0x36b8 0x36b8 0x36b8 0x36b8 0x36b8 0x36b8 0x36b8 0x36b8 0x36b8 0x36b8 0x36b8 0x36b8 0x36b8 0x36b8 0x36b8 0x36b8 0x36b8 0x36b8 0x36b8 0x36b8 0x36b8 0x36b8 0x36b8 0x36b8 0x36b8 0x36b8 0x36b8 0x36b8 0x36b8 0x36b8 0x36b8 0x36b8 0x36b8 0x36b8 0x36b8 0x36b8 0x36b8 0x36b8 0x36b8 0x36b8 0x36b8 0x36b8 0x36b8 0x36b8 0x36b8 0x36b8 0x36b8 0x36b8 0x36b8 0x36b8 0x36b8 0x36b8 0x36b8 0x36b8 0x36b8 0x36b8 0x36b8 0x36b8 0x36b8 0x36b8 0x36b8 0x36b8 0x36b8 0x36b8 0x36b8 0x36b8 0x36b8 0x36b8 0x36b8 0x36b8 0x36b8 0x36b8 0x36b8 0x36b8 0x36b8 0x36b8 0x36b8 0x36b8 0x36b8 0x36b8 0x36b8 0x36b8 0x36b8 0x36b8 0x36b8 0x36b8 0x36b8 0x36b8 0x36b8 0x36b8 0x36b8 0x36b8 0x36b8 0x36b8 0x36b8 0x36b8 0x36b8 0x36b8 0x36b8 0x36b8 0x36b8 0x36b8 0x36b8 0x36b8 0x36b8 0x36b8 0x36b8 0x36b8 0x36b8 0x36b8 0x36b8 0x36b8 0x36b8 0x36b8 0x36b8 0x36b8 0x36b8 0x36b8 0x36b8 0x36b8 0x36b8 0x36b8 0x36b8 0x36b8 0x36b8 0x36b8 0x36b8 0x36b8 0x36b8 0x36b8 0x36b8 0x36b8 0x36b8 0x36b8 0x36b8 0x36b8 0x36b8 0x36b8 0x36b8 0x36b8 0x36b8 0x36b8 0x36b8 0x36b8 0x36b8 0x36b8 0x36b8 0x36b8 0x36b8 0x36b8 0x36b8 0x36b8 0x36b8 0x36b8 0x36b8 0x36b8 0x36b8 0x36b8 0x36b8 0x36b8 0x36b8 0x36b8 0x36b8 0x36b8 0x36b8 0x36b8 0x36b8 0x36b8 0x36b8 0x36b8 0x36b8 0x36b8 0x36b8 0x36b8 0x36b8 0x36b8 0x36b8 0x36b8 0x36b8 0x36b8 0x36b8 0x36b8 0x36b8 0x36b8 0x36b8 0x36b8 0x36b8 0x36b8 0x36b8 0x36b8 0x36b8 0x36b8 0x36b8 0x36b8 0x36b8 0x36b8 0x36b8 0x36b8 0x36b8 0x36b8 0x36b8 0x36b8 0x36b8 0x36b8 0x36b8 0x36b8 0x36b8 0x36b8 0x36b8 0x36b8 0x36b8 0x36b8 0x36b8 0x36b8 0x36b8 0x36b8 0x36b8 0x36b8 0x36b8 0x36b8 0x36b8 0x36b8 0x36b8 0x36b8 0x36b8 0x36b8 0x36b8 0x36b8 0x36b8 0x36b8 0x36b8 0x36b8 0x36b8 0x36b8 0x36b8 0x36b8 0x36b8 0x36b8 0x36b8 0x36b8 0x36b8 0x36b8 0x36b8 0x36b8 0x36b8 0x36b8 0x36b8 0x36b8 0x36b8 0x36b8 0x36b8 0x36b8 0x36b8 0x36b8 0x36b8 0x36b8 0x36b8 0x36b8 0x36b8 0x36b8 0x36b8 0x36b8 0x36b8 0x36b8 0x36b8 0x36b8 0x36b8 0x36b8 0x36b8 0x36b8 0x36b8 0x36b8 0x36b8 0x36b8 0x36b8 0x36b8 0x36b8 0x36b8 0x36b8 0x36b8 0x36b8 0x36b8 0x36b8 0x36b8 0x36b8 0x36b8 0x36b8 0x36b8 0x36b8 0x36b8 0x36b8 0x36b8 0x36b8 0x36b8 0x36b8 0x36b8 0x36b8 0x36b8 0x36b8 0x36b8 0x36b8 0x36b8 0x36b8 0x36b8 0x36b8 0x36b8 0x36b8 0x36b8 0x36b8 0x36b8 0x36b8 0x36b8 0x36b8 0x36b8 0x36b8 0x36b8 0x36b8 0x36b8 0x36b8 0x36b8 0x36b8 0x36b8 0x36b8 0x36b8 0x36b8 0x36b8 0x36b8 0x36b8 0x36b8 0x36b8 0x36b8 0x36b8 0x36b8 0x36b8 0x36b8 0x36b8 0x36b8 0x36b8 0x36b8 0x36b8 0x36b8 0x36b8 0x36b8 0x36b8 0x36b8 0x36b8 0x36b8 0x36b8 0x36b8 0x36b8 0x36b8 0x36b8 0x36b8 0x36b8 0x36b8 0x36b8 0x36b8 0x36b8 0x36b8 0x36b8 0x36b8 0x36b8 0x36b8 0x36b8 0x36b8 0x36b8 0x36b8 0x36b8 0x36b8 0x36b8 0x36b8 0x36b8 0x36b8 0x36b8 0x36b8 0x36b8 0x36b8 0x36b8 0x36b8 0x36b8 0x36b8 0x36b8 0x36b8 0x36b8 0x36b8 0x36b8 0x36b8 0x36b8 0x36b8 0x36b8 0x36b8 0x36b8 0x36b8 0x36b8 0x36b8 0x36b8 0x36b8 0x36b8 0x36b8 0x36b8 0x36b8 0x36b8 0x36b8 0x36b8 0x36b8 0x36b8 0x36b8 0x36b8 0x36b8 0x36b8 0x36b8 0x36b8 0x36b8 0x36b8 0x36b8 0x36b8 0x36b8 0x36b8 0x36b8 0x36b8 0x36b8 0x36b8 0x36b8 0x36b8 0x36b8 0x36b8 0x36b8 0x36b8 0x36b8 0x36b8 0x36b8 0x36b8 0x36b8 0x36b8 0x36b8 0x36b8 0x36b8 0x36b8 0x36b8 0x36b8 0x36b8 0x36b8 0x36b8 0x36b8 0x36b8 0x36b8 0x36b8 0x36b8 0x36b8 0x36b8 0x36b8 0x36b8 0x36b8 0x36b8 0x36b8 0x36b8 0x36b8 0x36b8 0x36b8 0x36b8 0x36b8 0x36b8 0x36b8 0x36b8 0x36b8 0x36b8 0x36b8 0x36b8 0x36b8 0x36b8 0x36b8 0x36b8 0x36b8 0x36b8 0x36b8 0x36b8 0x36b8 0x36b8 0x36b8 0x36b8 0x36b8 0x36b8 0x36b8 0x36b8 0x36b8 0x36b8 0x36b8 0x36b8 0x36b8 0x36b8 0x36b8 0x36b8 0x36b8 0x36b8 0x36b8 0x36b8 0x36b8 0x36b8 0x36b8 0x36b8 0x36b8 0x36b8 0x36b8 0x36b8 0x36b8 0x36b8 0x36b8 0x36b8 0x36b8 0x36b8 0x36b8 0x36b8 0x36b8 0x36b8 0x36b8 0x36b8 0x36b8 0x36b8 0x36b8 0x36b8 0x36b8 0x36b8 0x36b8 0x36b8 0x36b8 0x36b8 0x36b8 0x36b8 0x36b8 0x36b8 0x36b8 0x36b8 0x36b8 0x36b8 0x36b8 0x36b8 0x36b8 0x36b8 0x36b8 0x36b8 0x36b8 0x36b8 0x36b8 0x36b8 0x36b8 0x36b8 0x36b8 0x36b8 0x36b8 0x36b8 0x36b8 0x36b8 0x36b8 0x36b8 0x36b8 0x36b8 0x36b8 0x36b8 0x36b8 0x36b8 0x36b8 0x36b8 0x36b8 0x36b8 0x36b8 0x36b8 0x36b8 0x36b8 0x36b8 0x36b8 0x36b8 0x36b8 0x36b8 0x36b8 0x36b8 0x36b8 0x36b8 0x36b8 0x36b8 0x36b8 0x36b8 0x36b8 0x36b8 0x36b8 0x36b8 0x36b8 0x36b8 0x36b8 0x36b8 0x36b8 0x36b8 0x36b8 0x36b8 0x36b8 0x36b8 0x36b8 0x36b8 0x36b8 0x36b8 0x36b8 0x36b8 0x36b8 0x36b8 0x36b8 0x36b8 0x36b8 0x36b8 0x36b8 0x36b8 0x36b8 0x36b8 0x36b8 0x36b8 0x36b8 0x36b8 0x36b8 0x36b8 0x36b8 0x36b8 0x36b8 0x36b8 0x36b8 0x36b8 0x36b8 0x36b8 0x36b8 0x36b8 0x36b8 0x36b8 0x36b8 0x36b8 0x36b8 0x36b8 0x36b8 0x36b8 0x36b8 0x36b8 0x36b8 0x36b8 0x36b8 0x36b8 0x36b8 0x36b8 0x36b8 0x36b8 0x36b8 0x36b8 0x36b8 0x36b8 0x36b8 0x36b8 0x36b8 0x36b8 0x36b8 0x36b8 0x36b8 0x36b8 0x36b8 0x36b8 0x36b8 0x36b8 0x36b8 0x36b8 0x36b8 0x36b8 0x36b8 0x36b8 0x36b8 0x36b8 0x36b8 0x36b8 0x36b8 0x36b8 0x36b8 0x36b8 0x36b8 0x36b8 0x36b8 0x36b8 0x36b8 0x36b8 0x36b8 0x36b8 0x36b8 0x36b8 0x36b8 0x36b8 0x36b8 0x36b8 0x36b8 0x36b8 0x36b8 0x36b8 0x36b8 0x36b8 0x36b8 0x36b8 0x36b8 0x36b8 0x36b8 0x36b8 0x36b8 0x36b8 0x36b8 0x36b8 0x36b8 0x36b8 0x36b8 0x36b8 0x36b8 0x36b8 0x36b8 0x36b8 0x36b8 0x36b8 0x36b8 0x36b8 0x36b8 0x36b8 0x36b8 0x36b8 0x36b8 0x36b8 0x36b8 0x36b8 0x36b8 0x36b8 0x36b8 0x36b8 0x36b8 0x36b8 0x36b8 0x36b8 0x36b8 0x36b8 0x36b8 0x36b8 0x36b8 0x36b8 0x36b8 0x36b8 0x36b8 0x36b8 0x36b8 0x36b8 0x36b8 0x36b8 0x36b8 0x36b8 0x36b8 0x36b8 0x36b8 0x36b8 0x36b8 0x36b8 0x36b8 0x36b8 0x36b8 0x36b8 0x36b8 0x36b8 0x36b8 0x36b8 0x36b8 0x36b8 0x36b8 0x36b8 0x36b8 0x36b8 0x36b8 0x36b8 0x36b8 0x36b8 0x36b8 0x36b8 0x36b8 0x36b8 0x36b8 0x36b8 0x36b8 0x36b8 0x36b8 0x36b8 0x36b8 0x36b8 0x36b8 0x36b8 0x36b8 0x36b8 0x36b8 0x36b8 0x36b8 0x36b8 0x36b8 0x36b8 0x36b8 0x36b8 0x36b8 0x36b8 0x36b8 0x36b8 0x36b8 0x36b8 0x36b8 0x36b8 0x36b8 0x36b8 0x36b8 0x36b8 0x36b8 0x36b8 0x36b8 0x36b8 0x36b8 0x36b8 0x36b8 0x36b8 0x36b8 0x36b8 0x36b8 0x36b8 0x36b8 0x36b8 0x36b8 0x36b8 0x36b8 0x36b8 0x36b8 0x36b8 0x36b8 0x36b8 0x36b8 0x36b8 0x36b8 0x36b8 0x36b8 0x36b8 0x36b8 0x36b8 0x36b8 0x36b8 0x36b8 0x36b8 0x36b8 0x36b8 0x36b8 0x36b8 0x36b8 0x36b8 0x36b8 0x36b8 0x36b8 0x36b8 0x36b8 0x36b8 0x36b8 0x36b8 0x36b8 0x36b8 0x36b8 0x36b8 0x36b8 0x36b8 0x36b8 0x36b8 0x36b8 0x36b8 0x36b8 0x36b8 0x36b8 0x36b8 0x36b8 0x36b8 0x36b8 0x36b8 0x36b8 0x36b8 0x36b8 0x36b8 0x36b8 0x36b8 0x36b8 0x36b8 0x36b8 0x36b8 0x36b8 0x36b8 0x36b8 0x36b8 0x36b8 0x36b8 0x36b8 0x36b8 0x36b8 0x36b8 0x36b8 0x36b8 0x36b8 0x36b8 0x36b8 0x36b8 0x36b8 0x36b8 0x36b8 0x36b8 0x36b8 0x36b8 0x36b8 0x36b8 0x36b8 0x36b8 0x36b8 0x36b8 0x36b8 0x36b8 0x36b8 0x36b8 0x36b8 0x36b8 0x36b8 0x36b8 0x36b8 0x36b8 0x36b8 0x36b8 0x36b8 0x36b8 0x36b8 0x36b8 0x36b8 0x36b8 0x36b8 0x36b8 0x36b8 0x36b8 0x36b8 0x36b8 0x36b8 0x36b8 0x36b8 0x36b8 0x36b8 0x36b8 0x36b8 0x36b8 0x36b8 0x36b8 0x36b8 0x36b8 0x36b8 0x36b8 0x36b8 0x36b8 0x36b8 0x36b8 0x36b8 0x36b8 0x36b8 0x36b8 0x36b8 0x36b8 0x36b8 0x36b8 0x36b8 0x36b8 0x36b8 0x36b8 0x36b8 0x36b8 0x36b8 0x36b8 0x36b8 0x36b8 0x36b8 0x36b8 0x36b8 0x36b8 0x36b8 0x36b8 0x36b8 0x36b8 0x36b8 0x36b8 0x36b8 0x36b8 0x36b8 0x36b8 0x36b8 0x36b8 0x36b8 0x36b8 0x36b8 0x36b8 0x36b8 0x36b8 0x36b8 0x36b8 0x36b8 0x36b8 0x36b8 0x36b8 0x36b8 0x36b8 0x36b8 0x36b8 0x36b8 0x36b8 0x36b8 0x36b8 0x36b8 0x36b8 0x36b8 0x36b8 0x36b8 0x36b8 0x36b8 0x36b8 0x36b8 0x36b8 0x36b8 0x36b8 0x36b8 0x36b8 0x36b8 0x36b8 0x36b8 0x36b8 0x36b8 0x36b8 0x36b8 0x36b8 0x36b8 0x36b8 0x36b8 0x36b8 0x36b8 0x36b8 0x36b8 0x36b8 0x36b8 0x36b8 0x36b8 0x36b8 0x36b8>;
            AIN_KEY = <0x00 0x01 0x02 0xff>;
            AIN_Y = <0x00 0x01 0x02 0x03 0x04 0x05 0x06 0x07 0x08 0x09 0x0a 0x0b 0x0c 0x0d 0x0e 0x0f 0x10 0x11 0x12 0x13 0x14 0x15 0x16 0x17 0x18 0x19 0x1a 0x1b 0x1c 0x1d 0x1e 0x1f 0x20 0x21 0x22 0x23 0x24 0x25 0x26 0x27 0x28 0x29 0x2a 0x2b 0x2c 0x2d 0x2e 0x2f 0x30 0x31>;
            AIN_X = <0x00 0x01 0x02 0x03 0x04 0x05 0x06 0x07 0x08 0x09 0x0a 0x0b 0x0c 0x0d 0x0e 0x0f 0x10 0x11 0x12 0x13 0x14 0x15 0x16 0x17 0x18 0x19 0x1a 0x1b 0x1c 0x1d 0x1e 0x1f>;
            Y_Channel = <0x32>;
            X_Channel = <0x20>;
            IC_KEY_CFG_SIZE = <0x04>;
            IC_Y_CFG_SIZE = <0x32>;
            IC_X_CFG_SIZE = <0x20>;
            compatible = "novatek-mp-criteria-597A";
            #size-cells = <0x00>;
            #address-cells = <0x01>;
        };
    };
};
